VERSION "HNNBNNNYNNNNNNNNNNNNNNNNNNNNNNNNNNNNNNNNNN/4/%%%/4/'%**4NNN///"

NS_ :

BS_:

BU_: ecu_pri3_1 ecu_pri3_2 ecu_sec1_1 ecu_pri1_1 ecu_sec1_2 unused_8 unused_2 ecu_sec3_2 ecu_sec3_1 unused_1 unused_4 unused_9 unused_3 ecu_pri3_3 unused_6 unused_5 unused_7 measure

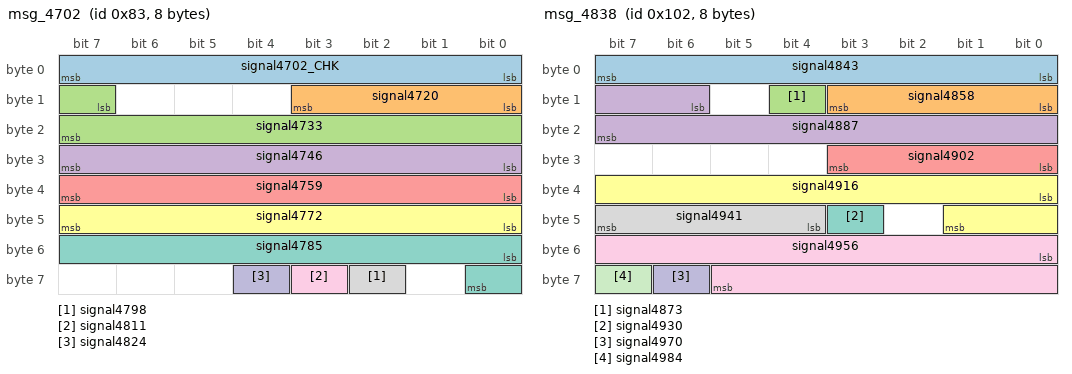
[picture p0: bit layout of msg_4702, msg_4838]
BO_ 131 msg_4702: 8 ecu_sec1_2
 SG_ signal4702_CHK : 0|8@1+ (1,0) [0|255] ""  ecu_sec3_1,unused_1,unused_4,measure
 SG_ signal4720 : 8|4@1+ (1,0) [0|15] ""  ecu_sec3_1,unused_1,unused_4,measure
 SG_ signal4733 : 15|9@1+ (25,0) [0|12750] "1/min"  ecu_sec3_1,unused_1,unused_4,measure
 SG_ signal4746 : 24|8@1+ (20,0) [0|5080] "ms"  ecu_sec3_1,unused_1,unused_4,measure
 SG_ signal4759 : 32|8@1+ (10,0) [0|2540] "Nm/s"  ecu_sec3_1,unused_1,unused_4,measure
 SG_ signal4772 : 40|8@1+ (10,0) [0|2540] "1/min"  ecu_sec3_1,unused_1,unused_4,measure
 SG_ signal4785 : 48|9@1+ (1,0) [0|509] ""  ecu_sec3_1,unused_1,unused_4,measure
 SG_ signal4798 : 58|1@1+ (1,0) [0|1] ""  ecu_sec3_1,unused_1,unused_4,measure
 SG_ signal4811 : 59|1@1+ (1,0) [0|1] ""  ecu_sec3_1,unused_1,unused_4,measure
 SG_ signal4824 : 60|1@1+ (1,0) [0|1] ""  ecu_sec3_1,unused_1,unused_4,measure

BO_ 258 msg_4838: 8 ecu_sec1_2
 SG_ signal4843 : 0|8@1+ (1,0) [0|255] ""  ecu_pri3_2,ecu_pri1_1,ecu_sec3_1,unused_1,unused_4,measure
 SG_ signal4858 : 8|4@1+ (1,0) [0|15] ""  ecu_pri3_2,ecu_pri1_1,ecu_sec3_1,unused_1,unused_4,measure
 SG_ signal4873 : 12|1@1+ (1,0) [0|1] ""  ecu_pri1_1,ecu_sec3_1,unused_1,unused_4,measure
 SG_ signal4887 : 14|10@1+ (0.1,0) [0|102.2] ""  ecu_pri3_2,ecu_pri1_1,ecu_sec3_1,unused_1,unused_4,measure
 SG_ signal4902 : 24|4@1+ (1,0) [0|15] ""  ecu_pri1_1,ecu_sec3_1,unused_1,unused_4,measure
 SG_ signal4916 : 32|10@1+ (1,0) [0|1021] ""  ecu_pri1_1,ecu_sec3_1,unused_1,unused_4,measure
 SG_ signal4930 : 43|1@1+ (1,0) [0|1] ""  ecu_pri1_1,measure
 SG_ signal4941 : 44|4@1+ (1,0) [0|15] ""  ecu_pri3_2,ecu_pri1_1,ecu_sec3_1,unused_1,unused_4,measure
 SG_ signal4956 : 48|14@1+ (1,0) [0|16381] "1/min"  ecu_pri1_1,ecu_sec3_1,unused_1,unused_4,measure
 SG_ signal4970 : 62|1@1+ (1,0) [0|1] ""  ecu_pri1_1,ecu_sec3_1,unused_1,unused_4,measure
 SG_ signal4984 : 63|1@1+ (1,0) [0|1] ""  ecu_pri3_2,ecu_pri1_1,measure

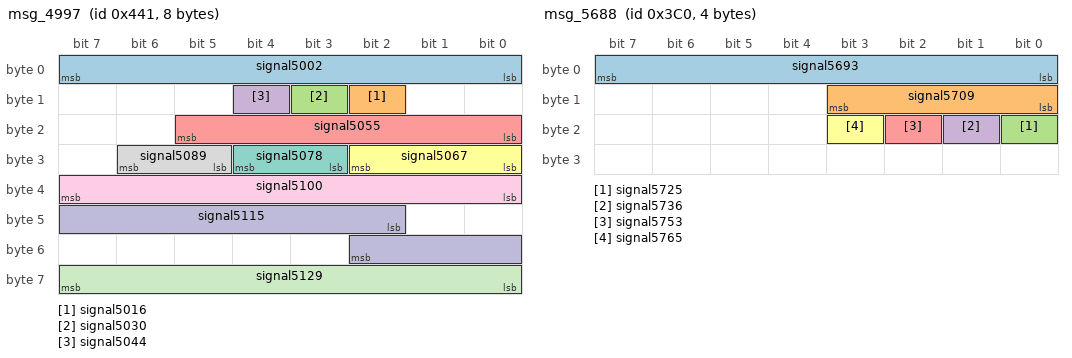
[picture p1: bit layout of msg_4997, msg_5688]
BO_ 1089 msg_4997: 8 ecu_sec1_2
 SG_ signal5002 : 0|8@1+ (0.249,-31.623) [-31.62301|31.62045] ""  ecu_pri1_1,ecu_sec3_1,unused_1,unused_4,measure
 SG_ signal5016 : 10|1@1+ (1,0) [0|1] ""  ecu_pri1_1,ecu_sec3_1,unused_1,unused_4,measure
 SG_ signal5030 : 11|1@1+ (1,0) [0|1] ""  ecu_pri1_1,ecu_sec3_1,unused_1,unused_4,measure
 SG_ signal5044 : 12|1@1+ (1,0) [0|1] ""  ecu_pri1_1,measure
 SG_ signal5055 : 16|6@1+ (2,0) [0|122] ""  ecu_pri3_2,ecu_pri1_1,measure
 SG_ signal5067 : 24|3@1+ (1,0) [0|7] ""  ecu_pri1_1,measure
 SG_ signal5078 : 27|2@1+ (1,0) [0|3] ""  ecu_pri1_1,measure
 SG_ signal5089 : 29|2@1+ (1,0) [0|3] ""  ecu_pri1_1,measure
 SG_ signal5100 : 32|8@1+ (1,0) [0|254] ""  ecu_pri3_2,ecu_pri1_1,ecu_sec3_1,unused_1,unused_4,measure
 SG_ signal5115 : 42|9@1+ (0.024,-2.016) [-2.01601|10.22399] "signal5121"  ecu_pri1_1,ecu_sec3_1,unused_1,unused_4,measure
 SG_ signal5129 : 56|8@1+ (1,-58) [-58|196] "Celsius"  ecu_pri1_1,ecu_sec3_1,unused_1,unused_4,measure

BO_ 1813 msg_5144: 8 ecu_pri1_1
 SG_ signal5144_Data : 0|64@1+ (1,0) [0|1] ""  ecu_pri3_1,measure

BO_ 1792 msg_5178: 8 ecu_pri1_1
 SG_ signal5183 : 0|64@1+ (1,0) [0|1] ""  ecu_pri3_1,ecu_sec1_2,unused_8,unused_2,ecu_sec3_1,unused_1,unused_4,unused_9,unused_5,measure

BO_ 2015 msg_5203: 8 ecu_pri1_1
 SG_ signal5208 : 0|64@1+ (1,0) [0|1] ""  ecu_pri3_1,ecu_sec1_2,unused_8,unused_2,ecu_sec3_1,unused_1,unused_4,unused_9,measure

BO_ 2017 msg_5227: 8 ecu_pri1_1
 SG_ signal5227_Data : 0|64@1+ (1,0) [0|1] ""  ecu_sec1_2,unused_8,unused_2,measure

BO_ 2025 msg_5246: 8 ecu_sec1_2
 SG_ signal5251 : 0|64@1+ (1,0) [0|1] ""  ecu_pri1_1,measure

BO_ 2016 msg_5263: 8 ecu_pri1_1
 SG_ signal5263_Data : 0|64@1+ (1,0) [0|1] ""  ecu_sec3_1,unused_1,unused_4,measure

BO_ 2024 msg_5282: 8 ecu_sec3_1
 SG_ signal5282_Data : 0|64@1+ (1,0) [0|1] ""  ecu_pri1_1,measure

BO_ 2018 msg_5299: 8 ecu_pri1_1
 SG_ signal5304 : 0|64@1+ (1,0) [0|1] ""  unused_9,measure

BO_ 2026 msg_5316: 8 unused_9
 SG_ signal5321 : 0|64@1+ (1,0) [0|1] ""  ecu_pri1_1,measure

BO_ 2019 msg_5333: 8 ecu_pri1_1
 SG_ signal5333_Data : 0|64@1+ (1,0) [0|1] ""  unused_7,measure

BO_ 2027 msg_5349: 8 unused_7
 SG_ signal5349_Data : 0|64@1+ (1,0) [0|1] ""  ecu_pri1_1,measure

BO_ 1875 msg_5366: 8 ecu_pri1_1
 SG_ signal5371 : 0|64@1+ (1,0) [0|1] ""  unused_5,measure

BO_ 1981 msg_5383: 8 unused_5
 SG_ signal5388 : 0|64@1+ (1,0) [0|1] ""  ecu_pri1_1,measure

BO_ 1424 msg_5400: 8 ecu_pri1_1
 SG_ signal5405 : 0|4@1+ (1,0) [0|15] ""  unused_7,measure
 SG_ signal5415 : 4|1@1+ (1,0) [0|1] ""  unused_7,measure
 SG_ signal5425 : 5|1@1+ (1,0) [0|1] ""  unused_7,measure
 SG_ signal5435 : 6|2@1+ (1,0) [0|3] ""  unused_7,measure
 SG_ signal5445 : 8|1@1+ (1,0) [0|1] ""  unused_7,measure
 SG_ signal5455 : 9|1@1+ (1,0) [0|1] ""  unused_7,measure
 SG_ signal5465 : 10|1@1+ (1,0) [0|1] ""  ecu_pri3_2,measure
 SG_ signal5476 : 11|1@1+ (1,0) [0|1] ""  ecu_pri3_2,measure
 SG_ signal5487 : 12|1@1+ (1,0) [0|1] ""  unused_7,measure
 SG_ signal5497 : 14|1@1+ (1,0) [0|1] ""  unused_7,measure
 SG_ signal5507 : 15|1@1+ (1,0) [0|1] ""  unused_7,measure
 SG_ signal5517 : 16|3@1+ (1,0) [0|7] ""  unused_7,measure
 SG_ signal5527 : 19|1@1+ (1,0) [0|1] ""  unused_7,measure
 SG_ signal5537 : 20|1@1+ (1,0) [0|1] ""  unused_7,measure
 SG_ signal5547 : 21|1@1+ (1,0) [0|1] ""  unused_7,measure
 SG_ signal5557 : 22|1@1+ (1,0) [0|1] ""  unused_7,measure
 SG_ signal5567 : 23|1@1+ (1,0) [0|1] ""  unused_7,measure
 SG_ signal5577 : 24|3@1+ (1,0) [0|7] ""  unused_7,measure
 SG_ signal5587 : 27|1@1+ (1,0) [0|1] ""  unused_7,measure
 SG_ signal5597 : 28|1@1+ (1,0) [0|1] ""  unused_7,measure
 SG_ signal5607 : 29|1@1+ (1,0) [0|1] ""  unused_7,measure
 SG_ signal5617 : 30|1@1+ (1,0) [0|1] ""  unused_7,measure
 SG_ signal5627 : 31|1@1+ (1,0) [0|1] ""  unused_7,measure
 SG_ signal5637 : 32|4@1+ (1,0) [0|15] ""  unused_7,measure
 SG_ signal5647 : 36|4@1+ (1,0) [0|15] ""  unused_7,measure
 SG_ signal5657 : 40|1@1+ (1,0) [0|1] ""  unused_7,measure
 SG_ signal5667 : 41|2@1+ (1,0) [0|3] ""  unused_7,measure
 SG_ signal5677 : 47|1@1+ (1,0) [0|1] ""  unused_7,measure

BO_ 960 msg_5688: 4 ecu_pri1_1
 SG_ signal5693 : 0|8@1+ (1,0) [0|255] ""  ecu_pri3_2,ecu_sec1_2,unused_8,ecu_sec3_1,unused_1,unused_4,measure
 SG_ signal5709 : 8|4@1+ (1,0) [0|15] ""  ecu_pri3_2,ecu_sec1_2,unused_8,ecu_sec3_1,unused_1,unused_4,measure
 SG_ signal5725 : 16|1@1+ (1,0) [0|1] ""  ecu_pri3_2,measure
 SG_ signal5736 : 17|1@1+ (1,0) [0|1] ""  ecu_pri3_2,ecu_sec1_2,unused_8,ecu_sec3_1,unused_1,unused_4,unused_6,measure
 SG_ signal5753 : 18|1@1+ (1,0) [0|1] ""  ecu_pri3_2,unused_6,measure
 SG_ signal5765 : 19|1@1+ (1,0) [0|1] ""  ecu_pri3_2,ecu_sec3_1,unused_1,unused_4,measure

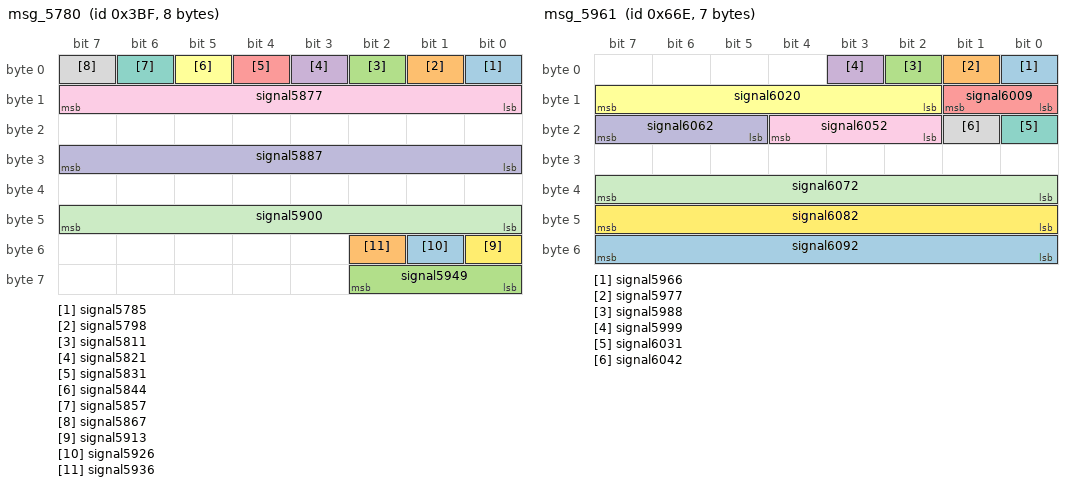
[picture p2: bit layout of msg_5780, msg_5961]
BO_ 959 msg_5780: 8 ecu_pri1_1
 SG_ signal5785 : 0|1@1+ (1,0) [0|1] ""  ecu_sec3_1,unused_1,unused_4,measure
 SG_ signal5798 : 1|1@1+ (1,0) [0|1] ""  ecu_sec3_1,unused_1,unused_4,measure
 SG_ signal5811 : 2|1@1+ (1,0) [0|1] ""  unused_7,measure
 SG_ signal5821 : 3|1@1+ (1,0) [0|1] ""  unused_7,measure
 SG_ signal5831 : 4|1@1+ (1,0) [0|1] ""  ecu_sec3_1,unused_1,unused_4,measure
 SG_ signal5844 : 5|1@1+ (1,0) [0|1] ""  ecu_sec3_1,unused_1,unused_4,measure
 SG_ signal5857 : 6|1@1+ (1,0) [0|1] ""  unused_7,measure
 SG_ signal5867 : 7|1@1+ (1,0) [0|1] ""  unused_7,measure
 SG_ signal5877 : 8|8@1+ (11,0) [0|2805] "W"  unused_7,measure
 SG_ signal5887 : 24|8@1+ (0.25,0) [0|63.5] "Nm"  ecu_sec3_1,unused_1,unused_4,measure
 SG_ signal5900 : 40|8@1+ (0.4,0) [0|101.6] "%"  ecu_sec3_1,unused_1,unused_4,measure
 SG_ signal5913 : 48|1@1+ (1,0) [0|1] ""  ecu_sec3_1,unused_1,unused_4,measure
 SG_ signal5926 : 49|1@1+ (1,0) [0|1] ""  unused_7,measure
 SG_ signal5936 : 50|1@1+ (1,0) [0|1] ""  ecu_sec3_1,unused_1,unused_4,measure
 SG_ signal5949 : 56|3@1+ (1,0) [0|7] ""  ecu_sec3_1,measure

BO_ 1646 msg_5961: 7 ecu_pri1_1
 SG_ signal5966 : 0|1@1+ (1,0) [0|1] ""  unused_6,measure
 SG_ signal5977 : 1|1@1+ (1,0) [0|1] ""  unused_6,measure
 SG_ signal5988 : 2|1@1+ (1,0) [0|1] ""  unused_6,measure
 SG_ signal5999 : 3|1@1+ (1,0) [0|1] ""  unused_7,measure
 SG_ signal6009 : 8|2@1+ (1,0) [0|3] ""  unused_6,measure
 SG_ signal6020 : 10|6@1+ (1,0) [0|60] "min"  unused_6,measure
 SG_ signal6031 : 16|1@1+ (1,0) [0|1] ""  unused_6,measure
 SG_ signal6042 : 17|1@1+ (1,0) [0|1] ""  unused_7,measure
 SG_ signal6052 : 18|3@1+ (1,0) [0|7] ""  unused_7,measure
 SG_ signal6062 : 21|3@1+ (1,0) [0|7] ""  unused_7,measure
 SG_ signal6072 : 32|8@1+ (0.5,-50) [-50|76] "Celsius"  unused_7,measure
 SG_ signal6082 : 40|8@1+ (10,0) [0|1000] "W/m2"  unused_7,measure
 SG_ signal6092 : 48|8@1+ (0.5,-50) [-50|76] "Celsius"  unused_7,measure

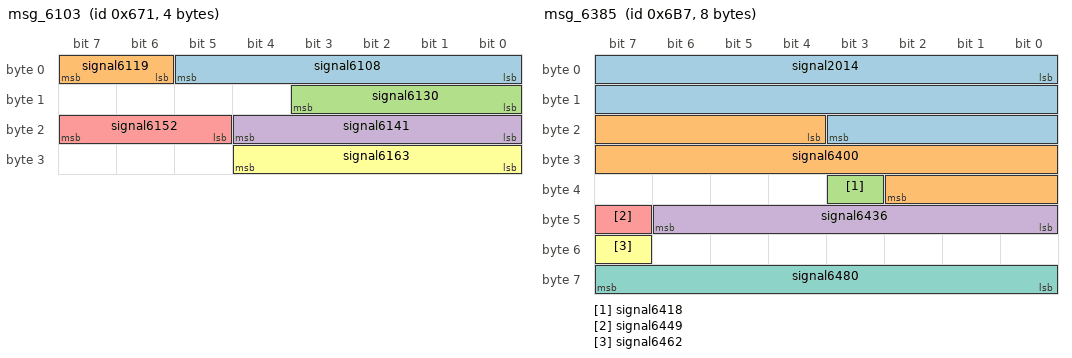
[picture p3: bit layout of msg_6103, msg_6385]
BO_ 1649 msg_6103: 4 ecu_pri1_1
 SG_ signal6108 : 0|6@1+ (1,0) [0|63] ""  unused_6,measure
 SG_ signal6119 : 6|2@1+ (1,0) [0|3] ""  unused_6,measure
 SG_ signal6130 : 8|4@1+ (1,0) [0|15] ""  unused_6,measure
 SG_ signal6141 : 16|5@1+ (1,0) [0|31] ""  unused_6,measure
 SG_ signal6152 : 21|3@1+ (1,0) [0|7] ""  unused_6,measure
 SG_ signal6163 : 24|5@1+ (1,0) [0|31] "Tag"  unused_6,measure

BO_ 779 msg_6175: 8 ecu_pri1_1
 SG_ signal6180 : 0|1@1+ (1,0) [0|1] ""  unused_7,measure
 SG_ signal6190 : 1|1@1+ (1,0) [0|1] ""  unused_7,measure
 SG_ signal6200 : 2|1@1+ (1,0) [0|1] ""  unused_7,measure
 SG_ signal6210 : 3|1@1+ (1,0) [0|1] ""  unused_7,measure
 SG_ signal6220 : 4|1@1+ (1,0) [0|1] ""  unused_7,measure
 SG_ signal6230 : 5|1@1+ (1,0) [0|1] ""  unused_7,measure
 SG_ signal6240 : 6|1@1+ (1,0) [0|1] ""  unused_7,measure
 SG_ signal6250 : 16|1@1+ (1,0) [0|1] ""  ecu_sec3_1,unused_4,unused_6,measure
 SG_ signal6263 : 17|1@1+ (1,0) [0|1] ""  ecu_sec3_1,unused_4,measure
 SG_ signal6275 : 18|1@1+ (1,0) [0|1] ""  unused_7,measure
 SG_ signal6285 : 19|2@1+ (1,0) [0|3] ""  unused_7,measure
 SG_ signal6295 : 21|1@1+ (1,0) [0|1] ""  unused_7,measure
 SG_ signal6305 : 22|1@1+ (1,0) [0|1] ""  unused_7,measure
 SG_ signal6315 : 48|10@1+ (0.32,0) [0|325.12] "km/h"  ecu_sec1_2,unused_8,unused_2,ecu_sec3_1,unused_4,measure
 SG_ signal6330 : 58|1@1+ (1,0) [0|1] ""  ecu_sec1_2,unused_8,ecu_sec3_1,unused_4,measure
 SG_ signal6344 : 59|1@1+ (1,0) [0|1] ""  unused_7,measure
 SG_ signal6354 : 60|1@1+ (1,0) [0|1] ""  unused_7,measure
 SG_ signal6364 : 61|2@1+ (1,0) [0|3] ""  unused_7,measure
 SG_ signal6374 : 63|1@1+ (1,0) [0|1] ""  unused_7,measure

BO_ 1719 msg_6385: 8 ecu_pri1_1
 SG_ signal2014 : 0|20@1+ (1,0) [0|1048573] "km"  unused_7,measure
 SG_ signal6400 : 20|15@1+ (4,0) [0|131068] "s"  ecu_pri3_2,ecu_sec1_2,unused_8,unused_2,ecu_sec3_1,unused_1,unused_4,unused_6,measure
 SG_ signal6418 : 35|1@1+ (1,0) [0|1] ""  ecu_pri3_2,ecu_sec1_2,unused_8,unused_2,ecu_sec3_1,unused_1,unused_4,unused_6,measure
 SG_ signal6436 : 40|7@1+ (1,0) [0|126] "l"  ecu_sec3_1,unused_1,unused_4,measure
 SG_ signal6449 : 47|1@1+ (1,0) [0|1] ""  ecu_sec3_1,unused_1,unused_4,measure
 SG_ signal6462 : 55|1@1+ (1,0) [0|1] ""  ecu_pri3_2,ecu_sec1_2,unused_8,unused_2,ecu_sec3_1,unused_1,unused_4,unused_6,measure
 SG_ signal6480 : 56|8@1+ (0.5,-50) [-50|75] "Celsius"  ecu_pri3_2,ecu_sec1_2,unused_8,unused_2,ecu_sec3_1,unused_1,unused_4,unused_6,measure

BO_ 1720 msg_6499: 8 ecu_pri1_1
 SG_ signal6504 : 0|12@1+ (1,0) [0|4095] "mm"  ecu_sec1_2,unused_8,unused_2,measure

BO_ 517 msg_6518: 8 ecu_pri3_1
 SG_ signal6518_Data : 0|64@1+ (1,0) [0|1] ""  ecu_pri1_1,measure

BO_ 640 msg_6535: 8 ecu_pri1_1
 SG_ signal6535_Data : 0|64@1+ (1,0) [0|1] ""  ecu_pri3_1,measure

BO_ 1137 msg_6552: 8 ecu_pri1_1
 SG_ signal6552_BZ : 0|4@1+ (1,0) [0|15] ""  ecu_sec3_1,unused_4,measure
 SG_ signal6569 : 5|1@1+ (1,0) [0|1] ""  ecu_sec3_1,unused_4,measure
 SG_ signal6581 : 7|1@1+ (1,0) [0|1] ""  unused_7,measure
 SG_ signal6591 : 8|1@1+ (1,0) [0|1] ""  unused_7,measure
 SG_ signal6601 : 9|1@1+ (1,0) [0|1] ""  unused_7,measure
 SG_ signal6611 : 10|1@1+ (1,0) [0|1] ""  unused_7,measure
 SG_ signal6621 : 11|1@1+ (1,0) [0|1] ""  unused_7,measure
 SG_ signal6631 : 12|1@1+ (1,0) [0|1] ""  unused_7,measure
 SG_ signal6641 : 13|1@1+ (1,0) [0|1] ""  unused_7,measure
 SG_ signal6651 : 14|1@1+ (1,0) [0|1] ""  unused_7,measure
 SG_ signal6661 : 15|1@1+ (1,0) [0|1] ""  unused_7,measure
 SG_ signal6671 : 16|1@1+ (1,0) [0|1] ""  unused_7,measure
 SG_ signal6681 : 17|1@1+ (1,0) [0|1] ""  unused_7,measure
 SG_ signal6691 : 18|1@1+ (1,0) [0|1] ""  unused_7,measure
 SG_ signal6701 : 19|1@1+ (1,0) [0|1] ""  unused_7,measure
 SG_ signal6711 : 20|1@1+ (1,0) [0|1] ""  unused_7,measure
 SG_ signal6721 : 24|1@1+ (1,0) [0|1] ""  unused_7,measure
 SG_ signal6731 : 25|1@1+ (1,0) [0|1] ""  unused_7,measure
 SG_ signal6741 : 26|1@1+ (1,0) [0|1] ""  unused_7,measure
 SG_ signal6751 : 27|1@1+ (1,0) [0|1] ""  unused_7,measure
 SG_ signal6761 : 32|1@1+ (1,0) [0|1] ""  unused_7,measure
 SG_ signal6771 : 33|1@1+ (1,0) [0|1] ""  unused_7,measure
 SG_ signal6781 : 34|1@1+ (1,0) [0|1] ""  unused_7,measure
 SG_ signal6791 : 35|1@1+ (1,0) [0|1] ""  unused_7,measure
 SG_ signal6801 : 36|1@1+ (1,0) [0|1] ""  unused_7,measure
 SG_ signal6811 : 40|1@1+ (1,0) [0|1] ""  unused_7,measure
 SG_ signal6821 : 41|1@1+ (1,0) [0|1] ""  unused_7,measure
 SG_ signal6831 : 42|1@1+ (1,0) [0|1] ""  unused_7,measure
 SG_ signal6841 : 43|1@1+ (1,0) [0|1] ""  unused_7,measure
 SG_ signal6851 : 48|1@1+ (1,0) [0|1] ""  unused_7,measure
 SG_ signal6861 : 49|1@1+ (1,0) [0|1] ""  ecu_sec3_1,unused_4,measure
 SG_ signal6873 : 50|1@1+ (1,0) [0|1] ""  unused_7,measure
 SG_ signal6883 : 51|1@1+ (1,0) [0|1] ""  unused_7,measure
 SG_ signal6893 : 54|1@1+ (1,0) [0|1] ""  ecu_sec3_1,unused_4,measure
 SG_ signal6905 : 55|1@1+ (1,0) [0|1] ""  ecu_sec3_1,unused_4,measure

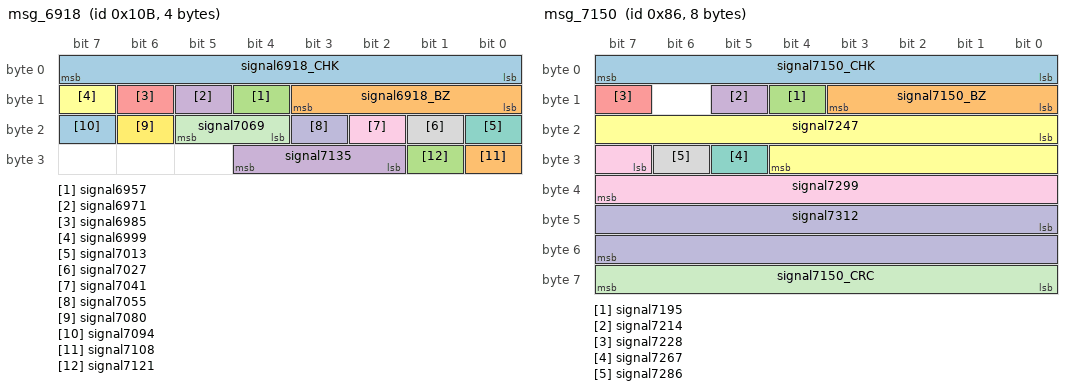
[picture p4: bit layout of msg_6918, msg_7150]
BO_ 267 msg_6918: 4 ecu_sec3_2
 SG_ signal6918_CHK : 0|8@1+ (1,0) [0|255] ""  ecu_pri1_1,ecu_sec1_2,unused_8,unused_2,ecu_sec3_1,unused_1,unused_4,measure
 SG_ signal6918_BZ : 8|4@1+ (1,0) [0|15] ""  ecu_pri1_1,ecu_sec1_2,unused_8,unused_2,ecu_sec3_1,unused_1,unused_4,measure
 SG_ signal6957 : 12|1@1+ (1,0) [0|1] ""  ecu_pri1_1,ecu_sec3_1,unused_1,unused_4,measure
 SG_ signal6971 : 13|1@1+ (1,0) [0|1] ""  ecu_pri1_1,ecu_sec3_1,unused_1,unused_4,measure
 SG_ signal6985 : 14|1@1+ (1,0) [0|1] ""  ecu_pri1_1,ecu_sec3_1,unused_1,unused_4,measure
 SG_ signal6999 : 15|1@1+ (1,0) [0|1] ""  ecu_pri1_1,ecu_sec3_1,unused_1,unused_4,measure
 SG_ signal7013 : 16|1@1+ (1,0) [0|1] ""  ecu_pri1_1,ecu_sec3_1,unused_1,unused_4,measure
 SG_ signal7027 : 17|1@1+ (1,0) [0|1] ""  ecu_pri1_1,ecu_sec3_1,unused_1,unused_4,measure
 SG_ signal7041 : 18|1@1+ (1,0) [0|1] ""  ecu_pri1_1,ecu_sec3_1,unused_1,unused_4,measure
 SG_ signal7055 : 19|1@1+ (1,0) [0|1] ""  ecu_pri1_1,ecu_sec3_1,unused_1,unused_4,measure
 SG_ signal7069 : 20|2@1+ (1,0) [0|3] ""  ecu_pri1_1,measure
 SG_ signal7080 : 22|1@1+ (1,0) [0|1] ""  ecu_pri1_1,ecu_sec1_2,unused_8,unused_2,measure
 SG_ signal7094 : 23|1@1+ (1,0) [0|1] ""  ecu_pri1_1,ecu_sec1_2,unused_8,unused_2,measure
 SG_ signal7108 : 24|1@1+ (1,0) [0|1] ""  ecu_pri1_1,ecu_sec1_2,unused_8,measure
 SG_ signal7121 : 25|1@1+ (1,0) [0|1] ""  ecu_pri1_1,ecu_sec3_1,unused_1,unused_4,measure
 SG_ signal7135 : 26|3@1+ (1,0) [0|7] ""  ecu_pri1_1,ecu_sec3_1,unused_1,unused_4,measure

BO_ 134 msg_7150: 8 ecu_sec3_2
 SG_ signal7150_CHK : 0|8@1+ (1,0) [0|255] ""  ecu_sec1_1,ecu_pri1_1,ecu_sec1_2,unused_8,unused_2,ecu_sec3_1,unused_1,unused_4,unused_3,ecu_pri3_3,measure
 SG_ signal7150_BZ : 8|4@1+ (1,0) [0|15] ""  ecu_sec1_1,ecu_pri1_1,ecu_sec1_2,unused_8,unused_2,ecu_sec3_1,unused_1,unused_4,unused_3,ecu_pri3_3,measure
 SG_ signal7195 : 12|1@1+ (1,0) [0|1] ""  ecu_sec1_1,ecu_pri1_1,ecu_sec1_2,unused_8,ecu_sec3_1,unused_1,unused_4,unused_3,ecu_pri3_3,measure
 SG_ signal7214 : 13|1@1+ (1,0) [0|1] ""  ecu_sec1_1,ecu_pri1_1,unused_3,ecu_pri3_3,measure
 SG_ signal7228 : 15|1@1+ (1,0) [0|1] ""  ecu_sec1_1,ecu_pri1_1,ecu_sec1_2,unused_8,ecu_sec3_1,unused_1,unused_4,unused_3,ecu_pri3_3,measure
 SG_ signal7247 : 16|13@1+ (0.1,0) [0|800] "Degr"  ecu_sec1_1,ecu_pri1_1,ecu_sec1_2,unused_8,unused_2,ecu_sec3_1,unused_1,unused_4,unused_3,ecu_pri3_3,measure
 SG_ signal7267 : 29|1@1+ (1,0) [0|1] ""  ecu_sec1_1,ecu_pri1_1,ecu_sec1_2,unused_8,ecu_sec3_1,unused_1,unused_4,unused_3,ecu_pri3_3,measure
 SG_ signal7286 : 30|1@1+ (1,0) [0|1] ""  ecu_sec1_1,ecu_pri1_1,unused_3,measure
 SG_ signal7299 : 31|9@1+ (5,0) [0|2500] "Deg/s"  ecu_sec1_1,ecu_pri1_1,unused_3,measure
 SG_ signal7312 : 40|16@1+ (1,0) [0|65535] ""  ecu_sec1_1,ecu_pri1_1,unused_3,ecu_pri3_3,measure
 SG_ signal7150_CRC : 56|8@1+ (1,0) [0|255] ""  ecu_sec1_1,ecu_pri1_1,unused_3,ecu_pri3_3,measure

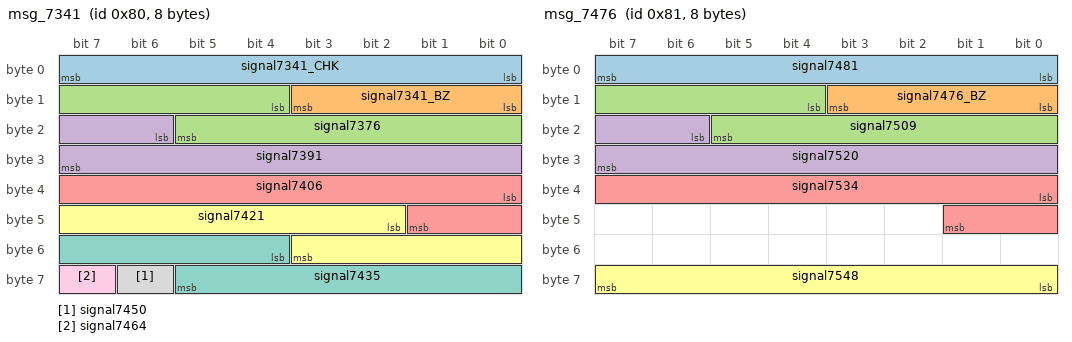
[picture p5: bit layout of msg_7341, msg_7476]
BO_ 128 msg_7341: 8 ecu_sec3_1
 SG_ signal7341_CHK : 0|8@1+ (1,0) [0|255] ""  ecu_pri3_2,ecu_pri1_1,ecu_sec1_2,unused_8,unused_2,measure
 SG_ signal7341_BZ : 8|4@1+ (1,0) [0|15] ""  ecu_pri3_2,ecu_pri1_1,ecu_sec1_2,unused_8,unused_2,measure
 SG_ signal7376 : 12|10@1+ (1,0) [0|1021] ""  ecu_pri3_2,ecu_pri1_1,ecu_sec1_2,unused_8,unused_2,measure
 SG_ signal7391 : 22|10@1+ (1,0) [0|1021] ""  ecu_pri3_2,ecu_pri1_1,ecu_sec1_2,unused_8,unused_2,measure
 SG_ signal7406 : 32|10@1+ (1,0) [0|1021] ""  ecu_pri3_2,ecu_pri1_1,ecu_sec1_2,unused_8,unused_2,measure
 SG_ signal7421 : 42|10@1+ (1,0) [0|1021] ""  ecu_pri1_1,ecu_sec1_2,unused_8,unused_2,measure
 SG_ signal7435 : 52|10@1+ (1,0) [0|1021] ""  ecu_pri3_2,ecu_pri1_1,ecu_sec1_2,unused_8,unused_2,measure
 SG_ signal7450 : 62|1@1+ (1,0) [0|1] ""  ecu_pri1_1,ecu_sec1_2,unused_8,unused_2,measure
 SG_ signal7464 : 63|1@1+ (1,0) [0|1] ""  ecu_pri1_1,measure

BO_ 129 msg_7476: 8 ecu_sec3_1
 SG_ signal7481 : 0|8@1+ (1,0) [0|255] ""  ecu_pri1_1,ecu_sec1_2,unused_8,unused_2,measure
 SG_ signal7476_BZ : 8|4@1+ (1,0) [0|15] ""  ecu_pri1_1,ecu_sec1_2,unused_8,unused_2,measure
 SG_ signal7509 : 12|10@1+ (1,0) [0|1021] ""  ecu_pri1_1,measure
 SG_ signal7520 : 22|10@1+ (1,0) [0|1021] ""  ecu_pri1_1,ecu_sec1_2,unused_8,unused_2,measure
 SG_ signal7534 : 32|10@1+ (1,0) [0|1021] ""  ecu_pri1_1,ecu_sec1_2,unused_8,unused_2,measure
 SG_ signal7548 : 56|8@1+ (0.3921,0) [0|99.9855] ""  ecu_pri1_1,ecu_sec1_2,unused_8,unused_2,measure

BO_ 261 msg_7563: 8 ecu_sec3_1
 SG_ signal7563_CHK : 0|8@1+ (1,0) [0|255] ""  ecu_pri3_2,ecu_pri1_1,ecu_sec1_2,unused_8,unused_2,ecu_pri3_3,measure
 SG_ signal7563_BZ : 8|4@1+ (1,0) [0|15] ""  ecu_pri3_2,ecu_pri1_1,ecu_sec1_2,unused_8,unused_2,ecu_pri3_3,measure
 SG_ signal7600 : 12|1@1+ (1,0) [0|1] ""  ecu_pri3_2,ecu_pri1_1,measure
 SG_ signal7612 : 13|1@1+ (1,0) [0|1] ""  ecu_pri3_2,ecu_pri1_1,ecu_sec1_2,unused_8,unused_2,measure
 SG_ signal7627 : 14|1@1+ (1,0) [0|1] ""  ecu_pri1_1,ecu_sec1_2,unused_8,unused_2,measure
 SG_ signal7641 : 15|1@1+ (1,0) [0|1] ""  ecu_pri1_1,unused_6,measure
 SG_ signal7653 : 16|16@1+ (0.25,0) [0|16383] "1/min"  ecu_pri3_2,ecu_pri1_1,ecu_pri3_3,unused_6,measure
 SG_ signal7667 : 32|1@1+ (1,0) [0|1] ""  ecu_pri1_1,measure
 SG_ signal7678 : 33|1@1+ (1,0) [0|1] ""  ecu_pri3_2,ecu_pri1_1,measure
 SG_ signal7690 : 34|1@1+ (1,0) [0|1] ""  ecu_pri3_2,ecu_pri1_1,ecu_sec1_2,unused_8,unused_2,measure
 SG_ signal7705 : 35|1@1+ (1,0) [0|1] ""  ecu_pri1_1,ecu_sec1_2,unused_8,unused_2,measure
 SG_ signal7719 : 36|1@1+ (1,0) [0|1] ""  ecu_pri1_1,ecu_sec1_2,unused_8,unused_2,measure
 SG_ signal7733 : 37|1@1+ (1,0) [0|1] ""  ecu_pri3_2,ecu_pri1_1,measure
 SG_ signal7745 : 38|1@1+ (1,0) [0|1] ""  ecu_pri1_1,measure
 SG_ signal7756 : 39|1@1+ (1,0) [0|1] ""  ecu_pri3_2,ecu_pri1_1,ecu_pri3_3,measure
 SG_ signal7769 : 40|8@1+ (10,0) [0|2540] "1/min"  ecu_pri1_1,ecu_sec1_2,unused_8,unused_2,measure
 SG_ signal7783 : 48|8@1+ (0.4,0) [0|101.6] "%"  ecu_pri3_2,ecu_pri1_1,measure
 SG_ signal7795 : 56|1@1+ (1,0) [0|1] ""  ecu_pri1_1,ecu_sec1_2,unused_8,unused_2,measure
 SG_ signal7809 : 57|1@1+ (1,0) [0|1] ""  ecu_pri1_1,ecu_sec1_2,unused_8,unused_2,measure
 SG_ signal7823 : 58|6@1+ (1.6,0) [0|100.8] "%"  ecu_pri1_1,ecu_sec1_2,unused_8,unused_2,measure

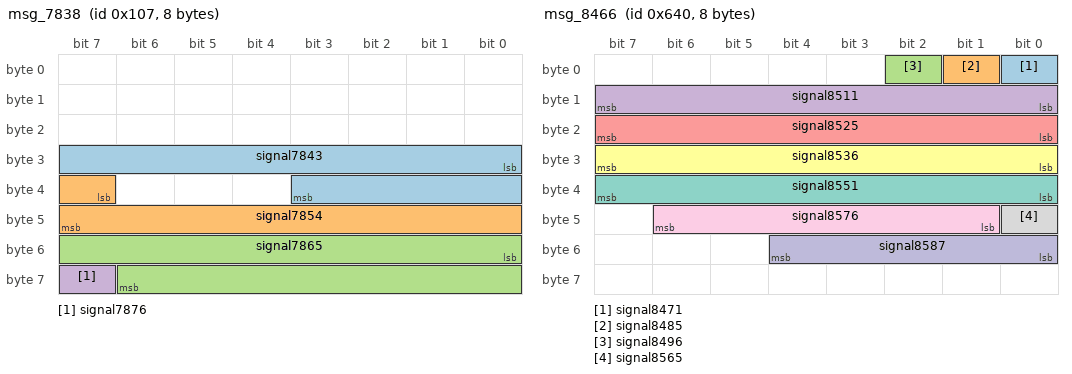
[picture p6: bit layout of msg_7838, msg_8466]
BO_ 263 msg_7838: 8 ecu_sec3_1
 SG_ signal7843 : 24|12@1+ (3,0) [0|12282] "1/min"  ecu_pri1_1,measure
 SG_ signal7854 : 39|9@1+ (0.01,0) [0|5.1] "bar"  ecu_pri1_1,measure
 SG_ signal7865 : 48|15@1+ (1,0) [0|32767] "ul"  ecu_pri1_1,measure
 SG_ signal7876 : 63|1@1+ (1,0) [0|1] ""  ecu_pri1_1,measure

BO_ 782 msg_7888: 8 ecu_sec3_1
 SG_ signal7888_CHK : 0|8@1+ (1,0) [0|255] ""  ecu_sec1_2,unused_8,unused_2,measure
 SG_ signal7888_BZ : 8|4@1+ (1,0) [0|15] ""  ecu_sec1_2,unused_8,unused_2,measure
 SG_ signal7919 : 16|2@1+ (1,0) [0|3] ""  ecu_pri1_1,measure
 SG_ signal7930 : 18|1@1+ (1,0) [0|1] ""  ecu_sec1_2,unused_8,measure
 SG_ signal7942 : 19|1@1+ (1,0) [0|1] ""  ecu_sec1_2,unused_8,measure
 SG_ signal7954 : 20|1@1+ (1,0) [0|1] ""  ecu_sec1_2,unused_8,measure
 SG_ signal7966 : 21|1@1+ (1,0) [0|1] ""  ecu_sec1_2,unused_8,unused_2,measure
 SG_ signal7979 : 22|1@1+ (1,0) [0|1] ""  ecu_pri1_1,measure
 SG_ signal7990 : 23|1@1+ (1,0) [0|1] ""  ecu_pri1_1,measure
 SG_ signal8001 : 24|9@1+ (25,0) [0|12750] "1/min"  ecu_sec1_2,unused_8,unused_2,measure
 SG_ signal8014 : 33|1@1+ (1,0) [0|1] ""  ecu_sec1_2,unused_8,unused_2,measure
 SG_ signal8027 : 34|1@1+ (1,0) [0|1] ""  ecu_sec1_2,unused_8,measure
 SG_ signal8039 : 35|1@1+ (1,0) [0|1] ""  unused_7,measure
 SG_ signal8049 : 36|1@1+ (1,0) [0|1] ""  unused_7,measure
 SG_ signal8059 : 37|1@1+ (1,0) [0|1] ""  ecu_pri1_1,measure
 SG_ signal8070 : 38|1@1+ (1,0) [0|1] ""  ecu_pri1_1,measure
 SG_ signal8081 : 39|1@1+ (1,0) [0|1] ""  ecu_pri1_1,measure
 SG_ signal8092 : 40|3@1+ (1,0) [0|7] ""  ecu_pri1_1,measure
 SG_ signal8103 : 43|2@1+ (1,0) [0|3] ""  ecu_pri1_1,measure
 SG_ signal8114 : 45|2@1+ (1,0) [0|3] ""  ecu_pri1_1,measure
 SG_ signal4168 : 47|1@1+ (1,0) [0|1] ""  ecu_pri1_1,measure
 SG_ signal8136 : 48|8@1+ (25,0) [0|6350] "1/min"  ecu_sec1_2,unused_8,unused_2,measure
 SG_ signal8149 : 56|8@1+ (0.39,0) [0|99.45] "%"  ecu_sec1_2,unused_8,unused_2,measure

BO_ 1088 msg_8163: 8 ecu_sec3_1
 SG_ signal8168 : 12|1@1+ (1,0) [0|1] ""  ecu_pri1_1,measure
 SG_ signal8179 : 13|1@1+ (1,0) [0|1] ""  ecu_pri1_1,measure
 SG_ signal8190 : 14|1@1+ (1,0) [0|1] ""  ecu_pri1_1,measure
 SG_ signal8201 : 15|1@1+ (1,0) [0|1] ""  ecu_pri1_1,measure
 SG_ signal8212 : 16|4@1+ (12.5,0) [0|100] "%"  ecu_pri1_1,measure
 SG_ signal8223 : 24|1@1+ (1,0) [0|1] ""  ecu_pri1_1,measure
 SG_ signal8234 : 25|1@1+ (1,0) [0|1] ""  ecu_pri1_1,measure
 SG_ signal8245 : 26|1@1+ (1,0) [0|1] ""  ecu_pri1_1,measure
 SG_ signal8256 : 27|1@1+ (1,0) [0|1] ""  ecu_pri1_1,measure
 SG_ signal8267 : 40|1@1+ (1,0) [0|1] ""  ecu_pri1_1,measure
 SG_ signal8278 : 41|1@1+ (1,0) [0|1] ""  ecu_pri1_1,measure
 SG_ signal8289 : 42|1@1+ (1,0) [0|1] ""  ecu_pri1_1,measure
 SG_ signal8300 : 43|5@1+ (125,0) [0|3875] "ml"  ecu_pri1_1,measure
 SG_ signal8311 : 48|1@1+ (1,0) [0|1] ""  ecu_pri1_1,measure
 SG_ signal8322 : 49|1@1+ (1,0) [0|1] ""  ecu_pri1_1,measure
 SG_ signal8333 : 50|1@1+ (1,0) [0|1] ""  ecu_pri1_1,measure
 SG_ signal8344 : 51|1@1+ (1,0) [0|1] ""  ecu_pri1_1,measure
 SG_ signal8355 : 52|1@1+ (1,0) [0|1] ""  ecu_pri1_1,measure
 SG_ signal8366 : 53|1@1+ (1,0) [0|1] ""  ecu_pri1_1,measure
 SG_ signal8377 : 54|1@1+ (1,0) [0|1] ""  ecu_pri1_1,measure
 SG_ signal8388 : 55|1@1+ (1,0) [0|1] ""  ecu_pri1_1,measure
 SG_ signal8399 : 56|1@1+ (1,0) [0|1] ""  ecu_pri1_1,measure
 SG_ signal8410 : 57|1@1+ (1,0) [0|1] ""  ecu_pri1_1,measure
 SG_ signal8421 : 58|1@1+ (1,0) [0|1] ""  ecu_pri1_1,measure
 SG_ signal8432 : 59|1@1+ (1,0) [0|1] ""  ecu_pri1_1,measure
 SG_ signal8443 : 60|1@1+ (1,0) [0|1] ""  ecu_pri1_1,measure
 SG_ signal8454 : 61|2@1+ (1,0) [0|3] ""  ecu_pri1_1,measure

BO_ 1600 msg_8466: 8 ecu_sec3_1
 SG_ signal8471 : 0|1@1+ (1,0) [0|1] ""  ecu_pri1_1,ecu_sec1_2,unused_8,unused_2,measure
 SG_ signal8485 : 1|1@1+ (1,0) [0|1] ""  ecu_pri1_1,measure
 SG_ signal8496 : 2|1@1+ (1,0) [0|1] ""  ecu_pri1_1,ecu_sec1_2,unused_8,unused_2,unused_6,measure
 SG_ signal8511 : 8|8@1+ (0.75,-48) [-48|141.75] "Celsius"  ecu_pri1_1,ecu_sec1_2,unused_8,unused_2,measure
 SG_ signal8525 : 16|8@1+ (1,-60) [-60|193] "Celsius"  ecu_pri1_1,measure
 SG_ signal8536 : 24|8@1+ (0.75,-48) [-48|141.75] "Celsius"  ecu_pri1_1,ecu_sec1_2,unused_8,unused_2,unused_6,measure
 SG_ signal8551 : 32|8@1+ (0.00781,0) [0|1.98374] ""  ecu_pri1_1,ecu_sec1_2,unused_8,unused_2,measure
 SG_ signal8565 : 40|1@1+ (1,0) [0|1] ""  ecu_pri1_1,measure
 SG_ signal8576 : 41|6@1+ (1,0) [0|63] ""  ecu_pri1_1,measure
 SG_ signal8587 : 48|5@1+ (0.01,0) [0|0.31] "signal8593"  ecu_pri1_1,ecu_sec1_2,unused_8,unused_2,measure

BO_TX_BU_ 131 : ecu_sec1_2,unused_8,unused_2;
BO_TX_BU_ 258 : ecu_sec1_2,unused_8,unused_2;
BO_TX_BU_ 1089 : ecu_sec1_2,unused_8,unused_2;
BO_TX_BU_ 2025 : ecu_sec1_2,unused_8,unused_2;
BO_TX_BU_ 2024 : ecu_sec3_1,unused_1,unused_4;
BO_TX_BU_ 128 : ecu_sec3_1,unused_1,unused_4;
BO_TX_BU_ 129 : ecu_sec3_1,unused_1,unused_4;
BO_TX_BU_ 261 : ecu_sec3_1,unused_1,unused_4;
BO_TX_BU_ 263 : ecu_sec3_1,unused_1,unused_4;
BO_TX_BU_ 782 : ecu_sec3_1,unused_1,unused_4;
BO_TX_BU_ 1088 : ecu_sec3_1,unused_1,unused_4;
BO_TX_BU_ 1600 : ecu_sec3_1,unused_1,unused_4;
BA_DEF_ BO_  "GenMsgAutoGenDsp" ENUM  "No","Yes";
BA_DEF_ BO_  "GenMsgAutoGenSnd" ENUM  "No","Yes";
BA_DEF_ BO_  "GenMsgCycleTime" INT 0 65535;
BA_DEF_ BO_  "GenMsgCycleTimeFast" INT 0 65535;
BA_DEF_ BO_  "GenMsgDelayTime" INT 0 100000;
BA_DEF_ BO_  "GenMsgILSupport" ENUM  "No","Yes";
BA_DEF_ BO_  "GenMsgNrOfRepetition" INT 0 100;
BA_DEF_ BO_  "GenMsgSendType" ENUM  "cyclicX","spontanX","cyclicIfActiveX","spontanWithDelay","cyclicAndSpontanX","cyclicAndSpontanWithDelay","spontanWithRepetition","cyclicIfActiveAndSpontanWD","cyclicIfActiveFast","cyclicWithRepeatOnDemand";
BA_DEF_ BO_  "GenMsgStartDelayTime" INT 0 100000;
BA_DEF_ BO_  "NmMessage" ENUM  "No","Yes";
BA_DEF_ BO_  "NmhMessage" ENUM  "No","Yes";
BA_DEF_ BO_  "NWM-Botschaft" ENUM  "No","Yes";
BA_DEF_ BO_  "signal24915" HEX 0 255;
BA_DEF_ BO_  "signal24909" ENUM  "No","Yes";
BA_DEF_ BO_  "signal24903" ENUM  "No","Yes";
BA_DEF_ BO_  "signal24897" ENUM  "No","Yes";
BA_DEF_ BO_  "Timeoutzeit" INT 0 1000000;
BA_DEF_ BO_  "signal24891" ENUM  "No","Yes";
BA_DEF_ SG_  "GenSigAltSetting" STRING ;
BA_DEF_ SG_  "GenSigAssignSetting" STRING ;
BA_DEF_ SG_  "GenSigAutoGenDsp" ENUM  "No","Yes";
BA_DEF_ SG_  "GenSigAutoGenSnd" ENUM  "No","Yes";
BA_DEF_ SG_  "GenSigConditionalSend" STRING ;
BA_DEF_ SG_  "GenSigEnvVarType" ENUM  "int","float","undef";
BA_DEF_ SG_  "GenSigEVName" STRING ;
BA_DEF_ SG_  "GenSigInactiveValue" INT -2147483648 2147483647;
BA_DEF_ SG_  "GenSigPostIfSetting" STRING ;
BA_DEF_ SG_  "GenSigPostSetting" STRING ;
BA_DEF_ SG_  "GenSigPreIfSetting" STRING ;
BA_DEF_ SG_  "GenSigPreSetting" STRING ;
BA_DEF_ SG_  "GenSigSendType" ENUM  "Cyclic","OnWrite","OnWriteWithRepetition","OnChange","OnChangeWithRepetition","IfActive","IfActiveWithRepetition","NoSigSendType";
BA_DEF_ SG_  "GenSigStartValue" INT -2147483648 2147483647;
BA_DEF_ SG_  "NWM-WakeupAllowed" ENUM  "No","Yes";
BA_DEF_ SG_  "NMH-WakeupAllowed" ENUM  "No","Yes";
BA_DEF_ SG_  "GenSigTimeoutMsg_ecu12594" HEX 0 2047;
BA_DEF_ SG_  "GenSigTimeoutMsg_ecu13120" HEX 0 2047;
BA_DEF_ SG_  "signal133356" HEX 0 2047;
BA_DEF_ SG_  "signal136198" HEX 0 2047;
BA_DEF_ SG_  "signal131977" HEX 0 2047;
BA_DEF_ SG_  "signal131970" HEX 0 2047;
BA_DEF_ SG_  "GenSigTimeoutMsg_ecu11765" HEX 0 2047;
BA_DEF_ SG_  "GenSigTimeoutMsg_ecu13186" HEX 0 2047;
BA_DEF_ SG_  "GenSigTimeoutMsg_ecu12990" HEX 0 2047;
BA_DEF_ SG_  "GenSigTimeoutMsg_ecu8948" HEX 0 2047;
BA_DEF_ SG_  "signal142820" HEX 0 2047;
BA_DEF_ SG_  "signal142834" HEX 0 2047;
BA_DEF_ SG_  "signal142827" HEX 0 2047;
BA_DEF_ SG_  "GenSigTimeoutMsg_ecu5385" HEX 0 2047;
BA_DEF_ SG_  "GenSigTimeoutMsg_ecu9211" HEX 0 2047;
BA_DEF_ SG_  "GenSigTimeoutMsg_ecu11949" HEX 0 2047;
BA_DEF_DEF_  "GenMsgAutoGenDsp" "Yes";
BA_DEF_DEF_  "GenMsgAutoGenSnd" "Yes";
BA_DEF_DEF_  "GenMsgCycleTime" 0;
BA_DEF_DEF_  "GenMsgCycleTimeFast" 0;
BA_DEF_DEF_  "GenMsgDelayTime" 0;
BA_DEF_DEF_  "GenMsgILSupport" "";
BA_DEF_DEF_  "GenMsgNrOfRepetition" 0;
BA_DEF_DEF_  "GenMsgSendType" "cyclicX";
BA_DEF_DEF_  "GenMsgStartDelayTime" 0;
BA_DEF_DEF_  "NmMessage" "No";
BA_DEF_DEF_  "NmhMessage" "No";
BA_DEF_DEF_  "NWM-Botschaft" "No";
BA_DEF_DEF_  "signal24915" 0;
BA_DEF_DEF_  "signal24909" "No";
BA_DEF_DEF_  "signal24903" "No";
BA_DEF_DEF_  "signal24897" "No";
BA_DEF_DEF_  "Timeoutzeit" 0;
BA_DEF_DEF_  "signal24891" "";
BA_DEF_DEF_  "GenSigAltSetting" "";
BA_DEF_DEF_  "GenSigAssignSetting" "";
BA_DEF_DEF_  "GenSigAutoGenDsp" "";
BA_DEF_DEF_  "GenSigAutoGenSnd" "";
BA_DEF_DEF_  "GenSigConditionalSend" "";
BA_DEF_DEF_  "GenSigEnvVarType" "undef";
BA_DEF_DEF_  "GenSigEVName" "";
BA_DEF_DEF_  "GenSigInactiveValue" 0;
BA_DEF_DEF_  "GenSigPostIfSetting" "";
BA_DEF_DEF_  "GenSigPostSetting" "";
BA_DEF_DEF_  "GenSigPreIfSetting" "";
BA_DEF_DEF_  "GenSigPreSetting" "";
BA_DEF_DEF_  "GenSigSendType" "Cyclic";
BA_DEF_DEF_  "GenSigStartValue" 0;
BA_DEF_DEF_  "NWM-WakeupAllowed" "";
BA_DEF_DEF_  "NMH-WakeupAllowed" "";
BA_DEF_DEF_  "GenSigTimeoutMsg_ecu12594" 0;
BA_DEF_DEF_  "GenSigTimeoutMsg_ecu13120" 0;
BA_DEF_DEF_  "signal133356" 0;
BA_DEF_DEF_  "signal136198" 0;
BA_DEF_DEF_  "signal131977" 0;
BA_DEF_DEF_  "signal131970" 0;
BA_DEF_DEF_  "GenSigTimeoutMsg_ecu11765" 0;
BA_DEF_DEF_  "GenSigTimeoutMsg_ecu13186" 0;
BA_DEF_DEF_  "GenSigTimeoutMsg_ecu12990" 0;
BA_DEF_DEF_  "GenSigTimeoutMsg_ecu8948" 0;
BA_DEF_DEF_  "signal142820" 0;
BA_DEF_DEF_  "signal142834" 0;
BA_DEF_DEF_  "signal142827" 0;
BA_DEF_DEF_  "GenSigTimeoutMsg_ecu5385" 0;
BA_DEF_DEF_  "GenSigTimeoutMsg_ecu9211" 0;
BA_DEF_DEF_  "GenSigTimeoutMsg_ecu11949" 0;
BA_ "signal24891" BO_ 131 1;
BA_ "GenMsgILSupport" BO_ 131 1;
BA_ "GenMsgCycleTime" BO_ 131 10;
BA_ "signal24891" BO_ 258 1;
BA_ "GenMsgILSupport" BO_ 258 1;
BA_ "GenMsgCycleTime" BO_ 258 20;
BA_ "signal24891" BO_ 1089 1;
BA_ "GenMsgILSupport" BO_ 1089 1;
BA_ "GenMsgCycleTime" BO_ 1089 100;
BA_ "signal24891" BO_ 1813 1;
BA_ "GenMsgSendType" BO_ 1813 1;
BA_ "GenMsgILSupport" BO_ 1813 0;
BA_ "GenMsgAutoGenSnd" BO_ 1813 0;
BA_ "GenMsgAutoGenDsp" BO_ 1813 0;
BA_ "signal24891" BO_ 1792 1;
BA_ "GenMsgSendType" BO_ 1792 1;
BA_ "GenMsgILSupport" BO_ 1792 0;
BA_ "GenMsgAutoGenSnd" BO_ 1792 0;
BA_ "GenMsgAutoGenDsp" BO_ 1792 0;
BA_ "signal24891" BO_ 2015 1;
BA_ "GenMsgSendType" BO_ 2015 1;
BA_ "GenMsgILSupport" BO_ 2015 0;
BA_ "GenMsgAutoGenSnd" BO_ 2015 0;
BA_ "GenMsgAutoGenDsp" BO_ 2015 0;
BA_ "signal24891" BO_ 2017 1;
BA_ "GenMsgSendType" BO_ 2017 1;
BA_ "GenMsgILSupport" BO_ 2017 0;
BA_ "GenMsgAutoGenSnd" BO_ 2017 0;
BA_ "GenMsgAutoGenDsp" BO_ 2017 0;
BA_ "signal24891" BO_ 2025 1;
BA_ "GenMsgSendType" BO_ 2025 1;
BA_ "GenMsgILSupport" BO_ 2025 0;
BA_ "GenMsgAutoGenSnd" BO_ 2025 0;
BA_ "GenMsgAutoGenDsp" BO_ 2025 0;
BA_ "signal24891" BO_ 2016 1;
BA_ "GenMsgSendType" BO_ 2016 1;
BA_ "GenMsgILSupport" BO_ 2016 0;
BA_ "GenMsgAutoGenSnd" BO_ 2016 0;
BA_ "GenMsgAutoGenDsp" BO_ 2016 0;
BA_ "signal24891" BO_ 2024 1;
BA_ "GenMsgSendType" BO_ 2024 1;
BA_ "GenMsgILSupport" BO_ 2024 0;
BA_ "GenMsgAutoGenSnd" BO_ 2024 0;
BA_ "GenMsgAutoGenDsp" BO_ 2024 0;
BA_ "signal24891" BO_ 2018 1;
BA_ "GenMsgSendType" BO_ 2018 1;
BA_ "GenMsgILSupport" BO_ 2018 0;
BA_ "GenMsgAutoGenSnd" BO_ 2018 0;
BA_ "GenMsgAutoGenDsp" BO_ 2018 0;
BA_ "signal24891" BO_ 2026 1;
BA_ "GenMsgSendType" BO_ 2026 1;
BA_ "GenMsgILSupport" BO_ 2026 0;
BA_ "GenMsgAutoGenSnd" BO_ 2026 0;
BA_ "GenMsgAutoGenDsp" BO_ 2026 0;
BA_ "signal24891" BO_ 2019 1;
BA_ "GenMsgSendType" BO_ 2019 1;
BA_ "GenMsgILSupport" BO_ 2019 0;
BA_ "GenMsgAutoGenSnd" BO_ 2019 0;
BA_ "GenMsgAutoGenDsp" BO_ 2019 0;
BA_ "signal24891" BO_ 2027 1;
BA_ "GenMsgSendType" BO_ 2027 1;
BA_ "GenMsgILSupport" BO_ 2027 0;
BA_ "GenMsgAutoGenSnd" BO_ 2027 0;
BA_ "GenMsgAutoGenDsp" BO_ 2027 0;
BA_ "signal24891" BO_ 1875 1;
BA_ "GenMsgSendType" BO_ 1875 1;
BA_ "GenMsgILSupport" BO_ 1875 0;
BA_ "GenMsgAutoGenSnd" BO_ 1875 0;
BA_ "GenMsgAutoGenDsp" BO_ 1875 0;
BA_ "signal24891" BO_ 1981 1;
BA_ "GenMsgSendType" BO_ 1981 1;
BA_ "GenMsgILSupport" BO_ 1981 0;
BA_ "GenMsgAutoGenSnd" BO_ 1981 0;
BA_ "GenMsgAutoGenDsp" BO_ 1981 0;
BA_ "signal24891" BO_ 1424 1;
BA_ "GenMsgSendType" BO_ 1424 5;
BA_ "GenMsgILSupport" BO_ 1424 1;
BA_ "GenMsgDelayTime" BO_ 1424 50;
BA_ "GenMsgCycleTime" BO_ 1424 200;
BA_ "signal24891" BO_ 960 1;
BA_ "GenMsgSendType" BO_ 960 5;
BA_ "GenMsgILSupport" BO_ 960 1;
BA_ "GenMsgDelayTime" BO_ 960 10;
BA_ "GenMsgCycleTime" BO_ 960 100;
BA_ "signal24891" BO_ 959 1;
BA_ "GenMsgILSupport" BO_ 959 1;
BA_ "GenMsgCycleTime" BO_ 959 100;
BA_ "signal24891" BO_ 1646 1;
BA_ "GenMsgSendType" BO_ 1646 5;
BA_ "GenMsgILSupport" BO_ 1646 1;
BA_ "GenMsgDelayTime" BO_ 1646 200;
BA_ "GenMsgCycleTime" BO_ 1646 2000;
BA_ "signal24891" BO_ 1649 1;
BA_ "GenMsgILSupport" BO_ 1649 1;
BA_ "GenMsgCycleTime" BO_ 1649 500;
BA_ "signal24891" BO_ 779 1;
BA_ "GenMsgILSupport" BO_ 779 1;
BA_ "GenMsgCycleTime" BO_ 779 50;
BA_ "signal24891" BO_ 1719 1;
BA_ "GenMsgILSupport" BO_ 1719 1;
BA_ "GenMsgCycleTime" BO_ 1719 1000;
BA_ "signal24891" BO_ 1720 1;
BA_ "GenMsgILSupport" BO_ 1720 1;
BA_ "GenMsgCycleTime" BO_ 1720 1000;
BA_ "signal24891" BO_ 517 1;
BA_ "GenMsgSendType" BO_ 517 1;
BA_ "GenMsgILSupport" BO_ 517 0;
BA_ "GenMsgAutoGenSnd" BO_ 517 0;
BA_ "GenMsgAutoGenDsp" BO_ 517 0;
BA_ "signal24891" BO_ 640 1;
BA_ "GenMsgSendType" BO_ 640 1;
BA_ "GenMsgILSupport" BO_ 640 0;
BA_ "GenMsgAutoGenSnd" BO_ 640 0;
BA_ "GenMsgAutoGenDsp" BO_ 640 0;
BA_ "signal24891" BO_ 1137 1;
BA_ "GenMsgILSupport" BO_ 1137 1;
BA_ "GenMsgCycleTime" BO_ 1137 100;
BA_ "signal24891" BO_ 267 0;
BA_ "GenMsgSendType" BO_ 267 5;
BA_ "GenMsgILSupport" BO_ 267 1;
BA_ "GenMsgDelayTime" BO_ 267 20;
BA_ "GenMsgCycleTimeFast" BO_ 267 20;
BA_ "GenMsgCycleTime" BO_ 267 100;
BA_ "signal24891" BO_ 134 0;
BA_ "GenMsgILSupport" BO_ 134 1;
BA_ "GenMsgCycleTime" BO_ 134 10;
BA_ "signal24891" BO_ 128 1;
BA_ "GenMsgILSupport" BO_ 128 1;
BA_ "GenMsgCycleTime" BO_ 128 10;
BA_ "signal24891" BO_ 129 1;
BA_ "GenMsgILSupport" BO_ 129 1;
BA_ "GenMsgCycleTime" BO_ 129 10;
BA_ "signal24891" BO_ 261 1;
BA_ "GenMsgILSupport" BO_ 261 1;
BA_ "GenMsgCycleTime" BO_ 261 20;
BA_ "signal24891" BO_ 263 1;
BA_ "GenMsgILSupport" BO_ 263 1;
BA_ "GenMsgCycleTime" BO_ 263 20;
BA_ "signal24891" BO_ 782 1;
BA_ "GenMsgILSupport" BO_ 782 1;
BA_ "GenMsgCycleTime" BO_ 782 50;
BA_ "signal24891" BO_ 1088 1;
BA_ "GenMsgILSupport" BO_ 1088 1;
BA_ "GenMsgCycleTime" BO_ 1088 100;
BA_ "signal24891" BO_ 1600 1;
BA_ "GenMsgILSupport" BO_ 1600 1;
BA_ "GenMsgCycleTime" BO_ 1600 500;
BA_ "signal136198" SG_ 131 signal4702_CHK 131;
BA_ "signal133356" SG_ 131 signal4702_CHK 131;
BA_ "GenSigTimeoutMsg_ecu13120" SG_ 131 signal4702_CHK 131;
BA_ "NMH-WakeupAllowed" SG_ 131 signal4702_CHK 0;
BA_ "NWM-WakeupAllowed" SG_ 131 signal4702_CHK 0;
BA_ "GenSigSendType" SG_ 131 signal4702_CHK 7;
BA_ "GenSigEnvVarType" SG_ 131 signal4702_CHK 0;
BA_ "GenSigAutoGenSnd" SG_ 131 signal4702_CHK 1;
BA_ "GenSigAutoGenDsp" SG_ 131 signal4702_CHK 1;
BA_ "signal136198" SG_ 131 signal4720 131;
BA_ "signal133356" SG_ 131 signal4720 131;
BA_ "GenSigTimeoutMsg_ecu13120" SG_ 131 signal4720 131;
BA_ "NMH-WakeupAllowed" SG_ 131 signal4720 0;
BA_ "NWM-WakeupAllowed" SG_ 131 signal4720 0;
BA_ "GenSigSendType" SG_ 131 signal4720 7;
BA_ "GenSigEnvVarType" SG_ 131 signal4720 0;
BA_ "GenSigAutoGenSnd" SG_ 131 signal4720 1;
BA_ "GenSigAutoGenDsp" SG_ 131 signal4720 1;
BA_ "signal136198" SG_ 131 signal4733 131;
BA_ "signal133356" SG_ 131 signal4733 131;
BA_ "GenSigTimeoutMsg_ecu13120" SG_ 131 signal4733 131;
BA_ "NMH-WakeupAllowed" SG_ 131 signal4733 0;
BA_ "NWM-WakeupAllowed" SG_ 131 signal4733 0;
BA_ "GenSigSendType" SG_ 131 signal4733 7;
BA_ "GenSigEnvVarType" SG_ 131 signal4733 0;
BA_ "GenSigAutoGenSnd" SG_ 131 signal4733 1;
BA_ "GenSigAutoGenDsp" SG_ 131 signal4733 1;
BA_ "signal136198" SG_ 131 signal4746 131;
BA_ "signal133356" SG_ 131 signal4746 131;
BA_ "GenSigTimeoutMsg_ecu13120" SG_ 131 signal4746 131;
BA_ "NMH-WakeupAllowed" SG_ 131 signal4746 0;
BA_ "NWM-WakeupAllowed" SG_ 131 signal4746 0;
BA_ "GenSigSendType" SG_ 131 signal4746 7;
BA_ "GenSigEnvVarType" SG_ 131 signal4746 0;
BA_ "GenSigAutoGenSnd" SG_ 131 signal4746 1;
BA_ "GenSigAutoGenDsp" SG_ 131 signal4746 1;
BA_ "signal136198" SG_ 131 signal4759 131;
BA_ "signal133356" SG_ 131 signal4759 131;
BA_ "GenSigTimeoutMsg_ecu13120" SG_ 131 signal4759 131;
BA_ "NMH-WakeupAllowed" SG_ 131 signal4759 0;
BA_ "NWM-WakeupAllowed" SG_ 131 signal4759 0;
BA_ "GenSigStartValue" SG_ 131 signal4759 255;
BA_ "GenSigSendType" SG_ 131 signal4759 7;
BA_ "GenSigEnvVarType" SG_ 131 signal4759 0;
BA_ "GenSigAutoGenSnd" SG_ 131 signal4759 1;
BA_ "GenSigAutoGenDsp" SG_ 131 signal4759 1;
BA_ "signal136198" SG_ 131 signal4772 131;
BA_ "signal133356" SG_ 131 signal4772 131;
BA_ "GenSigTimeoutMsg_ecu13120" SG_ 131 signal4772 131;
BA_ "NMH-WakeupAllowed" SG_ 131 signal4772 0;
BA_ "NWM-WakeupAllowed" SG_ 131 signal4772 0;
BA_ "GenSigSendType" SG_ 131 signal4772 7;
BA_ "GenSigEnvVarType" SG_ 131 signal4772 0;
BA_ "GenSigAutoGenSnd" SG_ 131 signal4772 1;
BA_ "GenSigAutoGenDsp" SG_ 131 signal4772 1;
BA_ "signal136198" SG_ 131 signal4785 131;
BA_ "signal133356" SG_ 131 signal4785 131;
BA_ "GenSigTimeoutMsg_ecu13120" SG_ 131 signal4785 131;
BA_ "NMH-WakeupAllowed" SG_ 131 signal4785 0;
BA_ "NWM-WakeupAllowed" SG_ 131 signal4785 0;
BA_ "GenSigStartValue" SG_ 131 signal4785 510;
BA_ "GenSigSendType" SG_ 131 signal4785 7;
BA_ "GenSigEnvVarType" SG_ 131 signal4785 0;
BA_ "GenSigAutoGenSnd" SG_ 131 signal4785 1;
BA_ "GenSigAutoGenDsp" SG_ 131 signal4785 1;
BA_ "signal136198" SG_ 131 signal4798 131;
BA_ "signal133356" SG_ 131 signal4798 131;
BA_ "GenSigTimeoutMsg_ecu13120" SG_ 131 signal4798 131;
BA_ "NMH-WakeupAllowed" SG_ 131 signal4798 0;
BA_ "NWM-WakeupAllowed" SG_ 131 signal4798 0;
BA_ "GenSigSendType" SG_ 131 signal4798 7;
BA_ "GenSigEnvVarType" SG_ 131 signal4798 0;
BA_ "GenSigAutoGenSnd" SG_ 131 signal4798 1;
BA_ "GenSigAutoGenDsp" SG_ 131 signal4798 1;
BA_ "signal136198" SG_ 131 signal4811 131;
BA_ "signal133356" SG_ 131 signal4811 131;
BA_ "GenSigTimeoutMsg_ecu13120" SG_ 131 signal4811 131;
BA_ "NMH-WakeupAllowed" SG_ 131 signal4811 0;
BA_ "NWM-WakeupAllowed" SG_ 131 signal4811 0;
BA_ "GenSigSendType" SG_ 131 signal4811 7;
BA_ "GenSigEnvVarType" SG_ 131 signal4811 0;
BA_ "GenSigAutoGenSnd" SG_ 131 signal4811 1;
BA_ "GenSigAutoGenDsp" SG_ 131 signal4811 1;
BA_ "signal136198" SG_ 131 signal4824 131;
BA_ "signal133356" SG_ 131 signal4824 131;
BA_ "GenSigTimeoutMsg_ecu13120" SG_ 131 signal4824 131;
BA_ "NMH-WakeupAllowed" SG_ 131 signal4824 0;
BA_ "NWM-WakeupAllowed" SG_ 131 signal4824 0;
BA_ "GenSigSendType" SG_ 131 signal4824 7;
BA_ "GenSigEnvVarType" SG_ 131 signal4824 0;
BA_ "GenSigAutoGenSnd" SG_ 131 signal4824 1;
BA_ "GenSigAutoGenDsp" SG_ 131 signal4824 1;
BA_ "signal136198" SG_ 258 signal4843 258;
BA_ "signal133356" SG_ 258 signal4843 258;
BA_ "GenSigTimeoutMsg_ecu13120" SG_ 258 signal4843 258;
BA_ "GenSigTimeoutMsg_ecu13186" SG_ 258 signal4843 258;
BA_ "GenSigTimeoutMsg_ecu12594" SG_ 258 signal4843 258;
BA_ "NMH-WakeupAllowed" SG_ 258 signal4843 0;
BA_ "NWM-WakeupAllowed" SG_ 258 signal4843 0;
BA_ "GenSigSendType" SG_ 258 signal4843 7;
BA_ "GenSigEnvVarType" SG_ 258 signal4843 0;
BA_ "GenSigAutoGenSnd" SG_ 258 signal4843 1;
BA_ "GenSigAutoGenDsp" SG_ 258 signal4843 1;
BA_ "signal136198" SG_ 258 signal4858 258;
BA_ "signal133356" SG_ 258 signal4858 258;
BA_ "GenSigTimeoutMsg_ecu13120" SG_ 258 signal4858 258;
BA_ "GenSigTimeoutMsg_ecu13186" SG_ 258 signal4858 258;
BA_ "GenSigTimeoutMsg_ecu12594" SG_ 258 signal4858 258;
BA_ "NMH-WakeupAllowed" SG_ 258 signal4858 0;
BA_ "NWM-WakeupAllowed" SG_ 258 signal4858 0;
BA_ "GenSigSendType" SG_ 258 signal4858 7;
BA_ "GenSigEnvVarType" SG_ 258 signal4858 0;
BA_ "GenSigAutoGenSnd" SG_ 258 signal4858 1;
BA_ "GenSigAutoGenDsp" SG_ 258 signal4858 1;
BA_ "signal136198" SG_ 258 signal4873 258;
BA_ "signal133356" SG_ 258 signal4873 258;
BA_ "GenSigTimeoutMsg_ecu13120" SG_ 258 signal4873 258;
BA_ "GenSigTimeoutMsg_ecu13186" SG_ 258 signal4873 258;
BA_ "NMH-WakeupAllowed" SG_ 258 signal4873 0;
BA_ "NWM-WakeupAllowed" SG_ 258 signal4873 0;
BA_ "GenSigSendType" SG_ 258 signal4873 7;
BA_ "GenSigEnvVarType" SG_ 258 signal4873 0;
BA_ "GenSigAutoGenSnd" SG_ 258 signal4873 1;
BA_ "GenSigAutoGenDsp" SG_ 258 signal4873 1;
BA_ "signal136198" SG_ 258 signal4887 258;
BA_ "signal133356" SG_ 258 signal4887 258;
BA_ "GenSigTimeoutMsg_ecu13120" SG_ 258 signal4887 258;
BA_ "GenSigTimeoutMsg_ecu13186" SG_ 258 signal4887 258;
BA_ "GenSigTimeoutMsg_ecu12594" SG_ 258 signal4887 258;
BA_ "NMH-WakeupAllowed" SG_ 258 signal4887 0;
BA_ "NWM-WakeupAllowed" SG_ 258 signal4887 0;
BA_ "GenSigSendType" SG_ 258 signal4887 7;
BA_ "GenSigEnvVarType" SG_ 258 signal4887 1;
BA_ "GenSigAutoGenSnd" SG_ 258 signal4887 1;
BA_ "GenSigAutoGenDsp" SG_ 258 signal4887 1;
BA_ "signal136198" SG_ 258 signal4902 258;
BA_ "signal133356" SG_ 258 signal4902 258;
BA_ "GenSigTimeoutMsg_ecu13120" SG_ 258 signal4902 258;
BA_ "GenSigTimeoutMsg_ecu13186" SG_ 258 signal4902 258;
BA_ "NMH-WakeupAllowed" SG_ 258 signal4902 0;
BA_ "NWM-WakeupAllowed" SG_ 258 signal4902 0;
BA_ "GenSigSendType" SG_ 258 signal4902 7;
BA_ "GenSigEnvVarType" SG_ 258 signal4902 0;
BA_ "GenSigAutoGenSnd" SG_ 258 signal4902 1;
BA_ "GenSigAutoGenDsp" SG_ 258 signal4902 1;
BA_ "signal136198" SG_ 258 signal4916 258;
BA_ "signal133356" SG_ 258 signal4916 258;
BA_ "GenSigTimeoutMsg_ecu13120" SG_ 258 signal4916 258;
BA_ "GenSigTimeoutMsg_ecu13186" SG_ 258 signal4916 258;
BA_ "NMH-WakeupAllowed" SG_ 258 signal4916 0;
BA_ "NWM-WakeupAllowed" SG_ 258 signal4916 0;
BA_ "GenSigStartValue" SG_ 258 signal4916 1022;
BA_ "GenSigSendType" SG_ 258 signal4916 7;
BA_ "GenSigEnvVarType" SG_ 258 signal4916 0;
BA_ "GenSigAutoGenSnd" SG_ 258 signal4916 1;
BA_ "GenSigAutoGenDsp" SG_ 258 signal4916 1;
BA_ "GenSigTimeoutMsg_ecu13186" SG_ 258 signal4930 258;
BA_ "NMH-WakeupAllowed" SG_ 258 signal4930 0;
BA_ "NWM-WakeupAllowed" SG_ 258 signal4930 0;
BA_ "GenSigSendType" SG_ 258 signal4930 7;
BA_ "GenSigEnvVarType" SG_ 258 signal4930 0;
BA_ "GenSigAutoGenSnd" SG_ 258 signal4930 1;
BA_ "GenSigAutoGenDsp" SG_ 258 signal4930 1;
BA_ "signal136198" SG_ 258 signal4941 258;
BA_ "signal133356" SG_ 258 signal4941 258;
BA_ "GenSigTimeoutMsg_ecu13120" SG_ 258 signal4941 258;
BA_ "GenSigTimeoutMsg_ecu13186" SG_ 258 signal4941 258;
BA_ "GenSigTimeoutMsg_ecu12594" SG_ 258 signal4941 258;
BA_ "NMH-WakeupAllowed" SG_ 258 signal4941 0;
BA_ "NWM-WakeupAllowed" SG_ 258 signal4941 0;
BA_ "GenSigStartValue" SG_ 258 signal4941 1;
BA_ "GenSigSendType" SG_ 258 signal4941 7;
BA_ "GenSigEnvVarType" SG_ 258 signal4941 0;
BA_ "GenSigAutoGenSnd" SG_ 258 signal4941 1;
BA_ "GenSigAutoGenDsp" SG_ 258 signal4941 1;
BA_ "signal136198" SG_ 258 signal4956 258;
BA_ "signal133356" SG_ 258 signal4956 258;
BA_ "GenSigTimeoutMsg_ecu13120" SG_ 258 signal4956 258;
BA_ "GenSigTimeoutMsg_ecu13186" SG_ 258 signal4956 258;
BA_ "NMH-WakeupAllowed" SG_ 258 signal4956 0;
BA_ "NWM-WakeupAllowed" SG_ 258 signal4956 0;
BA_ "GenSigStartValue" SG_ 258 signal4956 16382;
BA_ "GenSigSendType" SG_ 258 signal4956 7;
BA_ "GenSigEnvVarType" SG_ 258 signal4956 1;
BA_ "GenSigAutoGenSnd" SG_ 258 signal4956 1;
BA_ "GenSigAutoGenDsp" SG_ 258 signal4956 1;
BA_ "signal136198" SG_ 258 signal4970 258;
BA_ "signal133356" SG_ 258 signal4970 258;
BA_ "GenSigTimeoutMsg_ecu13120" SG_ 258 signal4970 258;
BA_ "GenSigTimeoutMsg_ecu13186" SG_ 258 signal4970 258;
BA_ "NMH-WakeupAllowed" SG_ 258 signal4970 0;
BA_ "NWM-WakeupAllowed" SG_ 258 signal4970 0;
BA_ "GenSigSendType" SG_ 258 signal4970 7;
BA_ "GenSigEnvVarType" SG_ 258 signal4970 0;
BA_ "GenSigAutoGenSnd" SG_ 258 signal4970 1;
BA_ "GenSigAutoGenDsp" SG_ 258 signal4970 1;
BA_ "GenSigTimeoutMsg_ecu13186" SG_ 258 signal4984 258;
BA_ "GenSigTimeoutMsg_ecu12594" SG_ 258 signal4984 258;
BA_ "NMH-WakeupAllowed" SG_ 258 signal4984 0;
BA_ "NWM-WakeupAllowed" SG_ 258 signal4984 0;
BA_ "GenSigSendType" SG_ 258 signal4984 7;
BA_ "GenSigEnvVarType" SG_ 258 signal4984 0;
BA_ "GenSigAutoGenSnd" SG_ 258 signal4984 1;
BA_ "GenSigAutoGenDsp" SG_ 258 signal4984 1;
BA_ "signal136198" SG_ 1089 signal5002 1089;
BA_ "signal133356" SG_ 1089 signal5002 1089;
BA_ "GenSigTimeoutMsg_ecu13120" SG_ 1089 signal5002 1089;
BA_ "GenSigTimeoutMsg_ecu13186" SG_ 1089 signal5002 1089;
BA_ "NMH-WakeupAllowed" SG_ 1089 signal5002 0;
BA_ "NWM-WakeupAllowed" SG_ 1089 signal5002 0;
BA_ "GenSigStartValue" SG_ 1089 signal5002 127;
BA_ "GenSigSendType" SG_ 1089 signal5002 7;
BA_ "GenSigEnvVarType" SG_ 1089 signal5002 1;
BA_ "GenSigAutoGenSnd" SG_ 1089 signal5002 1;
BA_ "GenSigAutoGenDsp" SG_ 1089 signal5002 1;
BA_ "signal136198" SG_ 1089 signal5016 1089;
BA_ "signal133356" SG_ 1089 signal5016 1089;
BA_ "GenSigTimeoutMsg_ecu13120" SG_ 1089 signal5016 1089;
BA_ "GenSigTimeoutMsg_ecu13186" SG_ 1089 signal5016 1089;
BA_ "NMH-WakeupAllowed" SG_ 1089 signal5016 0;
BA_ "NWM-WakeupAllowed" SG_ 1089 signal5016 0;
BA_ "GenSigSendType" SG_ 1089 signal5016 7;
BA_ "GenSigEnvVarType" SG_ 1089 signal5016 0;
BA_ "GenSigAutoGenSnd" SG_ 1089 signal5016 1;
BA_ "GenSigAutoGenDsp" SG_ 1089 signal5016 1;
BA_ "signal136198" SG_ 1089 signal5030 1089;
BA_ "signal133356" SG_ 1089 signal5030 1089;
BA_ "GenSigTimeoutMsg_ecu13120" SG_ 1089 signal5030 1089;
BA_ "GenSigTimeoutMsg_ecu13186" SG_ 1089 signal5030 1089;
BA_ "NMH-WakeupAllowed" SG_ 1089 signal5030 0;
BA_ "NWM-WakeupAllowed" SG_ 1089 signal5030 0;
BA_ "GenSigSendType" SG_ 1089 signal5030 7;
BA_ "GenSigEnvVarType" SG_ 1089 signal5030 0;
BA_ "GenSigAutoGenSnd" SG_ 1089 signal5030 1;
BA_ "GenSigAutoGenDsp" SG_ 1089 signal5030 1;
BA_ "GenSigTimeoutMsg_ecu13186" SG_ 1089 signal5044 1089;
BA_ "NMH-WakeupAllowed" SG_ 1089 signal5044 0;
BA_ "NWM-WakeupAllowed" SG_ 1089 signal5044 0;
BA_ "GenSigSendType" SG_ 1089 signal5044 7;
BA_ "GenSigEnvVarType" SG_ 1089 signal5044 0;
BA_ "GenSigAutoGenSnd" SG_ 1089 signal5044 1;
BA_ "GenSigAutoGenDsp" SG_ 1089 signal5044 1;
BA_ "GenSigTimeoutMsg_ecu13186" SG_ 1089 signal5055 1089;
BA_ "GenSigTimeoutMsg_ecu12594" SG_ 1089 signal5055 1089;
BA_ "NMH-WakeupAllowed" SG_ 1089 signal5055 0;
BA_ "NWM-WakeupAllowed" SG_ 1089 signal5055 0;
BA_ "GenSigStartValue" SG_ 1089 signal5055 62;
BA_ "GenSigSendType" SG_ 1089 signal5055 7;
BA_ "GenSigEnvVarType" SG_ 1089 signal5055 0;
BA_ "GenSigAutoGenSnd" SG_ 1089 signal5055 1;
BA_ "GenSigAutoGenDsp" SG_ 1089 signal5055 1;
BA_ "GenSigTimeoutMsg_ecu13186" SG_ 1089 signal5067 1089;
BA_ "NMH-WakeupAllowed" SG_ 1089 signal5067 0;
BA_ "NWM-WakeupAllowed" SG_ 1089 signal5067 0;
BA_ "GenSigSendType" SG_ 1089 signal5067 7;
BA_ "GenSigEnvVarType" SG_ 1089 signal5067 0;
BA_ "GenSigAutoGenSnd" SG_ 1089 signal5067 1;
BA_ "GenSigAutoGenDsp" SG_ 1089 signal5067 1;
BA_ "GenSigTimeoutMsg_ecu13186" SG_ 1089 signal5078 1089;
BA_ "NMH-WakeupAllowed" SG_ 1089 signal5078 0;
BA_ "NWM-WakeupAllowed" SG_ 1089 signal5078 0;
BA_ "GenSigSendType" SG_ 1089 signal5078 7;
BA_ "GenSigEnvVarType" SG_ 1089 signal5078 0;
BA_ "GenSigAutoGenSnd" SG_ 1089 signal5078 1;
BA_ "GenSigAutoGenDsp" SG_ 1089 signal5078 1;
BA_ "GenSigTimeoutMsg_ecu13186" SG_ 1089 signal5089 1089;
BA_ "NMH-WakeupAllowed" SG_ 1089 signal5089 0;
BA_ "NWM-WakeupAllowed" SG_ 1089 signal5089 0;
BA_ "GenSigSendType" SG_ 1089 signal5089 7;
BA_ "GenSigEnvVarType" SG_ 1089 signal5089 0;
BA_ "GenSigAutoGenSnd" SG_ 1089 signal5089 1;
BA_ "GenSigAutoGenDsp" SG_ 1089 signal5089 1;
BA_ "signal136198" SG_ 1089 signal5100 1089;
BA_ "signal133356" SG_ 1089 signal5100 1089;
BA_ "GenSigTimeoutMsg_ecu13120" SG_ 1089 signal5100 1089;
BA_ "GenSigTimeoutMsg_ecu13186" SG_ 1089 signal5100 1089;
BA_ "GenSigTimeoutMsg_ecu12594" SG_ 1089 signal5100 1089;
BA_ "NMH-WakeupAllowed" SG_ 1089 signal5100 0;
BA_ "NWM-WakeupAllowed" SG_ 1089 signal5100 0;
BA_ "GenSigSendType" SG_ 1089 signal5100 7;
BA_ "GenSigEnvVarType" SG_ 1089 signal5100 0;
BA_ "GenSigAutoGenSnd" SG_ 1089 signal5100 1;
BA_ "GenSigAutoGenDsp" SG_ 1089 signal5100 1;
BA_ "signal136198" SG_ 1089 signal5115 1089;
BA_ "signal133356" SG_ 1089 signal5115 1089;
BA_ "GenSigTimeoutMsg_ecu13120" SG_ 1089 signal5115 1089;
BA_ "GenSigTimeoutMsg_ecu13186" SG_ 1089 signal5115 1089;
BA_ "NMH-WakeupAllowed" SG_ 1089 signal5115 0;
BA_ "NWM-WakeupAllowed" SG_ 1089 signal5115 0;
BA_ "GenSigStartValue" SG_ 1089 signal5115 84;
BA_ "GenSigSendType" SG_ 1089 signal5115 7;
BA_ "GenSigEnvVarType" SG_ 1089 signal5115 1;
BA_ "GenSigAutoGenSnd" SG_ 1089 signal5115 1;
BA_ "GenSigAutoGenDsp" SG_ 1089 signal5115 1;
BA_ "signal136198" SG_ 1089 signal5129 1089;
BA_ "signal133356" SG_ 1089 signal5129 1089;
BA_ "GenSigTimeoutMsg_ecu13120" SG_ 1089 signal5129 1089;
BA_ "GenSigTimeoutMsg_ecu13186" SG_ 1089 signal5129 1089;
BA_ "NMH-WakeupAllowed" SG_ 1089 signal5129 0;
BA_ "NWM-WakeupAllowed" SG_ 1089 signal5129 0;
BA_ "GenSigSendType" SG_ 1089 signal5129 7;
BA_ "GenSigEnvVarType" SG_ 1089 signal5129 0;
BA_ "GenSigAutoGenSnd" SG_ 1089 signal5129 1;
BA_ "GenSigAutoGenDsp" SG_ 1089 signal5129 1;
BA_ "signal142834" SG_ 1813 signal5144_Data 1813;
BA_ "NMH-WakeupAllowed" SG_ 1813 signal5144_Data 0;
BA_ "NWM-WakeupAllowed" SG_ 1813 signal5144_Data 0;
BA_ "GenSigSendType" SG_ 1813 signal5144_Data 7;
BA_ "GenSigEnvVarType" SG_ 1813 signal5144_Data 0;
BA_ "GenSigAutoGenSnd" SG_ 1813 signal5144_Data 0;
BA_ "GenSigAutoGenDsp" SG_ 1813 signal5144_Data 0;
BA_ "GenSigTimeoutMsg_ecu5385" SG_ 1792 signal5183 1792;
BA_ "GenSigTimeoutMsg_ecu8948" SG_ 1792 signal5183 1792;
BA_ "signal136198" SG_ 1792 signal5183 1792;
BA_ "signal133356" SG_ 1792 signal5183 1792;
BA_ "GenSigTimeoutMsg_ecu13120" SG_ 1792 signal5183 1792;
BA_ "GenSigTimeoutMsg_ecu11765" SG_ 1792 signal5183 1792;
BA_ "signal131970" SG_ 1792 signal5183 1792;
BA_ "signal131977" SG_ 1792 signal5183 1792;
BA_ "signal142834" SG_ 1792 signal5183 1792;
BA_ "NMH-WakeupAllowed" SG_ 1792 signal5183 0;
BA_ "NWM-WakeupAllowed" SG_ 1792 signal5183 0;
BA_ "GenSigSendType" SG_ 1792 signal5183 7;
BA_ "GenSigEnvVarType" SG_ 1792 signal5183 0;
BA_ "GenSigAutoGenSnd" SG_ 1792 signal5183 0;
BA_ "GenSigAutoGenDsp" SG_ 1792 signal5183 0;
BA_ "GenSigTimeoutMsg_ecu8948" SG_ 2015 signal5208 2015;
BA_ "signal136198" SG_ 2015 signal5208 2015;
BA_ "signal133356" SG_ 2015 signal5208 2015;
BA_ "GenSigTimeoutMsg_ecu13120" SG_ 2015 signal5208 2015;
BA_ "GenSigTimeoutMsg_ecu11765" SG_ 2015 signal5208 2015;
BA_ "signal131970" SG_ 2015 signal5208 2015;
BA_ "signal131977" SG_ 2015 signal5208 2015;
BA_ "signal142834" SG_ 2015 signal5208 2015;
BA_ "NMH-WakeupAllowed" SG_ 2015 signal5208 0;
BA_ "NWM-WakeupAllowed" SG_ 2015 signal5208 0;
BA_ "GenSigSendType" SG_ 2015 signal5208 7;
BA_ "GenSigEnvVarType" SG_ 2015 signal5208 0;
BA_ "GenSigAutoGenSnd" SG_ 2015 signal5208 0;
BA_ "GenSigAutoGenDsp" SG_ 2015 signal5208 0;
BA_ "GenSigTimeoutMsg_ecu11765" SG_ 2017 signal5227_Data 2017;
BA_ "signal131970" SG_ 2017 signal5227_Data 2017;
BA_ "signal131977" SG_ 2017 signal5227_Data 2017;
BA_ "NMH-WakeupAllowed" SG_ 2017 signal5227_Data 0;
BA_ "NWM-WakeupAllowed" SG_ 2017 signal5227_Data 0;
BA_ "GenSigSendType" SG_ 2017 signal5227_Data 7;
BA_ "GenSigEnvVarType" SG_ 2017 signal5227_Data 0;
BA_ "GenSigAutoGenSnd" SG_ 2017 signal5227_Data 0;
BA_ "GenSigAutoGenDsp" SG_ 2017 signal5227_Data 0;
BA_ "GenSigTimeoutMsg_ecu13186" SG_ 2025 signal5251 2025;
BA_ "NMH-WakeupAllowed" SG_ 2025 signal5251 0;
BA_ "NWM-WakeupAllowed" SG_ 2025 signal5251 0;
BA_ "GenSigSendType" SG_ 2025 signal5251 7;
BA_ "GenSigEnvVarType" SG_ 2025 signal5251 0;
BA_ "GenSigAutoGenSnd" SG_ 2025 signal5251 0;
BA_ "GenSigAutoGenDsp" SG_ 2025 signal5251 0;
BA_ "signal136198" SG_ 2016 signal5263_Data 2016;
BA_ "signal133356" SG_ 2016 signal5263_Data 2016;
BA_ "GenSigTimeoutMsg_ecu13120" SG_ 2016 signal5263_Data 2016;
BA_ "NMH-WakeupAllowed" SG_ 2016 signal5263_Data 0;
BA_ "NWM-WakeupAllowed" SG_ 2016 signal5263_Data 0;
BA_ "GenSigSendType" SG_ 2016 signal5263_Data 7;
BA_ "GenSigEnvVarType" SG_ 2016 signal5263_Data 0;
BA_ "GenSigAutoGenSnd" SG_ 2016 signal5263_Data 0;
BA_ "GenSigAutoGenDsp" SG_ 2016 signal5263_Data 0;
BA_ "GenSigTimeoutMsg_ecu13186" SG_ 2024 signal5282_Data 2024;
BA_ "NMH-WakeupAllowed" SG_ 2024 signal5282_Data 0;
BA_ "NWM-WakeupAllowed" SG_ 2024 signal5282_Data 0;
BA_ "GenSigSendType" SG_ 2024 signal5282_Data 7;
BA_ "GenSigEnvVarType" SG_ 2024 signal5282_Data 0;
BA_ "GenSigAutoGenSnd" SG_ 2024 signal5282_Data 0;
BA_ "GenSigAutoGenDsp" SG_ 2024 signal5282_Data 0;
BA_ "GenSigTimeoutMsg_ecu8948" SG_ 2018 signal5304 2018;
BA_ "NMH-WakeupAllowed" SG_ 2018 signal5304 0;
BA_ "NWM-WakeupAllowed" SG_ 2018 signal5304 0;
BA_ "GenSigSendType" SG_ 2018 signal5304 7;
BA_ "GenSigEnvVarType" SG_ 2018 signal5304 0;
BA_ "GenSigAutoGenSnd" SG_ 2018 signal5304 0;
BA_ "GenSigAutoGenDsp" SG_ 2018 signal5304 0;
BA_ "GenSigTimeoutMsg_ecu13186" SG_ 2026 signal5321 2026;
BA_ "NMH-WakeupAllowed" SG_ 2026 signal5321 0;
BA_ "NWM-WakeupAllowed" SG_ 2026 signal5321 0;
BA_ "GenSigSendType" SG_ 2026 signal5321 7;
BA_ "GenSigEnvVarType" SG_ 2026 signal5321 0;
BA_ "GenSigAutoGenSnd" SG_ 2026 signal5321 0;
BA_ "GenSigAutoGenDsp" SG_ 2026 signal5321 0;
BA_ "NMH-WakeupAllowed" SG_ 2019 signal5333_Data 0;
BA_ "NWM-WakeupAllowed" SG_ 2019 signal5333_Data 0;
BA_ "GenSigSendType" SG_ 2019 signal5333_Data 7;
BA_ "GenSigEnvVarType" SG_ 2019 signal5333_Data 0;
BA_ "GenSigAutoGenSnd" SG_ 2019 signal5333_Data 0;
BA_ "GenSigAutoGenDsp" SG_ 2019 signal5333_Data 0;
BA_ "GenSigTimeoutMsg_ecu13186" SG_ 2027 signal5349_Data 2027;
BA_ "NMH-WakeupAllowed" SG_ 2027 signal5349_Data 0;
BA_ "NWM-WakeupAllowed" SG_ 2027 signal5349_Data 0;
BA_ "GenSigSendType" SG_ 2027 signal5349_Data 7;
BA_ "GenSigEnvVarType" SG_ 2027 signal5349_Data 0;
BA_ "GenSigAutoGenSnd" SG_ 2027 signal5349_Data 0;
BA_ "GenSigAutoGenDsp" SG_ 2027 signal5349_Data 0;
BA_ "GenSigTimeoutMsg_ecu5385" SG_ 1875 signal5371 1875;
BA_ "NMH-WakeupAllowed" SG_ 1875 signal5371 0;
BA_ "NWM-WakeupAllowed" SG_ 1875 signal5371 0;
BA_ "GenSigSendType" SG_ 1875 signal5371 7;
BA_ "GenSigEVName" SG_ 1875 signal5371 "@signame";
BA_ "GenSigAutoGenSnd" SG_ 1875 signal5371 1;
BA_ "GenSigAutoGenDsp" SG_ 1875 signal5371 1;
BA_ "GenSigTimeoutMsg_ecu13186" SG_ 1981 signal5388 1981;
BA_ "NMH-WakeupAllowed" SG_ 1981 signal5388 0;
BA_ "NWM-WakeupAllowed" SG_ 1981 signal5388 0;
BA_ "GenSigSendType" SG_ 1981 signal5388 7;
BA_ "GenSigEVName" SG_ 1981 signal5388 "@signame";
BA_ "GenSigAutoGenSnd" SG_ 1981 signal5388 1;
BA_ "GenSigAutoGenDsp" SG_ 1981 signal5388 1;
BA_ "NMH-WakeupAllowed" SG_ 1424 signal5405 0;
BA_ "NWM-WakeupAllowed" SG_ 1424 signal5405 0;
BA_ "GenSigSendType" SG_ 1424 signal5405 7;
BA_ "GenSigEnvVarType" SG_ 1424 signal5405 0;
BA_ "GenSigAutoGenSnd" SG_ 1424 signal5405 1;
BA_ "GenSigAutoGenDsp" SG_ 1424 signal5405 1;
BA_ "NMH-WakeupAllowed" SG_ 1424 signal5415 0;
BA_ "NWM-WakeupAllowed" SG_ 1424 signal5415 0;
BA_ "GenSigSendType" SG_ 1424 signal5415 7;
BA_ "GenSigEnvVarType" SG_ 1424 signal5415 0;
BA_ "GenSigAutoGenSnd" SG_ 1424 signal5415 1;
BA_ "GenSigAutoGenDsp" SG_ 1424 signal5415 1;
BA_ "NMH-WakeupAllowed" SG_ 1424 signal5425 0;
BA_ "NWM-WakeupAllowed" SG_ 1424 signal5425 0;
BA_ "GenSigSendType" SG_ 1424 signal5425 7;
BA_ "GenSigEnvVarType" SG_ 1424 signal5425 0;
BA_ "GenSigAutoGenSnd" SG_ 1424 signal5425 1;
BA_ "GenSigAutoGenDsp" SG_ 1424 signal5425 1;
BA_ "NMH-WakeupAllowed" SG_ 1424 signal5435 0;
BA_ "NWM-WakeupAllowed" SG_ 1424 signal5435 0;
BA_ "GenSigSendType" SG_ 1424 signal5435 7;
BA_ "GenSigEnvVarType" SG_ 1424 signal5435 0;
BA_ "GenSigAutoGenSnd" SG_ 1424 signal5435 1;
BA_ "GenSigAutoGenDsp" SG_ 1424 signal5435 1;
BA_ "NMH-WakeupAllowed" SG_ 1424 signal5445 0;
BA_ "NWM-WakeupAllowed" SG_ 1424 signal5445 0;
BA_ "GenSigSendType" SG_ 1424 signal5445 7;
BA_ "GenSigEnvVarType" SG_ 1424 signal5445 0;
BA_ "GenSigAutoGenSnd" SG_ 1424 signal5445 1;
BA_ "GenSigAutoGenDsp" SG_ 1424 signal5445 1;
BA_ "NMH-WakeupAllowed" SG_ 1424 signal5455 0;
BA_ "NWM-WakeupAllowed" SG_ 1424 signal5455 0;
BA_ "GenSigSendType" SG_ 1424 signal5455 7;
BA_ "GenSigEnvVarType" SG_ 1424 signal5455 0;
BA_ "GenSigAutoGenSnd" SG_ 1424 signal5455 1;
BA_ "GenSigAutoGenDsp" SG_ 1424 signal5455 1;
BA_ "GenSigTimeoutMsg_ecu12594" SG_ 1424 signal5465 1424;
BA_ "NMH-WakeupAllowed" SG_ 1424 signal5465 0;
BA_ "NWM-WakeupAllowed" SG_ 1424 signal5465 0;
BA_ "GenSigSendType" SG_ 1424 signal5465 7;
BA_ "GenSigEnvVarType" SG_ 1424 signal5465 0;
BA_ "GenSigAutoGenSnd" SG_ 1424 signal5465 1;
BA_ "GenSigAutoGenDsp" SG_ 1424 signal5465 1;
BA_ "GenSigTimeoutMsg_ecu12594" SG_ 1424 signal5476 1424;
BA_ "NMH-WakeupAllowed" SG_ 1424 signal5476 0;
BA_ "NWM-WakeupAllowed" SG_ 1424 signal5476 0;
BA_ "GenSigSendType" SG_ 1424 signal5476 7;
BA_ "GenSigEnvVarType" SG_ 1424 signal5476 0;
BA_ "GenSigAutoGenSnd" SG_ 1424 signal5476 1;
BA_ "GenSigAutoGenDsp" SG_ 1424 signal5476 1;
BA_ "NMH-WakeupAllowed" SG_ 1424 signal5487 0;
BA_ "NWM-WakeupAllowed" SG_ 1424 signal5487 0;
BA_ "GenSigSendType" SG_ 1424 signal5487 7;
BA_ "GenSigEnvVarType" SG_ 1424 signal5487 0;
BA_ "GenSigAutoGenSnd" SG_ 1424 signal5487 1;
BA_ "GenSigAutoGenDsp" SG_ 1424 signal5487 1;
BA_ "NMH-WakeupAllowed" SG_ 1424 signal5497 0;
BA_ "NWM-WakeupAllowed" SG_ 1424 signal5497 0;
BA_ "GenSigSendType" SG_ 1424 signal5497 7;
BA_ "GenSigEnvVarType" SG_ 1424 signal5497 0;
BA_ "GenSigAutoGenSnd" SG_ 1424 signal5497 1;
BA_ "GenSigAutoGenDsp" SG_ 1424 signal5497 1;
BA_ "NMH-WakeupAllowed" SG_ 1424 signal5507 0;
BA_ "NWM-WakeupAllowed" SG_ 1424 signal5507 0;
BA_ "GenSigSendType" SG_ 1424 signal5507 7;
BA_ "GenSigEnvVarType" SG_ 1424 signal5507 0;
BA_ "GenSigAutoGenSnd" SG_ 1424 signal5507 1;
BA_ "GenSigAutoGenDsp" SG_ 1424 signal5507 1;
BA_ "NMH-WakeupAllowed" SG_ 1424 signal5517 0;
BA_ "NWM-WakeupAllowed" SG_ 1424 signal5517 0;
BA_ "GenSigSendType" SG_ 1424 signal5517 7;
BA_ "GenSigEnvVarType" SG_ 1424 signal5517 0;
BA_ "GenSigAutoGenSnd" SG_ 1424 signal5517 1;
BA_ "GenSigAutoGenDsp" SG_ 1424 signal5517 1;
BA_ "NMH-WakeupAllowed" SG_ 1424 signal5527 0;
BA_ "NWM-WakeupAllowed" SG_ 1424 signal5527 0;
BA_ "GenSigSendType" SG_ 1424 signal5527 7;
BA_ "GenSigEnvVarType" SG_ 1424 signal5527 0;
BA_ "GenSigAutoGenSnd" SG_ 1424 signal5527 1;
BA_ "GenSigAutoGenDsp" SG_ 1424 signal5527 1;
BA_ "NMH-WakeupAllowed" SG_ 1424 signal5537 0;
BA_ "NWM-WakeupAllowed" SG_ 1424 signal5537 0;
BA_ "GenSigSendType" SG_ 1424 signal5537 7;
BA_ "GenSigEnvVarType" SG_ 1424 signal5537 0;
BA_ "GenSigAutoGenSnd" SG_ 1424 signal5537 1;
BA_ "GenSigAutoGenDsp" SG_ 1424 signal5537 1;
BA_ "NMH-WakeupAllowed" SG_ 1424 signal5547 0;
BA_ "NWM-WakeupAllowed" SG_ 1424 signal5547 0;
BA_ "GenSigSendType" SG_ 1424 signal5547 7;
BA_ "GenSigEnvVarType" SG_ 1424 signal5547 0;
BA_ "GenSigAutoGenSnd" SG_ 1424 signal5547 1;
BA_ "GenSigAutoGenDsp" SG_ 1424 signal5547 1;
BA_ "NMH-WakeupAllowed" SG_ 1424 signal5557 0;
BA_ "NWM-WakeupAllowed" SG_ 1424 signal5557 0;
BA_ "GenSigSendType" SG_ 1424 signal5557 7;
BA_ "GenSigEnvVarType" SG_ 1424 signal5557 0;
BA_ "GenSigAutoGenSnd" SG_ 1424 signal5557 1;
BA_ "GenSigAutoGenDsp" SG_ 1424 signal5557 1;
BA_ "NMH-WakeupAllowed" SG_ 1424 signal5567 0;
BA_ "NWM-WakeupAllowed" SG_ 1424 signal5567 0;
BA_ "GenSigSendType" SG_ 1424 signal5567 7;
BA_ "GenSigEnvVarType" SG_ 1424 signal5567 0;
BA_ "GenSigAutoGenSnd" SG_ 1424 signal5567 1;
BA_ "GenSigAutoGenDsp" SG_ 1424 signal5567 1;
BA_ "NMH-WakeupAllowed" SG_ 1424 signal5577 0;
BA_ "NWM-WakeupAllowed" SG_ 1424 signal5577 0;
BA_ "GenSigSendType" SG_ 1424 signal5577 7;
BA_ "GenSigEnvVarType" SG_ 1424 signal5577 0;
BA_ "GenSigAutoGenSnd" SG_ 1424 signal5577 1;
BA_ "GenSigAutoGenDsp" SG_ 1424 signal5577 1;
BA_ "NMH-WakeupAllowed" SG_ 1424 signal5587 0;
BA_ "NWM-WakeupAllowed" SG_ 1424 signal5587 0;
BA_ "GenSigSendType" SG_ 1424 signal5587 7;
BA_ "GenSigEnvVarType" SG_ 1424 signal5587 0;
BA_ "GenSigAutoGenSnd" SG_ 1424 signal5587 1;
BA_ "GenSigAutoGenDsp" SG_ 1424 signal5587 1;
BA_ "NMH-WakeupAllowed" SG_ 1424 signal5597 0;
BA_ "NWM-WakeupAllowed" SG_ 1424 signal5597 0;
BA_ "GenSigSendType" SG_ 1424 signal5597 7;
BA_ "GenSigEnvVarType" SG_ 1424 signal5597 0;
BA_ "GenSigAutoGenSnd" SG_ 1424 signal5597 1;
BA_ "GenSigAutoGenDsp" SG_ 1424 signal5597 1;
BA_ "NMH-WakeupAllowed" SG_ 1424 signal5607 0;
BA_ "NWM-WakeupAllowed" SG_ 1424 signal5607 0;
BA_ "GenSigSendType" SG_ 1424 signal5607 7;
BA_ "GenSigEnvVarType" SG_ 1424 signal5607 0;
BA_ "GenSigAutoGenSnd" SG_ 1424 signal5607 1;
BA_ "GenSigAutoGenDsp" SG_ 1424 signal5607 1;
BA_ "NMH-WakeupAllowed" SG_ 1424 signal5617 0;
BA_ "NWM-WakeupAllowed" SG_ 1424 signal5617 0;
BA_ "GenSigSendType" SG_ 1424 signal5617 7;
BA_ "GenSigEnvVarType" SG_ 1424 signal5617 0;
BA_ "GenSigAutoGenSnd" SG_ 1424 signal5617 1;
BA_ "GenSigAutoGenDsp" SG_ 1424 signal5617 1;
BA_ "NMH-WakeupAllowed" SG_ 1424 signal5627 0;
BA_ "NWM-WakeupAllowed" SG_ 1424 signal5627 0;
BA_ "GenSigSendType" SG_ 1424 signal5627 7;
BA_ "GenSigEnvVarType" SG_ 1424 signal5627 0;
BA_ "GenSigAutoGenSnd" SG_ 1424 signal5627 1;
BA_ "GenSigAutoGenDsp" SG_ 1424 signal5627 1;
BA_ "NMH-WakeupAllowed" SG_ 1424 signal5637 0;
BA_ "NWM-WakeupAllowed" SG_ 1424 signal5637 0;
BA_ "GenSigSendType" SG_ 1424 signal5637 7;
BA_ "GenSigEnvVarType" SG_ 1424 signal5637 0;
BA_ "GenSigAutoGenSnd" SG_ 1424 signal5637 1;
BA_ "GenSigAutoGenDsp" SG_ 1424 signal5637 1;
BA_ "NMH-WakeupAllowed" SG_ 1424 signal5647 0;
BA_ "NWM-WakeupAllowed" SG_ 1424 signal5647 0;
BA_ "GenSigSendType" SG_ 1424 signal5647 7;
BA_ "GenSigEnvVarType" SG_ 1424 signal5647 0;
BA_ "GenSigAutoGenSnd" SG_ 1424 signal5647 1;
BA_ "GenSigAutoGenDsp" SG_ 1424 signal5647 1;
BA_ "NMH-WakeupAllowed" SG_ 1424 signal5657 0;
BA_ "NWM-WakeupAllowed" SG_ 1424 signal5657 0;
BA_ "GenSigSendType" SG_ 1424 signal5657 7;
BA_ "GenSigEnvVarType" SG_ 1424 signal5657 0;
BA_ "GenSigAutoGenSnd" SG_ 1424 signal5657 1;
BA_ "GenSigAutoGenDsp" SG_ 1424 signal5657 1;
BA_ "NMH-WakeupAllowed" SG_ 1424 signal5667 0;
BA_ "NWM-WakeupAllowed" SG_ 1424 signal5667 0;
BA_ "GenSigSendType" SG_ 1424 signal5667 7;
BA_ "GenSigEnvVarType" SG_ 1424 signal5667 0;
BA_ "GenSigAutoGenSnd" SG_ 1424 signal5667 1;
BA_ "GenSigAutoGenDsp" SG_ 1424 signal5667 1;
BA_ "NMH-WakeupAllowed" SG_ 1424 signal5677 0;
BA_ "NWM-WakeupAllowed" SG_ 1424 signal5677 0;
BA_ "GenSigSendType" SG_ 1424 signal5677 7;
BA_ "GenSigEnvVarType" SG_ 1424 signal5677 0;
BA_ "GenSigAutoGenSnd" SG_ 1424 signal5677 1;
BA_ "GenSigAutoGenDsp" SG_ 1424 signal5677 1;
BA_ "signal136198" SG_ 960 signal5693 960;
BA_ "signal133356" SG_ 960 signal5693 960;
BA_ "GenSigTimeoutMsg_ecu13120" SG_ 960 signal5693 960;
BA_ "signal131970" SG_ 960 signal5693 960;
BA_ "signal131977" SG_ 960 signal5693 960;
BA_ "GenSigTimeoutMsg_ecu12594" SG_ 960 signal5693 960;
BA_ "NMH-WakeupAllowed" SG_ 960 signal5693 0;
BA_ "NWM-WakeupAllowed" SG_ 960 signal5693 0;
BA_ "GenSigSendType" SG_ 960 signal5693 7;
BA_ "GenSigEnvVarType" SG_ 960 signal5693 0;
BA_ "GenSigAutoGenSnd" SG_ 960 signal5693 1;
BA_ "GenSigAutoGenDsp" SG_ 960 signal5693 1;
BA_ "signal136198" SG_ 960 signal5709 960;
BA_ "signal133356" SG_ 960 signal5709 960;
BA_ "GenSigTimeoutMsg_ecu13120" SG_ 960 signal5709 960;
BA_ "signal131970" SG_ 960 signal5709 960;
BA_ "signal131977" SG_ 960 signal5709 960;
BA_ "GenSigTimeoutMsg_ecu12594" SG_ 960 signal5709 960;
BA_ "NMH-WakeupAllowed" SG_ 960 signal5709 0;
BA_ "NWM-WakeupAllowed" SG_ 960 signal5709 0;
BA_ "GenSigSendType" SG_ 960 signal5709 7;
BA_ "GenSigEnvVarType" SG_ 960 signal5709 0;
BA_ "GenSigAutoGenSnd" SG_ 960 signal5709 1;
BA_ "GenSigAutoGenDsp" SG_ 960 signal5709 1;
BA_ "GenSigTimeoutMsg_ecu12594" SG_ 960 signal5725 960;
BA_ "NMH-WakeupAllowed" SG_ 960 signal5725 0;
BA_ "NWM-WakeupAllowed" SG_ 960 signal5725 0;
BA_ "GenSigSendType" SG_ 960 signal5725 7;
BA_ "GenSigEnvVarType" SG_ 960 signal5725 0;
BA_ "GenSigAutoGenSnd" SG_ 960 signal5725 1;
BA_ "GenSigAutoGenDsp" SG_ 960 signal5725 1;
BA_ "GenSigTimeoutMsg_ecu12990" SG_ 960 signal5736 960;
BA_ "signal136198" SG_ 960 signal5736 960;
BA_ "signal133356" SG_ 960 signal5736 960;
BA_ "GenSigTimeoutMsg_ecu13120" SG_ 960 signal5736 960;
BA_ "signal131970" SG_ 960 signal5736 960;
BA_ "signal131977" SG_ 960 signal5736 960;
BA_ "GenSigTimeoutMsg_ecu12594" SG_ 960 signal5736 960;
BA_ "NMH-WakeupAllowed" SG_ 960 signal5736 0;
BA_ "NWM-WakeupAllowed" SG_ 960 signal5736 1;
BA_ "GenSigSendType" SG_ 960 signal5736 7;
BA_ "GenSigEnvVarType" SG_ 960 signal5736 0;
BA_ "GenSigAutoGenSnd" SG_ 960 signal5736 1;
BA_ "GenSigAutoGenDsp" SG_ 960 signal5736 1;
BA_ "GenSigTimeoutMsg_ecu12990" SG_ 960 signal5753 960;
BA_ "GenSigTimeoutMsg_ecu12594" SG_ 960 signal5753 960;
BA_ "NMH-WakeupAllowed" SG_ 960 signal5753 0;
BA_ "NWM-WakeupAllowed" SG_ 960 signal5753 0;
BA_ "GenSigSendType" SG_ 960 signal5753 7;
BA_ "GenSigEnvVarType" SG_ 960 signal5753 0;
BA_ "GenSigAutoGenSnd" SG_ 960 signal5753 1;
BA_ "GenSigAutoGenDsp" SG_ 960 signal5753 1;
BA_ "signal136198" SG_ 960 signal5765 960;
BA_ "signal133356" SG_ 960 signal5765 960;
BA_ "GenSigTimeoutMsg_ecu13120" SG_ 960 signal5765 960;
BA_ "GenSigTimeoutMsg_ecu12594" SG_ 960 signal5765 960;
BA_ "NMH-WakeupAllowed" SG_ 960 signal5765 0;
BA_ "NWM-WakeupAllowed" SG_ 960 signal5765 0;
BA_ "GenSigSendType" SG_ 960 signal5765 7;
BA_ "GenSigEnvVarType" SG_ 960 signal5765 0;
BA_ "GenSigAutoGenSnd" SG_ 960 signal5765 1;
BA_ "GenSigAutoGenDsp" SG_ 960 signal5765 1;
BA_ "signal136198" SG_ 959 signal5785 959;
BA_ "signal133356" SG_ 959 signal5785 959;
BA_ "GenSigTimeoutMsg_ecu13120" SG_ 959 signal5785 959;
BA_ "NMH-WakeupAllowed" SG_ 959 signal5785 0;
BA_ "NWM-WakeupAllowed" SG_ 959 signal5785 0;
BA_ "GenSigSendType" SG_ 959 signal5785 7;
BA_ "GenSigEnvVarType" SG_ 959 signal5785 0;
BA_ "GenSigAutoGenSnd" SG_ 959 signal5785 1;
BA_ "GenSigAutoGenDsp" SG_ 959 signal5785 1;
BA_ "signal136198" SG_ 959 signal5798 959;
BA_ "signal133356" SG_ 959 signal5798 959;
BA_ "GenSigTimeoutMsg_ecu13120" SG_ 959 signal5798 959;
BA_ "NMH-WakeupAllowed" SG_ 959 signal5798 0;
BA_ "NWM-WakeupAllowed" SG_ 959 signal5798 0;
BA_ "GenSigSendType" SG_ 959 signal5798 7;
BA_ "GenSigEnvVarType" SG_ 959 signal5798 0;
BA_ "GenSigAutoGenSnd" SG_ 959 signal5798 1;
BA_ "GenSigAutoGenDsp" SG_ 959 signal5798 1;
BA_ "NMH-WakeupAllowed" SG_ 959 signal5811 0;
BA_ "NWM-WakeupAllowed" SG_ 959 signal5811 0;
BA_ "GenSigSendType" SG_ 959 signal5811 7;
BA_ "GenSigEnvVarType" SG_ 959 signal5811 0;
BA_ "GenSigAutoGenSnd" SG_ 959 signal5811 1;
BA_ "GenSigAutoGenDsp" SG_ 959 signal5811 1;
BA_ "NMH-WakeupAllowed" SG_ 959 signal5821 0;
BA_ "NWM-WakeupAllowed" SG_ 959 signal5821 0;
BA_ "GenSigSendType" SG_ 959 signal5821 7;
BA_ "GenSigEnvVarType" SG_ 959 signal5821 0;
BA_ "GenSigAutoGenSnd" SG_ 959 signal5821 1;
BA_ "GenSigAutoGenDsp" SG_ 959 signal5821 1;
BA_ "signal136198" SG_ 959 signal5831 959;
BA_ "signal133356" SG_ 959 signal5831 959;
BA_ "GenSigTimeoutMsg_ecu13120" SG_ 959 signal5831 959;
BA_ "NMH-WakeupAllowed" SG_ 959 signal5831 0;
BA_ "NWM-WakeupAllowed" SG_ 959 signal5831 0;
BA_ "GenSigSendType" SG_ 959 signal5831 7;
BA_ "GenSigEnvVarType" SG_ 959 signal5831 0;
BA_ "GenSigAutoGenSnd" SG_ 959 signal5831 1;
BA_ "GenSigAutoGenDsp" SG_ 959 signal5831 1;
BA_ "signal136198" SG_ 959 signal5844 959;
BA_ "signal133356" SG_ 959 signal5844 959;
BA_ "GenSigTimeoutMsg_ecu13120" SG_ 959 signal5844 959;
BA_ "NMH-WakeupAllowed" SG_ 959 signal5844 0;
BA_ "NWM-WakeupAllowed" SG_ 959 signal5844 0;
BA_ "GenSigSendType" SG_ 959 signal5844 7;
BA_ "GenSigEnvVarType" SG_ 959 signal5844 0;
BA_ "GenSigAutoGenSnd" SG_ 959 signal5844 1;
BA_ "GenSigAutoGenDsp" SG_ 959 signal5844 1;
BA_ "NMH-WakeupAllowed" SG_ 959 signal5857 0;
BA_ "NWM-WakeupAllowed" SG_ 959 signal5857 0;
BA_ "GenSigSendType" SG_ 959 signal5857 7;
BA_ "GenSigEnvVarType" SG_ 959 signal5857 0;
BA_ "GenSigAutoGenSnd" SG_ 959 signal5857 1;
BA_ "GenSigAutoGenDsp" SG_ 959 signal5857 1;
BA_ "NMH-WakeupAllowed" SG_ 959 signal5867 0;
BA_ "NWM-WakeupAllowed" SG_ 959 signal5867 0;
BA_ "GenSigSendType" SG_ 959 signal5867 7;
BA_ "GenSigEnvVarType" SG_ 959 signal5867 0;
BA_ "GenSigAutoGenSnd" SG_ 959 signal5867 1;
BA_ "GenSigAutoGenDsp" SG_ 959 signal5867 1;
BA_ "NMH-WakeupAllowed" SG_ 959 signal5877 0;
BA_ "NWM-WakeupAllowed" SG_ 959 signal5877 0;
BA_ "GenSigSendType" SG_ 959 signal5877 7;
BA_ "GenSigEnvVarType" SG_ 959 signal5877 0;
BA_ "GenSigAutoGenSnd" SG_ 959 signal5877 1;
BA_ "GenSigAutoGenDsp" SG_ 959 signal5877 1;
BA_ "signal136198" SG_ 959 signal5887 959;
BA_ "signal133356" SG_ 959 signal5887 959;
BA_ "GenSigTimeoutMsg_ecu13120" SG_ 959 signal5887 959;
BA_ "NMH-WakeupAllowed" SG_ 959 signal5887 0;
BA_ "NWM-WakeupAllowed" SG_ 959 signal5887 0;
BA_ "GenSigSendType" SG_ 959 signal5887 7;
BA_ "GenSigEnvVarType" SG_ 959 signal5887 1;
BA_ "GenSigAutoGenSnd" SG_ 959 signal5887 1;
BA_ "GenSigAutoGenDsp" SG_ 959 signal5887 1;
BA_ "signal136198" SG_ 959 signal5900 959;
BA_ "signal133356" SG_ 959 signal5900 959;
BA_ "GenSigTimeoutMsg_ecu13120" SG_ 959 signal5900 959;
BA_ "NMH-WakeupAllowed" SG_ 959 signal5900 0;
BA_ "NWM-WakeupAllowed" SG_ 959 signal5900 0;
BA_ "GenSigSendType" SG_ 959 signal5900 7;
BA_ "GenSigEnvVarType" SG_ 959 signal5900 1;
BA_ "GenSigAutoGenSnd" SG_ 959 signal5900 1;
BA_ "GenSigAutoGenDsp" SG_ 959 signal5900 1;
BA_ "signal136198" SG_ 959 signal5913 959;
BA_ "signal133356" SG_ 959 signal5913 959;
BA_ "GenSigTimeoutMsg_ecu13120" SG_ 959 signal5913 959;
BA_ "NMH-WakeupAllowed" SG_ 959 signal5913 0;
BA_ "NWM-WakeupAllowed" SG_ 959 signal5913 0;
BA_ "GenSigSendType" SG_ 959 signal5913 7;
BA_ "GenSigEnvVarType" SG_ 959 signal5913 0;
BA_ "GenSigAutoGenSnd" SG_ 959 signal5913 1;
BA_ "GenSigAutoGenDsp" SG_ 959 signal5913 1;
BA_ "NMH-WakeupAllowed" SG_ 959 signal5926 0;
BA_ "NWM-WakeupAllowed" SG_ 959 signal5926 0;
BA_ "GenSigSendType" SG_ 959 signal5926 7;
BA_ "GenSigEnvVarType" SG_ 959 signal5926 0;
BA_ "GenSigAutoGenSnd" SG_ 959 signal5926 1;
BA_ "GenSigAutoGenDsp" SG_ 959 signal5926 1;
BA_ "signal136198" SG_ 959 signal5936 959;
BA_ "signal133356" SG_ 959 signal5936 959;
BA_ "GenSigTimeoutMsg_ecu13120" SG_ 959 signal5936 959;
BA_ "NMH-WakeupAllowed" SG_ 959 signal5936 0;
BA_ "NWM-WakeupAllowed" SG_ 959 signal5936 0;
BA_ "GenSigSendType" SG_ 959 signal5936 7;
BA_ "GenSigEnvVarType" SG_ 959 signal5936 0;
BA_ "GenSigAutoGenSnd" SG_ 959 signal5936 1;
BA_ "GenSigAutoGenDsp" SG_ 959 signal5936 1;
BA_ "GenSigTimeoutMsg_ecu13120" SG_ 959 signal5949 959;
BA_ "NMH-WakeupAllowed" SG_ 959 signal5949 0;
BA_ "NWM-WakeupAllowed" SG_ 959 signal5949 0;
BA_ "GenSigSendType" SG_ 959 signal5949 7;
BA_ "GenSigEnvVarType" SG_ 959 signal5949 0;
BA_ "GenSigAutoGenSnd" SG_ 959 signal5949 1;
BA_ "GenSigAutoGenDsp" SG_ 959 signal5949 1;
BA_ "GenSigTimeoutMsg_ecu12990" SG_ 1646 signal5966 1646;
BA_ "NMH-WakeupAllowed" SG_ 1646 signal5966 0;
BA_ "NWM-WakeupAllowed" SG_ 1646 signal5966 0;
BA_ "GenSigSendType" SG_ 1646 signal5966 7;
BA_ "GenSigEnvVarType" SG_ 1646 signal5966 0;
BA_ "GenSigAutoGenSnd" SG_ 1646 signal5966 1;
BA_ "GenSigAutoGenDsp" SG_ 1646 signal5966 1;
BA_ "GenSigTimeoutMsg_ecu12990" SG_ 1646 signal5977 1646;
BA_ "NMH-WakeupAllowed" SG_ 1646 signal5977 0;
BA_ "NWM-WakeupAllowed" SG_ 1646 signal5977 0;
BA_ "GenSigSendType" SG_ 1646 signal5977 7;
BA_ "GenSigEnvVarType" SG_ 1646 signal5977 0;
BA_ "GenSigAutoGenSnd" SG_ 1646 signal5977 1;
BA_ "GenSigAutoGenDsp" SG_ 1646 signal5977 1;
BA_ "GenSigTimeoutMsg_ecu12990" SG_ 1646 signal5988 1646;
BA_ "NMH-WakeupAllowed" SG_ 1646 signal5988 0;
BA_ "NWM-WakeupAllowed" SG_ 1646 signal5988 0;
BA_ "GenSigSendType" SG_ 1646 signal5988 7;
BA_ "GenSigEnvVarType" SG_ 1646 signal5988 0;
BA_ "GenSigAutoGenSnd" SG_ 1646 signal5988 1;
BA_ "GenSigAutoGenDsp" SG_ 1646 signal5988 1;
BA_ "NMH-WakeupAllowed" SG_ 1646 signal5999 0;
BA_ "NWM-WakeupAllowed" SG_ 1646 signal5999 0;
BA_ "GenSigSendType" SG_ 1646 signal5999 7;
BA_ "GenSigEnvVarType" SG_ 1646 signal5999 0;
BA_ "GenSigAutoGenSnd" SG_ 1646 signal5999 1;
BA_ "GenSigAutoGenDsp" SG_ 1646 signal5999 1;
BA_ "GenSigTimeoutMsg_ecu12990" SG_ 1646 signal6009 1646;
BA_ "NMH-WakeupAllowed" SG_ 1646 signal6009 0;
BA_ "NWM-WakeupAllowed" SG_ 1646 signal6009 0;
BA_ "GenSigSendType" SG_ 1646 signal6009 7;
BA_ "GenSigEnvVarType" SG_ 1646 signal6009 0;
BA_ "GenSigAutoGenSnd" SG_ 1646 signal6009 1;
BA_ "GenSigAutoGenDsp" SG_ 1646 signal6009 1;
BA_ "GenSigTimeoutMsg_ecu12990" SG_ 1646 signal6020 1646;
BA_ "NMH-WakeupAllowed" SG_ 1646 signal6020 0;
BA_ "NWM-WakeupAllowed" SG_ 1646 signal6020 0;
BA_ "GenSigSendType" SG_ 1646 signal6020 7;
BA_ "GenSigEnvVarType" SG_ 1646 signal6020 0;
BA_ "GenSigAutoGenSnd" SG_ 1646 signal6020 1;
BA_ "GenSigAutoGenDsp" SG_ 1646 signal6020 1;
BA_ "GenSigTimeoutMsg_ecu12990" SG_ 1646 signal6031 1646;
BA_ "NMH-WakeupAllowed" SG_ 1646 signal6031 0;
BA_ "NWM-WakeupAllowed" SG_ 1646 signal6031 0;
BA_ "GenSigSendType" SG_ 1646 signal6031 7;
BA_ "GenSigEnvVarType" SG_ 1646 signal6031 0;
BA_ "GenSigAutoGenSnd" SG_ 1646 signal6031 1;
BA_ "GenSigAutoGenDsp" SG_ 1646 signal6031 1;
BA_ "NMH-WakeupAllowed" SG_ 1646 signal6042 0;
BA_ "NWM-WakeupAllowed" SG_ 1646 signal6042 0;
BA_ "GenSigSendType" SG_ 1646 signal6042 7;
BA_ "GenSigEnvVarType" SG_ 1646 signal6042 0;
BA_ "GenSigAutoGenSnd" SG_ 1646 signal6042 1;
BA_ "GenSigAutoGenDsp" SG_ 1646 signal6042 1;
BA_ "NMH-WakeupAllowed" SG_ 1646 signal6052 0;
BA_ "NWM-WakeupAllowed" SG_ 1646 signal6052 0;
BA_ "GenSigSendType" SG_ 1646 signal6052 7;
BA_ "GenSigEVName" SG_ 1646 signal6052 "@signame";
BA_ "GenSigAutoGenSnd" SG_ 1646 signal6052 1;
BA_ "GenSigAutoGenDsp" SG_ 1646 signal6052 1;
BA_ "NMH-WakeupAllowed" SG_ 1646 signal6062 0;
BA_ "NWM-WakeupAllowed" SG_ 1646 signal6062 0;
BA_ "GenSigSendType" SG_ 1646 signal6062 7;
BA_ "GenSigEVName" SG_ 1646 signal6062 "@signame";
BA_ "GenSigAutoGenSnd" SG_ 1646 signal6062 1;
BA_ "GenSigAutoGenDsp" SG_ 1646 signal6062 1;
BA_ "NMH-WakeupAllowed" SG_ 1646 signal6072 0;
BA_ "NWM-WakeupAllowed" SG_ 1646 signal6072 0;
BA_ "GenSigStartValue" SG_ 1646 signal6072 254;
BA_ "GenSigSendType" SG_ 1646 signal6072 7;
BA_ "GenSigEnvVarType" SG_ 1646 signal6072 1;
BA_ "GenSigAutoGenSnd" SG_ 1646 signal6072 1;
BA_ "GenSigAutoGenDsp" SG_ 1646 signal6072 1;
BA_ "NMH-WakeupAllowed" SG_ 1646 signal6082 0;
BA_ "NWM-WakeupAllowed" SG_ 1646 signal6082 0;
BA_ "GenSigSendType" SG_ 1646 signal6082 7;
BA_ "GenSigEnvVarType" SG_ 1646 signal6082 0;
BA_ "GenSigAutoGenSnd" SG_ 1646 signal6082 1;
BA_ "GenSigAutoGenDsp" SG_ 1646 signal6082 1;
BA_ "NMH-WakeupAllowed" SG_ 1646 signal6092 0;
BA_ "NWM-WakeupAllowed" SG_ 1646 signal6092 0;
BA_ "GenSigStartValue" SG_ 1646 signal6092 254;
BA_ "GenSigSendType" SG_ 1646 signal6092 7;
BA_ "GenSigEnvVarType" SG_ 1646 signal6092 1;
BA_ "GenSigAutoGenSnd" SG_ 1646 signal6092 1;
BA_ "GenSigAutoGenDsp" SG_ 1646 signal6092 1;
BA_ "GenSigTimeoutMsg_ecu12990" SG_ 1649 signal6108 1649;
BA_ "NMH-WakeupAllowed" SG_ 1649 signal6108 0;
BA_ "NWM-WakeupAllowed" SG_ 1649 signal6108 0;
BA_ "GenSigSendType" SG_ 1649 signal6108 7;
BA_ "GenSigEVName" SG_ 1649 signal6108 "@signame";
BA_ "GenSigAutoGenSnd" SG_ 1649 signal6108 1;
BA_ "GenSigAutoGenDsp" SG_ 1649 signal6108 1;
BA_ "GenSigTimeoutMsg_ecu12990" SG_ 1649 signal6119 1649;
BA_ "NMH-WakeupAllowed" SG_ 1649 signal6119 0;
BA_ "NWM-WakeupAllowed" SG_ 1649 signal6119 0;
BA_ "GenSigSendType" SG_ 1649 signal6119 7;
BA_ "GenSigEVName" SG_ 1649 signal6119 "@signame";
BA_ "GenSigAutoGenSnd" SG_ 1649 signal6119 1;
BA_ "GenSigAutoGenDsp" SG_ 1649 signal6119 1;
BA_ "GenSigTimeoutMsg_ecu12990" SG_ 1649 signal6130 1649;
BA_ "NMH-WakeupAllowed" SG_ 1649 signal6130 0;
BA_ "NWM-WakeupAllowed" SG_ 1649 signal6130 0;
BA_ "GenSigSendType" SG_ 1649 signal6130 7;
BA_ "GenSigEVName" SG_ 1649 signal6130 "@signame";
BA_ "GenSigAutoGenSnd" SG_ 1649 signal6130 1;
BA_ "GenSigAutoGenDsp" SG_ 1649 signal6130 1;
BA_ "GenSigTimeoutMsg_ecu12990" SG_ 1649 signal6141 1649;
BA_ "NMH-WakeupAllowed" SG_ 1649 signal6141 0;
BA_ "NWM-WakeupAllowed" SG_ 1649 signal6141 0;
BA_ "GenSigSendType" SG_ 1649 signal6141 7;
BA_ "GenSigEVName" SG_ 1649 signal6141 "@signame";
BA_ "GenSigAutoGenSnd" SG_ 1649 signal6141 1;
BA_ "GenSigAutoGenDsp" SG_ 1649 signal6141 1;
BA_ "GenSigTimeoutMsg_ecu12990" SG_ 1649 signal6152 1649;
BA_ "NMH-WakeupAllowed" SG_ 1649 signal6152 0;
BA_ "NWM-WakeupAllowed" SG_ 1649 signal6152 0;
BA_ "GenSigSendType" SG_ 1649 signal6152 7;
BA_ "GenSigEVName" SG_ 1649 signal6152 "@signame";
BA_ "GenSigAutoGenSnd" SG_ 1649 signal6152 1;
BA_ "GenSigAutoGenDsp" SG_ 1649 signal6152 1;
BA_ "GenSigTimeoutMsg_ecu12990" SG_ 1649 signal6163 1649;
BA_ "NMH-WakeupAllowed" SG_ 1649 signal6163 0;
BA_ "NWM-WakeupAllowed" SG_ 1649 signal6163 0;
BA_ "GenSigSendType" SG_ 1649 signal6163 7;
BA_ "GenSigEVName" SG_ 1649 signal6163 "@signame";
BA_ "GenSigAutoGenSnd" SG_ 1649 signal6163 1;
BA_ "GenSigAutoGenDsp" SG_ 1649 signal6163 1;
BA_ "NMH-WakeupAllowed" SG_ 779 signal6180 0;
BA_ "NWM-WakeupAllowed" SG_ 779 signal6180 0;
BA_ "GenSigSendType" SG_ 779 signal6180 7;
BA_ "GenSigEnvVarType" SG_ 779 signal6180 0;
BA_ "GenSigAutoGenSnd" SG_ 779 signal6180 1;
BA_ "GenSigAutoGenDsp" SG_ 779 signal6180 1;
BA_ "NMH-WakeupAllowed" SG_ 779 signal6190 0;
BA_ "NWM-WakeupAllowed" SG_ 779 signal6190 0;
BA_ "GenSigSendType" SG_ 779 signal6190 7;
BA_ "GenSigEnvVarType" SG_ 779 signal6190 0;
BA_ "GenSigAutoGenSnd" SG_ 779 signal6190 1;
BA_ "GenSigAutoGenDsp" SG_ 779 signal6190 1;
BA_ "NMH-WakeupAllowed" SG_ 779 signal6200 0;
BA_ "NWM-WakeupAllowed" SG_ 779 signal6200 0;
BA_ "GenSigSendType" SG_ 779 signal6200 7;
BA_ "GenSigEnvVarType" SG_ 779 signal6200 0;
BA_ "GenSigAutoGenSnd" SG_ 779 signal6200 1;
BA_ "GenSigAutoGenDsp" SG_ 779 signal6200 1;
BA_ "NMH-WakeupAllowed" SG_ 779 signal6210 0;
BA_ "NWM-WakeupAllowed" SG_ 779 signal6210 0;
BA_ "GenSigSendType" SG_ 779 signal6210 7;
BA_ "GenSigEnvVarType" SG_ 779 signal6210 0;
BA_ "GenSigAutoGenSnd" SG_ 779 signal6210 1;
BA_ "GenSigAutoGenDsp" SG_ 779 signal6210 1;
BA_ "NMH-WakeupAllowed" SG_ 779 signal6220 0;
BA_ "NWM-WakeupAllowed" SG_ 779 signal6220 0;
BA_ "GenSigSendType" SG_ 779 signal6220 7;
BA_ "GenSigEnvVarType" SG_ 779 signal6220 0;
BA_ "GenSigAutoGenSnd" SG_ 779 signal6220 1;
BA_ "GenSigAutoGenDsp" SG_ 779 signal6220 1;
BA_ "NMH-WakeupAllowed" SG_ 779 signal6230 0;
BA_ "NWM-WakeupAllowed" SG_ 779 signal6230 0;
BA_ "GenSigSendType" SG_ 779 signal6230 7;
BA_ "GenSigEnvVarType" SG_ 779 signal6230 0;
BA_ "GenSigAutoGenSnd" SG_ 779 signal6230 1;
BA_ "GenSigAutoGenDsp" SG_ 779 signal6230 1;
BA_ "NMH-WakeupAllowed" SG_ 779 signal6240 0;
BA_ "NWM-WakeupAllowed" SG_ 779 signal6240 0;
BA_ "GenSigSendType" SG_ 779 signal6240 7;
BA_ "GenSigEnvVarType" SG_ 779 signal6240 0;
BA_ "GenSigAutoGenSnd" SG_ 779 signal6240 1;
BA_ "GenSigAutoGenDsp" SG_ 779 signal6240 1;
BA_ "GenSigTimeoutMsg_ecu12990" SG_ 779 signal6250 779;
BA_ "signal136198" SG_ 779 signal6250 779;
BA_ "GenSigTimeoutMsg_ecu13120" SG_ 779 signal6250 779;
BA_ "NMH-WakeupAllowed" SG_ 779 signal6250 0;
BA_ "NWM-WakeupAllowed" SG_ 779 signal6250 0;
BA_ "GenSigSendType" SG_ 779 signal6250 7;
BA_ "GenSigEnvVarType" SG_ 779 signal6250 0;
BA_ "GenSigAutoGenSnd" SG_ 779 signal6250 1;
BA_ "GenSigAutoGenDsp" SG_ 779 signal6250 1;
BA_ "signal136198" SG_ 779 signal6263 779;
BA_ "GenSigTimeoutMsg_ecu13120" SG_ 779 signal6263 779;
BA_ "NMH-WakeupAllowed" SG_ 779 signal6263 0;
BA_ "NWM-WakeupAllowed" SG_ 779 signal6263 0;
BA_ "GenSigSendType" SG_ 779 signal6263 7;
BA_ "GenSigEnvVarType" SG_ 779 signal6263 0;
BA_ "GenSigAutoGenSnd" SG_ 779 signal6263 1;
BA_ "GenSigAutoGenDsp" SG_ 779 signal6263 1;
BA_ "NMH-WakeupAllowed" SG_ 779 signal6275 0;
BA_ "NWM-WakeupAllowed" SG_ 779 signal6275 0;
BA_ "GenSigSendType" SG_ 779 signal6275 7;
BA_ "GenSigEnvVarType" SG_ 779 signal6275 0;
BA_ "GenSigAutoGenSnd" SG_ 779 signal6275 1;
BA_ "GenSigAutoGenDsp" SG_ 779 signal6275 1;
BA_ "NMH-WakeupAllowed" SG_ 779 signal6285 0;
BA_ "NWM-WakeupAllowed" SG_ 779 signal6285 0;
BA_ "GenSigSendType" SG_ 779 signal6285 7;
BA_ "GenSigEnvVarType" SG_ 779 signal6285 0;
BA_ "GenSigAutoGenSnd" SG_ 779 signal6285 1;
BA_ "GenSigAutoGenDsp" SG_ 779 signal6285 1;
BA_ "NMH-WakeupAllowed" SG_ 779 signal6295 0;
BA_ "NWM-WakeupAllowed" SG_ 779 signal6295 0;
BA_ "GenSigSendType" SG_ 779 signal6295 7;
BA_ "GenSigEnvVarType" SG_ 779 signal6295 0;
BA_ "GenSigAutoGenSnd" SG_ 779 signal6295 1;
BA_ "GenSigAutoGenDsp" SG_ 779 signal6295 1;
BA_ "NMH-WakeupAllowed" SG_ 779 signal6305 0;
BA_ "NWM-WakeupAllowed" SG_ 779 signal6305 0;
BA_ "GenSigSendType" SG_ 779 signal6305 7;
BA_ "GenSigEnvVarType" SG_ 779 signal6305 0;
BA_ "GenSigAutoGenSnd" SG_ 779 signal6305 1;
BA_ "GenSigAutoGenDsp" SG_ 779 signal6305 1;
BA_ "signal136198" SG_ 779 signal6315 779;
BA_ "GenSigTimeoutMsg_ecu13120" SG_ 779 signal6315 779;
BA_ "GenSigTimeoutMsg_ecu11765" SG_ 779 signal6315 779;
BA_ "signal131970" SG_ 779 signal6315 779;
BA_ "signal131977" SG_ 779 signal6315 779;
BA_ "NMH-WakeupAllowed" SG_ 779 signal6315 0;
BA_ "NWM-WakeupAllowed" SG_ 779 signal6315 0;
BA_ "GenSigSendType" SG_ 779 signal6315 7;
BA_ "GenSigEnvVarType" SG_ 779 signal6315 1;
BA_ "GenSigAutoGenSnd" SG_ 779 signal6315 1;
BA_ "GenSigAutoGenDsp" SG_ 779 signal6315 1;
BA_ "signal136198" SG_ 779 signal6330 779;
BA_ "GenSigTimeoutMsg_ecu13120" SG_ 779 signal6330 779;
BA_ "signal131970" SG_ 779 signal6330 779;
BA_ "signal131977" SG_ 779 signal6330 779;
BA_ "NMH-WakeupAllowed" SG_ 779 signal6330 0;
BA_ "NWM-WakeupAllowed" SG_ 779 signal6330 0;
BA_ "GenSigSendType" SG_ 779 signal6330 7;
BA_ "GenSigEnvVarType" SG_ 779 signal6330 0;
BA_ "GenSigAutoGenSnd" SG_ 779 signal6330 1;
BA_ "GenSigAutoGenDsp" SG_ 779 signal6330 1;
BA_ "NMH-WakeupAllowed" SG_ 779 signal6344 0;
BA_ "NWM-WakeupAllowed" SG_ 779 signal6344 0;
BA_ "GenSigSendType" SG_ 779 signal6344 7;
BA_ "GenSigEnvVarType" SG_ 779 signal6344 0;
BA_ "GenSigAutoGenSnd" SG_ 779 signal6344 1;
BA_ "GenSigAutoGenDsp" SG_ 779 signal6344 1;
BA_ "NMH-WakeupAllowed" SG_ 779 signal6354 0;
BA_ "NWM-WakeupAllowed" SG_ 779 signal6354 0;
BA_ "GenSigSendType" SG_ 779 signal6354 7;
BA_ "GenSigEnvVarType" SG_ 779 signal6354 0;
BA_ "GenSigAutoGenSnd" SG_ 779 signal6354 1;
BA_ "GenSigAutoGenDsp" SG_ 779 signal6354 1;
BA_ "NMH-WakeupAllowed" SG_ 779 signal6364 0;
BA_ "NWM-WakeupAllowed" SG_ 779 signal6364 0;
BA_ "GenSigSendType" SG_ 779 signal6364 7;
BA_ "GenSigEnvVarType" SG_ 779 signal6364 0;
BA_ "GenSigAutoGenSnd" SG_ 779 signal6364 1;
BA_ "GenSigAutoGenDsp" SG_ 779 signal6364 1;
BA_ "NMH-WakeupAllowed" SG_ 779 signal6374 0;
BA_ "NWM-WakeupAllowed" SG_ 779 signal6374 0;
BA_ "GenSigSendType" SG_ 779 signal6374 7;
BA_ "GenSigEnvVarType" SG_ 779 signal6374 0;
BA_ "GenSigAutoGenSnd" SG_ 779 signal6374 1;
BA_ "GenSigAutoGenDsp" SG_ 779 signal6374 1;
BA_ "NMH-WakeupAllowed" SG_ 1719 signal2014 0;
BA_ "NWM-WakeupAllowed" SG_ 1719 signal2014 0;
BA_ "GenSigStartValue" SG_ 1719 signal2014 1048574;
BA_ "GenSigSendType" SG_ 1719 signal2014 7;
BA_ "GenSigEnvVarType" SG_ 1719 signal2014 0;
BA_ "GenSigAutoGenSnd" SG_ 1719 signal2014 1;
BA_ "GenSigAutoGenDsp" SG_ 1719 signal2014 1;
BA_ "GenSigTimeoutMsg_ecu12990" SG_ 1719 signal6400 1719;
BA_ "signal136198" SG_ 1719 signal6400 1719;
BA_ "signal133356" SG_ 1719 signal6400 1719;
BA_ "GenSigTimeoutMsg_ecu13120" SG_ 1719 signal6400 1719;
BA_ "GenSigTimeoutMsg_ecu11765" SG_ 1719 signal6400 1719;
BA_ "signal131970" SG_ 1719 signal6400 1719;
BA_ "signal131977" SG_ 1719 signal6400 1719;
BA_ "GenSigTimeoutMsg_ecu12594" SG_ 1719 signal6400 1719;
BA_ "NMH-WakeupAllowed" SG_ 1719 signal6400 0;
BA_ "NWM-WakeupAllowed" SG_ 1719 signal6400 0;
BA_ "GenSigSendType" SG_ 1719 signal6400 7;
BA_ "GenSigEnvVarType" SG_ 1719 signal6400 0;
BA_ "GenSigAutoGenSnd" SG_ 1719 signal6400 1;
BA_ "GenSigAutoGenDsp" SG_ 1719 signal6400 1;
BA_ "GenSigTimeoutMsg_ecu12990" SG_ 1719 signal6418 1719;
BA_ "signal136198" SG_ 1719 signal6418 1719;
BA_ "signal133356" SG_ 1719 signal6418 1719;
BA_ "GenSigTimeoutMsg_ecu13120" SG_ 1719 signal6418 1719;
BA_ "GenSigTimeoutMsg_ecu11765" SG_ 1719 signal6418 1719;
BA_ "signal131970" SG_ 1719 signal6418 1719;
BA_ "signal131977" SG_ 1719 signal6418 1719;
BA_ "GenSigTimeoutMsg_ecu12594" SG_ 1719 signal6418 1719;
BA_ "NMH-WakeupAllowed" SG_ 1719 signal6418 0;
BA_ "NWM-WakeupAllowed" SG_ 1719 signal6418 0;
BA_ "GenSigSendType" SG_ 1719 signal6418 7;
BA_ "GenSigEnvVarType" SG_ 1719 signal6418 0;
BA_ "GenSigAutoGenSnd" SG_ 1719 signal6418 1;
BA_ "GenSigAutoGenDsp" SG_ 1719 signal6418 1;
BA_ "signal136198" SG_ 1719 signal6436 1719;
BA_ "signal133356" SG_ 1719 signal6436 1719;
BA_ "GenSigTimeoutMsg_ecu13120" SG_ 1719 signal6436 1719;
BA_ "NMH-WakeupAllowed" SG_ 1719 signal6436 0;
BA_ "NWM-WakeupAllowed" SG_ 1719 signal6436 0;
BA_ "GenSigSendType" SG_ 1719 signal6436 7;
BA_ "GenSigEnvVarType" SG_ 1719 signal6436 0;
BA_ "GenSigAutoGenSnd" SG_ 1719 signal6436 1;
BA_ "GenSigAutoGenDsp" SG_ 1719 signal6436 1;
BA_ "signal136198" SG_ 1719 signal6449 1719;
BA_ "signal133356" SG_ 1719 signal6449 1719;
BA_ "GenSigTimeoutMsg_ecu13120" SG_ 1719 signal6449 1719;
BA_ "NMH-WakeupAllowed" SG_ 1719 signal6449 0;
BA_ "NWM-WakeupAllowed" SG_ 1719 signal6449 0;
BA_ "GenSigSendType" SG_ 1719 signal6449 7;
BA_ "GenSigEnvVarType" SG_ 1719 signal6449 0;
BA_ "GenSigAutoGenSnd" SG_ 1719 signal6449 1;
BA_ "GenSigAutoGenDsp" SG_ 1719 signal6449 1;
BA_ "GenSigTimeoutMsg_ecu12990" SG_ 1719 signal6462 1719;
BA_ "signal136198" SG_ 1719 signal6462 1719;
BA_ "signal133356" SG_ 1719 signal6462 1719;
BA_ "GenSigTimeoutMsg_ecu13120" SG_ 1719 signal6462 1719;
BA_ "GenSigTimeoutMsg_ecu11765" SG_ 1719 signal6462 1719;
BA_ "signal131970" SG_ 1719 signal6462 1719;
BA_ "signal131977" SG_ 1719 signal6462 1719;
BA_ "GenSigTimeoutMsg_ecu12594" SG_ 1719 signal6462 1719;
BA_ "NMH-WakeupAllowed" SG_ 1719 signal6462 0;
BA_ "NWM-WakeupAllowed" SG_ 1719 signal6462 0;
BA_ "GenSigStartValue" SG_ 1719 signal6462 1;
BA_ "GenSigSendType" SG_ 1719 signal6462 7;
BA_ "GenSigEnvVarType" SG_ 1719 signal6462 0;
BA_ "GenSigAutoGenSnd" SG_ 1719 signal6462 1;
BA_ "GenSigAutoGenDsp" SG_ 1719 signal6462 1;
BA_ "GenSigTimeoutMsg_ecu12990" SG_ 1719 signal6480 1719;
BA_ "signal136198" SG_ 1719 signal6480 1719;
BA_ "signal133356" SG_ 1719 signal6480 1719;
BA_ "GenSigTimeoutMsg_ecu13120" SG_ 1719 signal6480 1719;
BA_ "GenSigTimeoutMsg_ecu11765" SG_ 1719 signal6480 1719;
BA_ "signal131970" SG_ 1719 signal6480 1719;
BA_ "signal131977" SG_ 1719 signal6480 1719;
BA_ "GenSigTimeoutMsg_ecu12594" SG_ 1719 signal6480 1719;
BA_ "NMH-WakeupAllowed" SG_ 1719 signal6480 0;
BA_ "NWM-WakeupAllowed" SG_ 1719 signal6480 0;
BA_ "GenSigStartValue" SG_ 1719 signal6480 254;
BA_ "GenSigSendType" SG_ 1719 signal6480 7;
BA_ "GenSigEnvVarType" SG_ 1719 signal6480 1;
BA_ "GenSigAutoGenSnd" SG_ 1719 signal6480 1;
BA_ "GenSigAutoGenDsp" SG_ 1719 signal6480 1;
BA_ "GenSigTimeoutMsg_ecu11765" SG_ 1720 signal6504 1720;
BA_ "signal131970" SG_ 1720 signal6504 1720;
BA_ "signal131977" SG_ 1720 signal6504 1720;
BA_ "NMH-WakeupAllowed" SG_ 1720 signal6504 0;
BA_ "NWM-WakeupAllowed" SG_ 1720 signal6504 0;
BA_ "GenSigSendType" SG_ 1720 signal6504 7;
BA_ "GenSigEnvVarType" SG_ 1720 signal6504 0;
BA_ "GenSigAutoGenSnd" SG_ 1720 signal6504 1;
BA_ "GenSigAutoGenDsp" SG_ 1720 signal6504 1;
BA_ "GenSigTimeoutMsg_ecu13186" SG_ 517 signal6518_Data 517;
BA_ "NMH-WakeupAllowed" SG_ 517 signal6518_Data 0;
BA_ "NWM-WakeupAllowed" SG_ 517 signal6518_Data 0;
BA_ "GenSigSendType" SG_ 517 signal6518_Data 7;
BA_ "GenSigEnvVarType" SG_ 517 signal6518_Data 0;
BA_ "GenSigAutoGenSnd" SG_ 517 signal6518_Data 0;
BA_ "GenSigAutoGenDsp" SG_ 517 signal6518_Data 0;
BA_ "signal142834" SG_ 640 signal6535_Data 640;
BA_ "NMH-WakeupAllowed" SG_ 640 signal6535_Data 0;
BA_ "NWM-WakeupAllowed" SG_ 640 signal6535_Data 0;
BA_ "GenSigSendType" SG_ 640 signal6535_Data 7;
BA_ "GenSigEnvVarType" SG_ 640 signal6535_Data 0;
BA_ "GenSigAutoGenSnd" SG_ 640 signal6535_Data 0;
BA_ "GenSigAutoGenDsp" SG_ 640 signal6535_Data 0;
BA_ "signal136198" SG_ 1137 signal6552_BZ 1137;
BA_ "GenSigTimeoutMsg_ecu13120" SG_ 1137 signal6552_BZ 1137;
BA_ "NMH-WakeupAllowed" SG_ 1137 signal6552_BZ 0;
BA_ "NWM-WakeupAllowed" SG_ 1137 signal6552_BZ 0;
BA_ "GenSigSendType" SG_ 1137 signal6552_BZ 7;
BA_ "GenSigEnvVarType" SG_ 1137 signal6552_BZ 0;
BA_ "GenSigAutoGenSnd" SG_ 1137 signal6552_BZ 1;
BA_ "GenSigAutoGenDsp" SG_ 1137 signal6552_BZ 1;
BA_ "signal136198" SG_ 1137 signal6569 1137;
BA_ "GenSigTimeoutMsg_ecu13120" SG_ 1137 signal6569 1137;
BA_ "NMH-WakeupAllowed" SG_ 1137 signal6569 0;
BA_ "NWM-WakeupAllowed" SG_ 1137 signal6569 0;
BA_ "GenSigSendType" SG_ 1137 signal6569 7;
BA_ "GenSigEnvVarType" SG_ 1137 signal6569 0;
BA_ "GenSigAutoGenSnd" SG_ 1137 signal6569 1;
BA_ "GenSigAutoGenDsp" SG_ 1137 signal6569 1;
BA_ "NMH-WakeupAllowed" SG_ 1137 signal6581 0;
BA_ "NWM-WakeupAllowed" SG_ 1137 signal6581 0;
BA_ "GenSigSendType" SG_ 1137 signal6581 7;
BA_ "GenSigEnvVarType" SG_ 1137 signal6581 0;
BA_ "GenSigAutoGenSnd" SG_ 1137 signal6581 1;
BA_ "GenSigAutoGenDsp" SG_ 1137 signal6581 1;
BA_ "NMH-WakeupAllowed" SG_ 1137 signal6591 0;
BA_ "NWM-WakeupAllowed" SG_ 1137 signal6591 0;
BA_ "GenSigSendType" SG_ 1137 signal6591 7;
BA_ "GenSigEnvVarType" SG_ 1137 signal6591 0;
BA_ "GenSigAutoGenSnd" SG_ 1137 signal6591 1;
BA_ "GenSigAutoGenDsp" SG_ 1137 signal6591 1;
BA_ "NMH-WakeupAllowed" SG_ 1137 signal6601 0;
BA_ "NWM-WakeupAllowed" SG_ 1137 signal6601 0;
BA_ "GenSigSendType" SG_ 1137 signal6601 7;
BA_ "GenSigEnvVarType" SG_ 1137 signal6601 0;
BA_ "GenSigAutoGenSnd" SG_ 1137 signal6601 1;
BA_ "GenSigAutoGenDsp" SG_ 1137 signal6601 1;
BA_ "NMH-WakeupAllowed" SG_ 1137 signal6611 0;
BA_ "NWM-WakeupAllowed" SG_ 1137 signal6611 0;
BA_ "GenSigSendType" SG_ 1137 signal6611 7;
BA_ "GenSigEnvVarType" SG_ 1137 signal6611 0;
BA_ "GenSigAutoGenSnd" SG_ 1137 signal6611 1;
BA_ "GenSigAutoGenDsp" SG_ 1137 signal6611 1;
BA_ "NMH-WakeupAllowed" SG_ 1137 signal6621 0;
BA_ "NWM-WakeupAllowed" SG_ 1137 signal6621 0;
BA_ "GenSigSendType" SG_ 1137 signal6621 7;
BA_ "GenSigEnvVarType" SG_ 1137 signal6621 0;
BA_ "GenSigAutoGenSnd" SG_ 1137 signal6621 1;
BA_ "GenSigAutoGenDsp" SG_ 1137 signal6621 1;
BA_ "NMH-WakeupAllowed" SG_ 1137 signal6631 0;
BA_ "NWM-WakeupAllowed" SG_ 1137 signal6631 0;
BA_ "GenSigSendType" SG_ 1137 signal6631 7;
BA_ "GenSigEnvVarType" SG_ 1137 signal6631 0;
BA_ "GenSigAutoGenSnd" SG_ 1137 signal6631 1;
BA_ "GenSigAutoGenDsp" SG_ 1137 signal6631 1;
BA_ "NMH-WakeupAllowed" SG_ 1137 signal6641 0;
BA_ "NWM-WakeupAllowed" SG_ 1137 signal6641 0;
BA_ "GenSigSendType" SG_ 1137 signal6641 7;
BA_ "GenSigEnvVarType" SG_ 1137 signal6641 0;
BA_ "GenSigAutoGenSnd" SG_ 1137 signal6641 1;
BA_ "GenSigAutoGenDsp" SG_ 1137 signal6641 1;
BA_ "NMH-WakeupAllowed" SG_ 1137 signal6651 0;
BA_ "NWM-WakeupAllowed" SG_ 1137 signal6651 0;
BA_ "GenSigSendType" SG_ 1137 signal6651 7;
BA_ "GenSigEnvVarType" SG_ 1137 signal6651 0;
BA_ "GenSigAutoGenSnd" SG_ 1137 signal6651 1;
BA_ "GenSigAutoGenDsp" SG_ 1137 signal6651 1;
BA_ "NMH-WakeupAllowed" SG_ 1137 signal6661 0;
BA_ "NWM-WakeupAllowed" SG_ 1137 signal6661 0;
BA_ "GenSigSendType" SG_ 1137 signal6661 7;
BA_ "GenSigEnvVarType" SG_ 1137 signal6661 0;
BA_ "GenSigAutoGenSnd" SG_ 1137 signal6661 1;
BA_ "GenSigAutoGenDsp" SG_ 1137 signal6661 1;
BA_ "NMH-WakeupAllowed" SG_ 1137 signal6671 0;
BA_ "NWM-WakeupAllowed" SG_ 1137 signal6671 0;
BA_ "GenSigSendType" SG_ 1137 signal6671 7;
BA_ "GenSigEnvVarType" SG_ 1137 signal6671 0;
BA_ "GenSigAutoGenSnd" SG_ 1137 signal6671 1;
BA_ "GenSigAutoGenDsp" SG_ 1137 signal6671 1;
BA_ "NMH-WakeupAllowed" SG_ 1137 signal6681 0;
BA_ "NWM-WakeupAllowed" SG_ 1137 signal6681 0;
BA_ "GenSigSendType" SG_ 1137 signal6681 7;
BA_ "GenSigEnvVarType" SG_ 1137 signal6681 0;
BA_ "GenSigAutoGenSnd" SG_ 1137 signal6681 1;
BA_ "GenSigAutoGenDsp" SG_ 1137 signal6681 1;
BA_ "NMH-WakeupAllowed" SG_ 1137 signal6691 0;
BA_ "NWM-WakeupAllowed" SG_ 1137 signal6691 0;
BA_ "GenSigSendType" SG_ 1137 signal6691 7;
BA_ "GenSigEnvVarType" SG_ 1137 signal6691 0;
BA_ "GenSigAutoGenSnd" SG_ 1137 signal6691 1;
BA_ "GenSigAutoGenDsp" SG_ 1137 signal6691 1;
BA_ "NMH-WakeupAllowed" SG_ 1137 signal6701 0;
BA_ "NWM-WakeupAllowed" SG_ 1137 signal6701 0;
BA_ "GenSigSendType" SG_ 1137 signal6701 7;
BA_ "GenSigEnvVarType" SG_ 1137 signal6701 0;
BA_ "GenSigAutoGenSnd" SG_ 1137 signal6701 1;
BA_ "GenSigAutoGenDsp" SG_ 1137 signal6701 1;
BA_ "NMH-WakeupAllowed" SG_ 1137 signal6711 0;
BA_ "NWM-WakeupAllowed" SG_ 1137 signal6711 0;
BA_ "GenSigSendType" SG_ 1137 signal6711 7;
BA_ "GenSigEnvVarType" SG_ 1137 signal6711 0;
BA_ "GenSigAutoGenSnd" SG_ 1137 signal6711 1;
BA_ "GenSigAutoGenDsp" SG_ 1137 signal6711 1;
BA_ "NMH-WakeupAllowed" SG_ 1137 signal6721 0;
BA_ "NWM-WakeupAllowed" SG_ 1137 signal6721 0;
BA_ "GenSigSendType" SG_ 1137 signal6721 7;
BA_ "GenSigEnvVarType" SG_ 1137 signal6721 0;
BA_ "GenSigAutoGenSnd" SG_ 1137 signal6721 1;
BA_ "GenSigAutoGenDsp" SG_ 1137 signal6721 1;
BA_ "NMH-WakeupAllowed" SG_ 1137 signal6731 0;
BA_ "NWM-WakeupAllowed" SG_ 1137 signal6731 0;
BA_ "GenSigSendType" SG_ 1137 signal6731 7;
BA_ "GenSigEnvVarType" SG_ 1137 signal6731 0;
BA_ "GenSigAutoGenSnd" SG_ 1137 signal6731 1;
BA_ "GenSigAutoGenDsp" SG_ 1137 signal6731 1;
BA_ "NMH-WakeupAllowed" SG_ 1137 signal6741 0;
BA_ "NWM-WakeupAllowed" SG_ 1137 signal6741 0;
BA_ "GenSigSendType" SG_ 1137 signal6741 7;
BA_ "GenSigEnvVarType" SG_ 1137 signal6741 0;
BA_ "GenSigAutoGenSnd" SG_ 1137 signal6741 1;
BA_ "GenSigAutoGenDsp" SG_ 1137 signal6741 1;
BA_ "NMH-WakeupAllowed" SG_ 1137 signal6751 0;
BA_ "NWM-WakeupAllowed" SG_ 1137 signal6751 0;
BA_ "GenSigSendType" SG_ 1137 signal6751 7;
BA_ "GenSigEnvVarType" SG_ 1137 signal6751 0;
BA_ "GenSigAutoGenSnd" SG_ 1137 signal6751 1;
BA_ "GenSigAutoGenDsp" SG_ 1137 signal6751 1;
BA_ "NMH-WakeupAllowed" SG_ 1137 signal6761 0;
BA_ "NWM-WakeupAllowed" SG_ 1137 signal6761 0;
BA_ "GenSigSendType" SG_ 1137 signal6761 7;
BA_ "GenSigEnvVarType" SG_ 1137 signal6761 0;
BA_ "GenSigAutoGenSnd" SG_ 1137 signal6761 1;
BA_ "GenSigAutoGenDsp" SG_ 1137 signal6761 1;
BA_ "NMH-WakeupAllowed" SG_ 1137 signal6771 0;
BA_ "NWM-WakeupAllowed" SG_ 1137 signal6771 0;
BA_ "GenSigSendType" SG_ 1137 signal6771 7;
BA_ "GenSigEnvVarType" SG_ 1137 signal6771 0;
BA_ "GenSigAutoGenSnd" SG_ 1137 signal6771 1;
BA_ "GenSigAutoGenDsp" SG_ 1137 signal6771 1;
BA_ "NMH-WakeupAllowed" SG_ 1137 signal6781 0;
BA_ "NWM-WakeupAllowed" SG_ 1137 signal6781 0;
BA_ "GenSigSendType" SG_ 1137 signal6781 7;
BA_ "GenSigEnvVarType" SG_ 1137 signal6781 0;
BA_ "GenSigAutoGenSnd" SG_ 1137 signal6781 1;
BA_ "GenSigAutoGenDsp" SG_ 1137 signal6781 1;
BA_ "NMH-WakeupAllowed" SG_ 1137 signal6791 0;
BA_ "NWM-WakeupAllowed" SG_ 1137 signal6791 0;
BA_ "GenSigSendType" SG_ 1137 signal6791 7;
BA_ "GenSigEnvVarType" SG_ 1137 signal6791 0;
BA_ "GenSigAutoGenSnd" SG_ 1137 signal6791 1;
BA_ "GenSigAutoGenDsp" SG_ 1137 signal6791 1;
BA_ "NMH-WakeupAllowed" SG_ 1137 signal6801 0;
BA_ "NWM-WakeupAllowed" SG_ 1137 signal6801 0;
BA_ "GenSigSendType" SG_ 1137 signal6801 7;
BA_ "GenSigEnvVarType" SG_ 1137 signal6801 0;
BA_ "GenSigAutoGenSnd" SG_ 1137 signal6801 1;
BA_ "GenSigAutoGenDsp" SG_ 1137 signal6801 1;
BA_ "NMH-WakeupAllowed" SG_ 1137 signal6811 0;
BA_ "NWM-WakeupAllowed" SG_ 1137 signal6811 0;
BA_ "GenSigSendType" SG_ 1137 signal6811 7;
BA_ "GenSigEnvVarType" SG_ 1137 signal6811 0;
BA_ "GenSigAutoGenSnd" SG_ 1137 signal6811 1;
BA_ "GenSigAutoGenDsp" SG_ 1137 signal6811 1;
BA_ "NMH-WakeupAllowed" SG_ 1137 signal6821 0;
BA_ "NWM-WakeupAllowed" SG_ 1137 signal6821 0;
BA_ "GenSigSendType" SG_ 1137 signal6821 7;
BA_ "GenSigEnvVarType" SG_ 1137 signal6821 0;
BA_ "GenSigAutoGenSnd" SG_ 1137 signal6821 1;
BA_ "GenSigAutoGenDsp" SG_ 1137 signal6821 1;
BA_ "NMH-WakeupAllowed" SG_ 1137 signal6831 0;
BA_ "NWM-WakeupAllowed" SG_ 1137 signal6831 0;
BA_ "GenSigSendType" SG_ 1137 signal6831 7;
BA_ "GenSigEnvVarType" SG_ 1137 signal6831 0;
BA_ "GenSigAutoGenSnd" SG_ 1137 signal6831 1;
BA_ "GenSigAutoGenDsp" SG_ 1137 signal6831 1;
BA_ "NMH-WakeupAllowed" SG_ 1137 signal6841 0;
BA_ "NWM-WakeupAllowed" SG_ 1137 signal6841 0;
BA_ "GenSigSendType" SG_ 1137 signal6841 7;
BA_ "GenSigEnvVarType" SG_ 1137 signal6841 0;
BA_ "GenSigAutoGenSnd" SG_ 1137 signal6841 1;
BA_ "GenSigAutoGenDsp" SG_ 1137 signal6841 1;
BA_ "NMH-WakeupAllowed" SG_ 1137 signal6851 0;
BA_ "NWM-WakeupAllowed" SG_ 1137 signal6851 0;
BA_ "GenSigSendType" SG_ 1137 signal6851 7;
BA_ "GenSigEnvVarType" SG_ 1137 signal6851 0;
BA_ "GenSigAutoGenSnd" SG_ 1137 signal6851 1;
BA_ "GenSigAutoGenDsp" SG_ 1137 signal6851 1;
BA_ "signal136198" SG_ 1137 signal6861 1137;
BA_ "GenSigTimeoutMsg_ecu13120" SG_ 1137 signal6861 1137;
BA_ "NMH-WakeupAllowed" SG_ 1137 signal6861 0;
BA_ "NWM-WakeupAllowed" SG_ 1137 signal6861 0;
BA_ "GenSigSendType" SG_ 1137 signal6861 7;
BA_ "GenSigEnvVarType" SG_ 1137 signal6861 0;
BA_ "GenSigAutoGenSnd" SG_ 1137 signal6861 1;
BA_ "GenSigAutoGenDsp" SG_ 1137 signal6861 1;
BA_ "NMH-WakeupAllowed" SG_ 1137 signal6873 0;
BA_ "NWM-WakeupAllowed" SG_ 1137 signal6873 0;
BA_ "GenSigSendType" SG_ 1137 signal6873 7;
BA_ "GenSigEnvVarType" SG_ 1137 signal6873 0;
BA_ "GenSigAutoGenSnd" SG_ 1137 signal6873 1;
BA_ "GenSigAutoGenDsp" SG_ 1137 signal6873 1;
BA_ "NMH-WakeupAllowed" SG_ 1137 signal6883 0;
BA_ "NWM-WakeupAllowed" SG_ 1137 signal6883 0;
BA_ "GenSigSendType" SG_ 1137 signal6883 7;
BA_ "GenSigEnvVarType" SG_ 1137 signal6883 0;
BA_ "GenSigAutoGenSnd" SG_ 1137 signal6883 1;
BA_ "GenSigAutoGenDsp" SG_ 1137 signal6883 1;
BA_ "signal136198" SG_ 1137 signal6893 1137;
BA_ "GenSigTimeoutMsg_ecu13120" SG_ 1137 signal6893 1137;
BA_ "NMH-WakeupAllowed" SG_ 1137 signal6893 0;
BA_ "NWM-WakeupAllowed" SG_ 1137 signal6893 0;
BA_ "GenSigSendType" SG_ 1137 signal6893 7;
BA_ "GenSigEnvVarType" SG_ 1137 signal6893 0;
BA_ "GenSigAutoGenSnd" SG_ 1137 signal6893 1;
BA_ "GenSigAutoGenDsp" SG_ 1137 signal6893 1;
BA_ "signal136198" SG_ 1137 signal6905 1137;
BA_ "GenSigTimeoutMsg_ecu13120" SG_ 1137 signal6905 1137;
BA_ "NMH-WakeupAllowed" SG_ 1137 signal6905 0;
BA_ "NWM-WakeupAllowed" SG_ 1137 signal6905 0;
BA_ "GenSigSendType" SG_ 1137 signal6905 7;
BA_ "GenSigEnvVarType" SG_ 1137 signal6905 0;
BA_ "GenSigAutoGenSnd" SG_ 1137 signal6905 1;
BA_ "GenSigAutoGenDsp" SG_ 1137 signal6905 1;
BA_ "signal136198" SG_ 267 signal6918_CHK 267;
BA_ "signal133356" SG_ 267 signal6918_CHK 267;
BA_ "GenSigTimeoutMsg_ecu13120" SG_ 267 signal6918_CHK 267;
BA_ "GenSigTimeoutMsg_ecu11765" SG_ 267 signal6918_CHK 267;
BA_ "signal131970" SG_ 267 signal6918_CHK 267;
BA_ "signal131977" SG_ 267 signal6918_CHK 267;
BA_ "GenSigTimeoutMsg_ecu13186" SG_ 267 signal6918_CHK 267;
BA_ "NMH-WakeupAllowed" SG_ 267 signal6918_CHK 0;
BA_ "NWM-WakeupAllowed" SG_ 267 signal6918_CHK 0;
BA_ "GenSigSendType" SG_ 267 signal6918_CHK 7;
BA_ "GenSigEnvVarType" SG_ 267 signal6918_CHK 0;
BA_ "GenSigAutoGenSnd" SG_ 267 signal6918_CHK 1;
BA_ "GenSigAutoGenDsp" SG_ 267 signal6918_CHK 1;
BA_ "signal136198" SG_ 267 signal6918_BZ 267;
BA_ "signal133356" SG_ 267 signal6918_BZ 267;
BA_ "GenSigTimeoutMsg_ecu13120" SG_ 267 signal6918_BZ 267;
BA_ "GenSigTimeoutMsg_ecu11765" SG_ 267 signal6918_BZ 267;
BA_ "signal131970" SG_ 267 signal6918_BZ 267;
BA_ "signal131977" SG_ 267 signal6918_BZ 267;
BA_ "GenSigTimeoutMsg_ecu13186" SG_ 267 signal6918_BZ 267;
BA_ "NMH-WakeupAllowed" SG_ 267 signal6918_BZ 0;
BA_ "NWM-WakeupAllowed" SG_ 267 signal6918_BZ 0;
BA_ "GenSigSendType" SG_ 267 signal6918_BZ 7;
BA_ "GenSigEnvVarType" SG_ 267 signal6918_BZ 0;
BA_ "GenSigAutoGenSnd" SG_ 267 signal6918_BZ 1;
BA_ "GenSigAutoGenDsp" SG_ 267 signal6918_BZ 1;
BA_ "signal136198" SG_ 267 signal6957 267;
BA_ "signal133356" SG_ 267 signal6957 267;
BA_ "GenSigTimeoutMsg_ecu13120" SG_ 267 signal6957 267;
BA_ "GenSigTimeoutMsg_ecu13186" SG_ 267 signal6957 267;
BA_ "NMH-WakeupAllowed" SG_ 267 signal6957 0;
BA_ "NWM-WakeupAllowed" SG_ 267 signal6957 0;
BA_ "GenSigSendType" SG_ 267 signal6957 7;
BA_ "GenSigEnvVarType" SG_ 267 signal6957 0;
BA_ "GenSigAutoGenSnd" SG_ 267 signal6957 1;
BA_ "GenSigAutoGenDsp" SG_ 267 signal6957 1;
BA_ "signal136198" SG_ 267 signal6971 267;
BA_ "signal133356" SG_ 267 signal6971 267;
BA_ "GenSigTimeoutMsg_ecu13120" SG_ 267 signal6971 267;
BA_ "GenSigTimeoutMsg_ecu13186" SG_ 267 signal6971 267;
BA_ "NMH-WakeupAllowed" SG_ 267 signal6971 0;
BA_ "NWM-WakeupAllowed" SG_ 267 signal6971 0;
BA_ "GenSigSendType" SG_ 267 signal6971 7;
BA_ "GenSigEnvVarType" SG_ 267 signal6971 0;
BA_ "GenSigAutoGenSnd" SG_ 267 signal6971 1;
BA_ "GenSigAutoGenDsp" SG_ 267 signal6971 1;
BA_ "signal136198" SG_ 267 signal6985 267;
BA_ "signal133356" SG_ 267 signal6985 267;
BA_ "GenSigTimeoutMsg_ecu13120" SG_ 267 signal6985 267;
BA_ "GenSigTimeoutMsg_ecu13186" SG_ 267 signal6985 267;
BA_ "NMH-WakeupAllowed" SG_ 267 signal6985 0;
BA_ "NWM-WakeupAllowed" SG_ 267 signal6985 0;
BA_ "GenSigSendType" SG_ 267 signal6985 7;
BA_ "GenSigEnvVarType" SG_ 267 signal6985 0;
BA_ "GenSigAutoGenSnd" SG_ 267 signal6985 1;
BA_ "GenSigAutoGenDsp" SG_ 267 signal6985 1;
BA_ "signal136198" SG_ 267 signal6999 267;
BA_ "signal133356" SG_ 267 signal6999 267;
BA_ "GenSigTimeoutMsg_ecu13120" SG_ 267 signal6999 267;
BA_ "GenSigTimeoutMsg_ecu13186" SG_ 267 signal6999 267;
BA_ "NMH-WakeupAllowed" SG_ 267 signal6999 0;
BA_ "NWM-WakeupAllowed" SG_ 267 signal6999 0;
BA_ "GenSigSendType" SG_ 267 signal6999 7;
BA_ "GenSigEnvVarType" SG_ 267 signal6999 0;
BA_ "GenSigAutoGenSnd" SG_ 267 signal6999 1;
BA_ "GenSigAutoGenDsp" SG_ 267 signal6999 1;
BA_ "signal136198" SG_ 267 signal7013 267;
BA_ "signal133356" SG_ 267 signal7013 267;
BA_ "GenSigTimeoutMsg_ecu13120" SG_ 267 signal7013 267;
BA_ "GenSigTimeoutMsg_ecu13186" SG_ 267 signal7013 267;
BA_ "NMH-WakeupAllowed" SG_ 267 signal7013 0;
BA_ "NWM-WakeupAllowed" SG_ 267 signal7013 0;
BA_ "GenSigSendType" SG_ 267 signal7013 7;
BA_ "GenSigEnvVarType" SG_ 267 signal7013 0;
BA_ "GenSigAutoGenSnd" SG_ 267 signal7013 1;
BA_ "GenSigAutoGenDsp" SG_ 267 signal7013 1;
BA_ "signal136198" SG_ 267 signal7027 267;
BA_ "signal133356" SG_ 267 signal7027 267;
BA_ "GenSigTimeoutMsg_ecu13120" SG_ 267 signal7027 267;
BA_ "GenSigTimeoutMsg_ecu13186" SG_ 267 signal7027 267;
BA_ "NMH-WakeupAllowed" SG_ 267 signal7027 0;
BA_ "NWM-WakeupAllowed" SG_ 267 signal7027 0;
BA_ "GenSigSendType" SG_ 267 signal7027 7;
BA_ "GenSigEnvVarType" SG_ 267 signal7027 0;
BA_ "GenSigAutoGenSnd" SG_ 267 signal7027 1;
BA_ "GenSigAutoGenDsp" SG_ 267 signal7027 1;
BA_ "signal136198" SG_ 267 signal7041 267;
BA_ "signal133356" SG_ 267 signal7041 267;
BA_ "GenSigTimeoutMsg_ecu13120" SG_ 267 signal7041 267;
BA_ "GenSigTimeoutMsg_ecu13186" SG_ 267 signal7041 267;
BA_ "NMH-WakeupAllowed" SG_ 267 signal7041 0;
BA_ "NWM-WakeupAllowed" SG_ 267 signal7041 0;
BA_ "GenSigSendType" SG_ 267 signal7041 7;
BA_ "GenSigEnvVarType" SG_ 267 signal7041 0;
BA_ "GenSigAutoGenSnd" SG_ 267 signal7041 1;
BA_ "GenSigAutoGenDsp" SG_ 267 signal7041 1;
BA_ "signal136198" SG_ 267 signal7055 267;
BA_ "signal133356" SG_ 267 signal7055 267;
BA_ "GenSigTimeoutMsg_ecu13120" SG_ 267 signal7055 267;
BA_ "GenSigTimeoutMsg_ecu13186" SG_ 267 signal7055 267;
BA_ "NMH-WakeupAllowed" SG_ 267 signal7055 0;
BA_ "NWM-WakeupAllowed" SG_ 267 signal7055 0;
BA_ "GenSigSendType" SG_ 267 signal7055 7;
BA_ "GenSigEnvVarType" SG_ 267 signal7055 0;
BA_ "GenSigAutoGenSnd" SG_ 267 signal7055 1;
BA_ "GenSigAutoGenDsp" SG_ 267 signal7055 1;
BA_ "GenSigTimeoutMsg_ecu13186" SG_ 267 signal7069 267;
BA_ "NMH-WakeupAllowed" SG_ 267 signal7069 0;
BA_ "NWM-WakeupAllowed" SG_ 267 signal7069 0;
BA_ "GenSigSendType" SG_ 267 signal7069 7;
BA_ "GenSigEnvVarType" SG_ 267 signal7069 0;
BA_ "GenSigAutoGenSnd" SG_ 267 signal7069 1;
BA_ "GenSigAutoGenDsp" SG_ 267 signal7069 1;
BA_ "GenSigTimeoutMsg_ecu11765" SG_ 267 signal7080 267;
BA_ "signal131970" SG_ 267 signal7080 267;
BA_ "signal131977" SG_ 267 signal7080 267;
BA_ "GenSigTimeoutMsg_ecu13186" SG_ 267 signal7080 267;
BA_ "NMH-WakeupAllowed" SG_ 267 signal7080 0;
BA_ "NWM-WakeupAllowed" SG_ 267 signal7080 0;
BA_ "GenSigSendType" SG_ 267 signal7080 7;
BA_ "GenSigEnvVarType" SG_ 267 signal7080 0;
BA_ "GenSigAutoGenSnd" SG_ 267 signal7080 1;
BA_ "GenSigAutoGenDsp" SG_ 267 signal7080 1;
BA_ "GenSigTimeoutMsg_ecu11765" SG_ 267 signal7094 267;
BA_ "signal131970" SG_ 267 signal7094 267;
BA_ "signal131977" SG_ 267 signal7094 267;
BA_ "GenSigTimeoutMsg_ecu13186" SG_ 267 signal7094 267;
BA_ "NMH-WakeupAllowed" SG_ 267 signal7094 0;
BA_ "NWM-WakeupAllowed" SG_ 267 signal7094 0;
BA_ "GenSigSendType" SG_ 267 signal7094 7;
BA_ "GenSigEnvVarType" SG_ 267 signal7094 0;
BA_ "GenSigAutoGenSnd" SG_ 267 signal7094 1;
BA_ "GenSigAutoGenDsp" SG_ 267 signal7094 1;
BA_ "signal131970" SG_ 267 signal7108 267;
BA_ "signal131977" SG_ 267 signal7108 267;
BA_ "GenSigTimeoutMsg_ecu13186" SG_ 267 signal7108 267;
BA_ "NMH-WakeupAllowed" SG_ 267 signal7108 0;
BA_ "NWM-WakeupAllowed" SG_ 267 signal7108 0;
BA_ "GenSigSendType" SG_ 267 signal7108 7;
BA_ "GenSigEnvVarType" SG_ 267 signal7108 0;
BA_ "GenSigAutoGenSnd" SG_ 267 signal7108 1;
BA_ "GenSigAutoGenDsp" SG_ 267 signal7108 1;
BA_ "signal136198" SG_ 267 signal7121 267;
BA_ "signal133356" SG_ 267 signal7121 267;
BA_ "GenSigTimeoutMsg_ecu13120" SG_ 267 signal7121 267;
BA_ "GenSigTimeoutMsg_ecu13186" SG_ 267 signal7121 267;
BA_ "NMH-WakeupAllowed" SG_ 267 signal7121 0;
BA_ "NWM-WakeupAllowed" SG_ 267 signal7121 0;
BA_ "GenSigSendType" SG_ 267 signal7121 7;
BA_ "GenSigEnvVarType" SG_ 267 signal7121 0;
BA_ "GenSigAutoGenSnd" SG_ 267 signal7121 1;
BA_ "GenSigAutoGenDsp" SG_ 267 signal7121 1;
BA_ "signal136198" SG_ 267 signal7135 267;
BA_ "signal133356" SG_ 267 signal7135 267;
BA_ "GenSigTimeoutMsg_ecu13120" SG_ 267 signal7135 267;
BA_ "GenSigTimeoutMsg_ecu13186" SG_ 267 signal7135 267;
BA_ "NMH-WakeupAllowed" SG_ 267 signal7135 0;
BA_ "NWM-WakeupAllowed" SG_ 267 signal7135 0;
BA_ "GenSigSendType" SG_ 267 signal7135 7;
BA_ "GenSigEnvVarType" SG_ 267 signal7135 0;
BA_ "GenSigAutoGenSnd" SG_ 267 signal7135 1;
BA_ "GenSigAutoGenDsp" SG_ 267 signal7135 1;
BA_ "signal142820" SG_ 134 signal7150_CHK 134;
BA_ "GenSigTimeoutMsg_ecu11949" SG_ 134 signal7150_CHK 134;
BA_ "signal136198" SG_ 134 signal7150_CHK 134;
BA_ "signal133356" SG_ 134 signal7150_CHK 134;
BA_ "GenSigTimeoutMsg_ecu13120" SG_ 134 signal7150_CHK 134;
BA_ "GenSigTimeoutMsg_ecu11765" SG_ 134 signal7150_CHK 134;
BA_ "signal131970" SG_ 134 signal7150_CHK 134;
BA_ "signal131977" SG_ 134 signal7150_CHK 134;
BA_ "GenSigTimeoutMsg_ecu13186" SG_ 134 signal7150_CHK 134;
BA_ "GenSigTimeoutMsg_ecu9211" SG_ 134 signal7150_CHK 134;
BA_ "NMH-WakeupAllowed" SG_ 134 signal7150_CHK 0;
BA_ "NWM-WakeupAllowed" SG_ 134 signal7150_CHK 0;
BA_ "GenSigSendType" SG_ 134 signal7150_CHK 7;
BA_ "GenSigEnvVarType" SG_ 134 signal7150_CHK 0;
BA_ "GenSigAutoGenSnd" SG_ 134 signal7150_CHK 1;
BA_ "GenSigAutoGenDsp" SG_ 134 signal7150_CHK 1;
BA_ "signal142820" SG_ 134 signal7150_BZ 134;
BA_ "GenSigTimeoutMsg_ecu11949" SG_ 134 signal7150_BZ 134;
BA_ "signal136198" SG_ 134 signal7150_BZ 134;
BA_ "signal133356" SG_ 134 signal7150_BZ 134;
BA_ "GenSigTimeoutMsg_ecu13120" SG_ 134 signal7150_BZ 134;
BA_ "GenSigTimeoutMsg_ecu11765" SG_ 134 signal7150_BZ 134;
BA_ "signal131970" SG_ 134 signal7150_BZ 134;
BA_ "signal131977" SG_ 134 signal7150_BZ 134;
BA_ "GenSigTimeoutMsg_ecu13186" SG_ 134 signal7150_BZ 134;
BA_ "GenSigTimeoutMsg_ecu9211" SG_ 134 signal7150_BZ 134;
BA_ "NMH-WakeupAllowed" SG_ 134 signal7150_BZ 0;
BA_ "NWM-WakeupAllowed" SG_ 134 signal7150_BZ 0;
BA_ "GenSigSendType" SG_ 134 signal7150_BZ 7;
BA_ "GenSigEnvVarType" SG_ 134 signal7150_BZ 0;
BA_ "GenSigAutoGenSnd" SG_ 134 signal7150_BZ 1;
BA_ "GenSigAutoGenDsp" SG_ 134 signal7150_BZ 1;
BA_ "signal142820" SG_ 134 signal7195 134;
BA_ "GenSigTimeoutMsg_ecu11949" SG_ 134 signal7195 134;
BA_ "signal136198" SG_ 134 signal7195 134;
BA_ "signal133356" SG_ 134 signal7195 134;
BA_ "GenSigTimeoutMsg_ecu13120" SG_ 134 signal7195 134;
BA_ "signal131970" SG_ 134 signal7195 134;
BA_ "signal131977" SG_ 134 signal7195 134;
BA_ "GenSigTimeoutMsg_ecu13186" SG_ 134 signal7195 134;
BA_ "GenSigTimeoutMsg_ecu9211" SG_ 134 signal7195 134;
BA_ "NMH-WakeupAllowed" SG_ 134 signal7195 0;
BA_ "NWM-WakeupAllowed" SG_ 134 signal7195 0;
BA_ "GenSigSendType" SG_ 134 signal7195 7;
BA_ "GenSigEnvVarType" SG_ 134 signal7195 0;
BA_ "GenSigAutoGenSnd" SG_ 134 signal7195 1;
BA_ "GenSigAutoGenDsp" SG_ 134 signal7195 1;
BA_ "signal142820" SG_ 134 signal7214 134;
BA_ "GenSigTimeoutMsg_ecu11949" SG_ 134 signal7214 134;
BA_ "GenSigTimeoutMsg_ecu13186" SG_ 134 signal7214 134;
BA_ "GenSigTimeoutMsg_ecu9211" SG_ 134 signal7214 134;
BA_ "NMH-WakeupAllowed" SG_ 134 signal7214 0;
BA_ "NWM-WakeupAllowed" SG_ 134 signal7214 0;
BA_ "GenSigSendType" SG_ 134 signal7214 7;
BA_ "GenSigEnvVarType" SG_ 134 signal7214 0;
BA_ "GenSigAutoGenSnd" SG_ 134 signal7214 1;
BA_ "GenSigAutoGenDsp" SG_ 134 signal7214 1;
BA_ "signal142820" SG_ 134 signal7228 134;
BA_ "GenSigTimeoutMsg_ecu11949" SG_ 134 signal7228 134;
BA_ "signal136198" SG_ 134 signal7228 134;
BA_ "signal133356" SG_ 134 signal7228 134;
BA_ "GenSigTimeoutMsg_ecu13120" SG_ 134 signal7228 134;
BA_ "signal131970" SG_ 134 signal7228 134;
BA_ "signal131977" SG_ 134 signal7228 134;
BA_ "GenSigTimeoutMsg_ecu13186" SG_ 134 signal7228 134;
BA_ "GenSigTimeoutMsg_ecu9211" SG_ 134 signal7228 134;
BA_ "NMH-WakeupAllowed" SG_ 134 signal7228 0;
BA_ "NWM-WakeupAllowed" SG_ 134 signal7228 0;
BA_ "GenSigStartValue" SG_ 134 signal7228 1;
BA_ "GenSigSendType" SG_ 134 signal7228 7;
BA_ "GenSigEnvVarType" SG_ 134 signal7228 0;
BA_ "GenSigAutoGenSnd" SG_ 134 signal7228 1;
BA_ "GenSigAutoGenDsp" SG_ 134 signal7228 1;
BA_ "signal142820" SG_ 134 signal7247 134;
BA_ "GenSigTimeoutMsg_ecu11949" SG_ 134 signal7247 134;
BA_ "signal136198" SG_ 134 signal7247 134;
BA_ "signal133356" SG_ 134 signal7247 134;
BA_ "GenSigTimeoutMsg_ecu13120" SG_ 134 signal7247 134;
BA_ "GenSigTimeoutMsg_ecu11765" SG_ 134 signal7247 134;
BA_ "signal131970" SG_ 134 signal7247 134;
BA_ "signal131977" SG_ 134 signal7247 134;
BA_ "GenSigTimeoutMsg_ecu13186" SG_ 134 signal7247 134;
BA_ "GenSigTimeoutMsg_ecu9211" SG_ 134 signal7247 134;
BA_ "NMH-WakeupAllowed" SG_ 134 signal7247 0;
BA_ "NWM-WakeupAllowed" SG_ 134 signal7247 0;
BA_ "GenSigStartValue" SG_ 134 signal7247 8190;
BA_ "GenSigSendType" SG_ 134 signal7247 7;
BA_ "GenSigEnvVarType" SG_ 134 signal7247 1;
BA_ "GenSigAutoGenSnd" SG_ 134 signal7247 1;
BA_ "GenSigAutoGenDsp" SG_ 134 signal7247 1;
BA_ "signal142820" SG_ 134 signal7267 134;
BA_ "GenSigTimeoutMsg_ecu11949" SG_ 134 signal7267 134;
BA_ "signal136198" SG_ 134 signal7267 134;
BA_ "signal133356" SG_ 134 signal7267 134;
BA_ "GenSigTimeoutMsg_ecu13120" SG_ 134 signal7267 134;
BA_ "signal131970" SG_ 134 signal7267 134;
BA_ "signal131977" SG_ 134 signal7267 134;
BA_ "GenSigTimeoutMsg_ecu13186" SG_ 134 signal7267 134;
BA_ "GenSigTimeoutMsg_ecu9211" SG_ 134 signal7267 134;
BA_ "NMH-WakeupAllowed" SG_ 134 signal7267 0;
BA_ "NWM-WakeupAllowed" SG_ 134 signal7267 0;
BA_ "GenSigSendType" SG_ 134 signal7267 7;
BA_ "GenSigEnvVarType" SG_ 134 signal7267 0;
BA_ "GenSigAutoGenSnd" SG_ 134 signal7267 1;
BA_ "GenSigAutoGenDsp" SG_ 134 signal7267 1;
BA_ "GenSigTimeoutMsg_ecu11949" SG_ 134 signal7286 134;
BA_ "GenSigTimeoutMsg_ecu13186" SG_ 134 signal7286 134;
BA_ "GenSigTimeoutMsg_ecu9211" SG_ 134 signal7286 134;
BA_ "NMH-WakeupAllowed" SG_ 134 signal7286 0;
BA_ "NWM-WakeupAllowed" SG_ 134 signal7286 0;
BA_ "GenSigSendType" SG_ 134 signal7286 7;
BA_ "GenSigEnvVarType" SG_ 134 signal7286 0;
BA_ "GenSigAutoGenSnd" SG_ 134 signal7286 1;
BA_ "GenSigAutoGenDsp" SG_ 134 signal7286 1;
BA_ "GenSigTimeoutMsg_ecu11949" SG_ 134 signal7299 134;
BA_ "GenSigTimeoutMsg_ecu13186" SG_ 134 signal7299 134;
BA_ "GenSigTimeoutMsg_ecu9211" SG_ 134 signal7299 134;
BA_ "NMH-WakeupAllowed" SG_ 134 signal7299 0;
BA_ "NWM-WakeupAllowed" SG_ 134 signal7299 0;
BA_ "GenSigStartValue" SG_ 134 signal7299 510;
BA_ "GenSigSendType" SG_ 134 signal7299 7;
BA_ "GenSigEnvVarType" SG_ 134 signal7299 0;
BA_ "GenSigAutoGenSnd" SG_ 134 signal7299 1;
BA_ "GenSigAutoGenDsp" SG_ 134 signal7299 1;
BA_ "signal142820" SG_ 134 signal7312 134;
BA_ "GenSigTimeoutMsg_ecu11949" SG_ 134 signal7312 134;
BA_ "GenSigTimeoutMsg_ecu13186" SG_ 134 signal7312 134;
BA_ "GenSigTimeoutMsg_ecu9211" SG_ 134 signal7312 134;
BA_ "NMH-WakeupAllowed" SG_ 134 signal7312 0;
BA_ "NWM-WakeupAllowed" SG_ 134 signal7312 0;
BA_ "GenSigSendType" SG_ 134 signal7312 7;
BA_ "GenSigEnvVarType" SG_ 134 signal7312 0;
BA_ "GenSigAutoGenSnd" SG_ 134 signal7312 1;
BA_ "GenSigAutoGenDsp" SG_ 134 signal7312 1;
BA_ "signal142820" SG_ 134 signal7150_CRC 134;
BA_ "GenSigTimeoutMsg_ecu11949" SG_ 134 signal7150_CRC 134;
BA_ "GenSigTimeoutMsg_ecu13186" SG_ 134 signal7150_CRC 134;
BA_ "GenSigTimeoutMsg_ecu9211" SG_ 134 signal7150_CRC 134;
BA_ "NMH-WakeupAllowed" SG_ 134 signal7150_CRC 0;
BA_ "NWM-WakeupAllowed" SG_ 134 signal7150_CRC 0;
BA_ "GenSigSendType" SG_ 134 signal7150_CRC 7;
BA_ "GenSigEnvVarType" SG_ 134 signal7150_CRC 0;
BA_ "GenSigAutoGenSnd" SG_ 134 signal7150_CRC 1;
BA_ "GenSigAutoGenDsp" SG_ 134 signal7150_CRC 1;
BA_ "GenSigTimeoutMsg_ecu11765" SG_ 128 signal7341_CHK 128;
BA_ "signal131970" SG_ 128 signal7341_CHK 128;
BA_ "signal131977" SG_ 128 signal7341_CHK 128;
BA_ "GenSigTimeoutMsg_ecu13186" SG_ 128 signal7341_CHK 128;
BA_ "GenSigTimeoutMsg_ecu12594" SG_ 128 signal7341_CHK 128;
BA_ "NMH-WakeupAllowed" SG_ 128 signal7341_CHK 0;
BA_ "NWM-WakeupAllowed" SG_ 128 signal7341_CHK 0;
BA_ "GenSigSendType" SG_ 128 signal7341_CHK 7;
BA_ "GenSigEnvVarType" SG_ 128 signal7341_CHK 0;
BA_ "GenSigAutoGenSnd" SG_ 128 signal7341_CHK 1;
BA_ "GenSigAutoGenDsp" SG_ 128 signal7341_CHK 1;
BA_ "GenSigTimeoutMsg_ecu11765" SG_ 128 signal7341_BZ 128;
BA_ "signal131970" SG_ 128 signal7341_BZ 128;
BA_ "signal131977" SG_ 128 signal7341_BZ 128;
BA_ "GenSigTimeoutMsg_ecu13186" SG_ 128 signal7341_BZ 128;
BA_ "GenSigTimeoutMsg_ecu12594" SG_ 128 signal7341_BZ 128;
BA_ "NMH-WakeupAllowed" SG_ 128 signal7341_BZ 0;
BA_ "NWM-WakeupAllowed" SG_ 128 signal7341_BZ 0;
BA_ "GenSigSendType" SG_ 128 signal7341_BZ 7;
BA_ "GenSigEnvVarType" SG_ 128 signal7341_BZ 0;
BA_ "GenSigAutoGenSnd" SG_ 128 signal7341_BZ 1;
BA_ "GenSigAutoGenDsp" SG_ 128 signal7341_BZ 1;
BA_ "GenSigTimeoutMsg_ecu11765" SG_ 128 signal7376 128;
BA_ "signal131970" SG_ 128 signal7376 128;
BA_ "signal131977" SG_ 128 signal7376 128;
BA_ "GenSigTimeoutMsg_ecu13186" SG_ 128 signal7376 128;
BA_ "GenSigTimeoutMsg_ecu12594" SG_ 128 signal7376 128;
BA_ "NMH-WakeupAllowed" SG_ 128 signal7376 0;
BA_ "NWM-WakeupAllowed" SG_ 128 signal7376 0;
BA_ "GenSigStartValue" SG_ 128 signal7376 1022;
BA_ "GenSigSendType" SG_ 128 signal7376 7;
BA_ "GenSigEnvVarType" SG_ 128 signal7376 0;
BA_ "GenSigAutoGenSnd" SG_ 128 signal7376 1;
BA_ "GenSigAutoGenDsp" SG_ 128 signal7376 1;
BA_ "GenSigTimeoutMsg_ecu11765" SG_ 128 signal7391 128;
BA_ "signal131970" SG_ 128 signal7391 128;
BA_ "signal131977" SG_ 128 signal7391 128;
BA_ "GenSigTimeoutMsg_ecu13186" SG_ 128 signal7391 128;
BA_ "GenSigTimeoutMsg_ecu12594" SG_ 128 signal7391 128;
BA_ "NMH-WakeupAllowed" SG_ 128 signal7391 0;
BA_ "NWM-WakeupAllowed" SG_ 128 signal7391 0;
BA_ "GenSigStartValue" SG_ 128 signal7391 1022;
BA_ "GenSigSendType" SG_ 128 signal7391 7;
BA_ "GenSigEnvVarType" SG_ 128 signal7391 0;
BA_ "GenSigAutoGenSnd" SG_ 128 signal7391 1;
BA_ "GenSigAutoGenDsp" SG_ 128 signal7391 1;
BA_ "GenSigTimeoutMsg_ecu11765" SG_ 128 signal7406 128;
BA_ "signal131970" SG_ 128 signal7406 128;
BA_ "signal131977" SG_ 128 signal7406 128;
BA_ "GenSigTimeoutMsg_ecu13186" SG_ 128 signal7406 128;
BA_ "GenSigTimeoutMsg_ecu12594" SG_ 128 signal7406 128;
BA_ "NMH-WakeupAllowed" SG_ 128 signal7406 0;
BA_ "NWM-WakeupAllowed" SG_ 128 signal7406 0;
BA_ "GenSigStartValue" SG_ 128 signal7406 1022;
BA_ "GenSigSendType" SG_ 128 signal7406 7;
BA_ "GenSigEnvVarType" SG_ 128 signal7406 0;
BA_ "GenSigAutoGenSnd" SG_ 128 signal7406 1;
BA_ "GenSigAutoGenDsp" SG_ 128 signal7406 1;
BA_ "GenSigTimeoutMsg_ecu11765" SG_ 128 signal7421 128;
BA_ "signal131970" SG_ 128 signal7421 128;
BA_ "signal131977" SG_ 128 signal7421 128;
BA_ "GenSigTimeoutMsg_ecu13186" SG_ 128 signal7421 128;
BA_ "NMH-WakeupAllowed" SG_ 128 signal7421 0;
BA_ "NWM-WakeupAllowed" SG_ 128 signal7421 0;
BA_ "GenSigStartValue" SG_ 128 signal7421 1022;
BA_ "GenSigSendType" SG_ 128 signal7421 7;
BA_ "GenSigEnvVarType" SG_ 128 signal7421 0;
BA_ "GenSigAutoGenSnd" SG_ 128 signal7421 1;
BA_ "GenSigAutoGenDsp" SG_ 128 signal7421 1;
BA_ "GenSigTimeoutMsg_ecu11765" SG_ 128 signal7435 128;
BA_ "signal131970" SG_ 128 signal7435 128;
BA_ "signal131977" SG_ 128 signal7435 128;
BA_ "GenSigTimeoutMsg_ecu13186" SG_ 128 signal7435 128;
BA_ "GenSigTimeoutMsg_ecu12594" SG_ 128 signal7435 128;
BA_ "NMH-WakeupAllowed" SG_ 128 signal7435 0;
BA_ "NWM-WakeupAllowed" SG_ 128 signal7435 0;
BA_ "GenSigStartValue" SG_ 128 signal7435 1022;
BA_ "GenSigSendType" SG_ 128 signal7435 7;
BA_ "GenSigEnvVarType" SG_ 128 signal7435 0;
BA_ "GenSigAutoGenSnd" SG_ 128 signal7435 1;
BA_ "GenSigAutoGenDsp" SG_ 128 signal7435 1;
BA_ "GenSigTimeoutMsg_ecu11765" SG_ 128 signal7450 128;
BA_ "signal131970" SG_ 128 signal7450 128;
BA_ "signal131977" SG_ 128 signal7450 128;
BA_ "GenSigTimeoutMsg_ecu13186" SG_ 128 signal7450 128;
BA_ "NMH-WakeupAllowed" SG_ 128 signal7450 0;
BA_ "NWM-WakeupAllowed" SG_ 128 signal7450 0;
BA_ "GenSigSendType" SG_ 128 signal7450 7;
BA_ "GenSigEnvVarType" SG_ 128 signal7450 0;
BA_ "GenSigAutoGenSnd" SG_ 128 signal7450 1;
BA_ "GenSigAutoGenDsp" SG_ 128 signal7450 1;
BA_ "GenSigTimeoutMsg_ecu13186" SG_ 128 signal7464 128;
BA_ "NMH-WakeupAllowed" SG_ 128 signal7464 0;
BA_ "NWM-WakeupAllowed" SG_ 128 signal7464 0;
BA_ "GenSigSendType" SG_ 128 signal7464 7;
BA_ "GenSigEnvVarType" SG_ 128 signal7464 0;
BA_ "GenSigAutoGenSnd" SG_ 128 signal7464 1;
BA_ "GenSigAutoGenDsp" SG_ 128 signal7464 1;
BA_ "GenSigTimeoutMsg_ecu11765" SG_ 129 signal7481 129;
BA_ "signal131970" SG_ 129 signal7481 129;
BA_ "signal131977" SG_ 129 signal7481 129;
BA_ "GenSigTimeoutMsg_ecu13186" SG_ 129 signal7481 129;
BA_ "NMH-WakeupAllowed" SG_ 129 signal7481 0;
BA_ "NWM-WakeupAllowed" SG_ 129 signal7481 0;
BA_ "GenSigSendType" SG_ 129 signal7481 7;
BA_ "GenSigEnvVarType" SG_ 129 signal7481 0;
BA_ "GenSigAutoGenSnd" SG_ 129 signal7481 1;
BA_ "GenSigAutoGenDsp" SG_ 129 signal7481 1;
BA_ "GenSigTimeoutMsg_ecu11765" SG_ 129 signal7476_BZ 129;
BA_ "signal131970" SG_ 129 signal7476_BZ 129;
BA_ "signal131977" SG_ 129 signal7476_BZ 129;
BA_ "GenSigTimeoutMsg_ecu13186" SG_ 129 signal7476_BZ 129;
BA_ "NMH-WakeupAllowed" SG_ 129 signal7476_BZ 0;
BA_ "NWM-WakeupAllowed" SG_ 129 signal7476_BZ 0;
BA_ "GenSigSendType" SG_ 129 signal7476_BZ 7;
BA_ "GenSigEnvVarType" SG_ 129 signal7476_BZ 0;
BA_ "GenSigAutoGenSnd" SG_ 129 signal7476_BZ 1;
BA_ "GenSigAutoGenDsp" SG_ 129 signal7476_BZ 1;
BA_ "GenSigTimeoutMsg_ecu13186" SG_ 129 signal7509 129;
BA_ "NMH-WakeupAllowed" SG_ 129 signal7509 0;
BA_ "NWM-WakeupAllowed" SG_ 129 signal7509 0;
BA_ "GenSigStartValue" SG_ 129 signal7509 1022;
BA_ "GenSigSendType" SG_ 129 signal7509 7;
BA_ "GenSigEnvVarType" SG_ 129 signal7509 0;
BA_ "GenSigAutoGenSnd" SG_ 129 signal7509 1;
BA_ "GenSigAutoGenDsp" SG_ 129 signal7509 1;
BA_ "GenSigTimeoutMsg_ecu11765" SG_ 129 signal7520 129;
BA_ "signal131970" SG_ 129 signal7520 129;
BA_ "signal131977" SG_ 129 signal7520 129;
BA_ "GenSigTimeoutMsg_ecu13186" SG_ 129 signal7520 129;
BA_ "NMH-WakeupAllowed" SG_ 129 signal7520 0;
BA_ "NWM-WakeupAllowed" SG_ 129 signal7520 0;
BA_ "GenSigStartValue" SG_ 129 signal7520 1022;
BA_ "GenSigSendType" SG_ 129 signal7520 7;
BA_ "GenSigEnvVarType" SG_ 129 signal7520 0;
BA_ "GenSigAutoGenSnd" SG_ 129 signal7520 1;
BA_ "GenSigAutoGenDsp" SG_ 129 signal7520 1;
BA_ "GenSigTimeoutMsg_ecu11765" SG_ 129 signal7534 129;
BA_ "signal131970" SG_ 129 signal7534 129;
BA_ "signal131977" SG_ 129 signal7534 129;
BA_ "GenSigTimeoutMsg_ecu13186" SG_ 129 signal7534 129;
BA_ "NMH-WakeupAllowed" SG_ 129 signal7534 0;
BA_ "NWM-WakeupAllowed" SG_ 129 signal7534 0;
BA_ "GenSigStartValue" SG_ 129 signal7534 1022;
BA_ "GenSigSendType" SG_ 129 signal7534 7;
BA_ "GenSigEnvVarType" SG_ 129 signal7534 0;
BA_ "GenSigAutoGenSnd" SG_ 129 signal7534 1;
BA_ "GenSigAutoGenDsp" SG_ 129 signal7534 1;
BA_ "GenSigTimeoutMsg_ecu11765" SG_ 129 signal7548 129;
BA_ "signal131970" SG_ 129 signal7548 129;
BA_ "signal131977" SG_ 129 signal7548 129;
BA_ "GenSigTimeoutMsg_ecu13186" SG_ 129 signal7548 129;
BA_ "NMH-WakeupAllowed" SG_ 129 signal7548 0;
BA_ "NWM-WakeupAllowed" SG_ 129 signal7548 0;
BA_ "GenSigSendType" SG_ 129 signal7548 7;
BA_ "GenSigEnvVarType" SG_ 129 signal7548 1;
BA_ "GenSigAutoGenSnd" SG_ 129 signal7548 1;
BA_ "GenSigAutoGenDsp" SG_ 129 signal7548 1;
BA_ "signal142820" SG_ 261 signal7563_CHK 261;
BA_ "GenSigTimeoutMsg_ecu11765" SG_ 261 signal7563_CHK 261;
BA_ "signal131970" SG_ 261 signal7563_CHK 261;
BA_ "signal131977" SG_ 261 signal7563_CHK 261;
BA_ "GenSigTimeoutMsg_ecu13186" SG_ 261 signal7563_CHK 261;
BA_ "GenSigTimeoutMsg_ecu12594" SG_ 261 signal7563_CHK 261;
BA_ "NMH-WakeupAllowed" SG_ 261 signal7563_CHK 0;
BA_ "NWM-WakeupAllowed" SG_ 261 signal7563_CHK 0;
BA_ "GenSigSendType" SG_ 261 signal7563_CHK 7;
BA_ "GenSigEnvVarType" SG_ 261 signal7563_CHK 0;
BA_ "GenSigAutoGenSnd" SG_ 261 signal7563_CHK 1;
BA_ "GenSigAutoGenDsp" SG_ 261 signal7563_CHK 1;
BA_ "signal142820" SG_ 261 signal7563_BZ 261;
BA_ "GenSigTimeoutMsg_ecu11765" SG_ 261 signal7563_BZ 261;
BA_ "signal131970" SG_ 261 signal7563_BZ 261;
BA_ "signal131977" SG_ 261 signal7563_BZ 261;
BA_ "GenSigTimeoutMsg_ecu13186" SG_ 261 signal7563_BZ 261;
BA_ "GenSigTimeoutMsg_ecu12594" SG_ 261 signal7563_BZ 261;
BA_ "NMH-WakeupAllowed" SG_ 261 signal7563_BZ 0;
BA_ "NWM-WakeupAllowed" SG_ 261 signal7563_BZ 0;
BA_ "GenSigSendType" SG_ 261 signal7563_BZ 7;
BA_ "GenSigEnvVarType" SG_ 261 signal7563_BZ 0;
BA_ "GenSigAutoGenSnd" SG_ 261 signal7563_BZ 1;
BA_ "GenSigAutoGenDsp" SG_ 261 signal7563_BZ 1;
BA_ "GenSigTimeoutMsg_ecu13186" SG_ 261 signal7600 261;
BA_ "GenSigTimeoutMsg_ecu12594" SG_ 261 signal7600 261;
BA_ "NMH-WakeupAllowed" SG_ 261 signal7600 0;
BA_ "NWM-WakeupAllowed" SG_ 261 signal7600 0;
BA_ "GenSigStartValue" SG_ 261 signal7600 1;
BA_ "GenSigSendType" SG_ 261 signal7600 7;
BA_ "GenSigEnvVarType" SG_ 261 signal7600 0;
BA_ "GenSigAutoGenSnd" SG_ 261 signal7600 1;
BA_ "GenSigAutoGenDsp" SG_ 261 signal7600 1;
BA_ "GenSigTimeoutMsg_ecu11765" SG_ 261 signal7612 261;
BA_ "signal131970" SG_ 261 signal7612 261;
BA_ "signal131977" SG_ 261 signal7612 261;
BA_ "GenSigTimeoutMsg_ecu13186" SG_ 261 signal7612 261;
BA_ "GenSigTimeoutMsg_ecu12594" SG_ 261 signal7612 261;
BA_ "NMH-WakeupAllowed" SG_ 261 signal7612 0;
BA_ "NWM-WakeupAllowed" SG_ 261 signal7612 0;
BA_ "GenSigStartValue" SG_ 261 signal7612 1;
BA_ "GenSigSendType" SG_ 261 signal7612 7;
BA_ "GenSigEnvVarType" SG_ 261 signal7612 0;
BA_ "GenSigAutoGenSnd" SG_ 261 signal7612 1;
BA_ "GenSigAutoGenDsp" SG_ 261 signal7612 1;
BA_ "GenSigTimeoutMsg_ecu11765" SG_ 261 signal7627 261;
BA_ "signal131970" SG_ 261 signal7627 261;
BA_ "signal131977" SG_ 261 signal7627 261;
BA_ "GenSigTimeoutMsg_ecu13186" SG_ 261 signal7627 261;
BA_ "NMH-WakeupAllowed" SG_ 261 signal7627 0;
BA_ "NWM-WakeupAllowed" SG_ 261 signal7627 0;
BA_ "GenSigStartValue" SG_ 261 signal7627 1;
BA_ "GenSigSendType" SG_ 261 signal7627 7;
BA_ "GenSigEnvVarType" SG_ 261 signal7627 0;
BA_ "GenSigAutoGenSnd" SG_ 261 signal7627 1;
BA_ "GenSigAutoGenDsp" SG_ 261 signal7627 1;
BA_ "GenSigTimeoutMsg_ecu12990" SG_ 261 signal7641 261;
BA_ "GenSigTimeoutMsg_ecu13186" SG_ 261 signal7641 261;
BA_ "NMH-WakeupAllowed" SG_ 261 signal7641 0;
BA_ "NWM-WakeupAllowed" SG_ 261 signal7641 0;
BA_ "GenSigStartValue" SG_ 261 signal7641 1;
BA_ "GenSigSendType" SG_ 261 signal7641 7;
BA_ "GenSigEnvVarType" SG_ 261 signal7641 0;
BA_ "GenSigAutoGenSnd" SG_ 261 signal7641 1;
BA_ "GenSigAutoGenDsp" SG_ 261 signal7641 1;
BA_ "GenSigTimeoutMsg_ecu12990" SG_ 261 signal7653 261;
BA_ "signal142820" SG_ 261 signal7653 261;
BA_ "GenSigTimeoutMsg_ecu13186" SG_ 261 signal7653 261;
BA_ "GenSigTimeoutMsg_ecu12594" SG_ 261 signal7653 261;
BA_ "NMH-WakeupAllowed" SG_ 261 signal7653 0;
BA_ "NWM-WakeupAllowed" SG_ 261 signal7653 0;
BA_ "GenSigSendType" SG_ 261 signal7653 7;
BA_ "GenSigEnvVarType" SG_ 261 signal7653 1;
BA_ "GenSigAutoGenSnd" SG_ 261 signal7653 1;
BA_ "GenSigAutoGenDsp" SG_ 261 signal7653 1;
BA_ "GenSigTimeoutMsg_ecu13186" SG_ 261 signal7667 261;
BA_ "NMH-WakeupAllowed" SG_ 261 signal7667 0;
BA_ "NWM-WakeupAllowed" SG_ 261 signal7667 0;
BA_ "GenSigSendType" SG_ 261 signal7667 7;
BA_ "GenSigEnvVarType" SG_ 261 signal7667 0;
BA_ "GenSigAutoGenSnd" SG_ 261 signal7667 1;
BA_ "GenSigAutoGenDsp" SG_ 261 signal7667 1;
BA_ "GenSigTimeoutMsg_ecu13186" SG_ 261 signal7678 261;
BA_ "GenSigTimeoutMsg_ecu12594" SG_ 261 signal7678 261;
BA_ "NMH-WakeupAllowed" SG_ 261 signal7678 0;
BA_ "NWM-WakeupAllowed" SG_ 261 signal7678 0;
BA_ "GenSigSendType" SG_ 261 signal7678 7;
BA_ "GenSigEnvVarType" SG_ 261 signal7678 0;
BA_ "GenSigAutoGenSnd" SG_ 261 signal7678 1;
BA_ "GenSigAutoGenDsp" SG_ 261 signal7678 1;
BA_ "GenSigTimeoutMsg_ecu11765" SG_ 261 signal7690 261;
BA_ "signal131970" SG_ 261 signal7690 261;
BA_ "signal131977" SG_ 261 signal7690 261;
BA_ "GenSigTimeoutMsg_ecu13186" SG_ 261 signal7690 261;
BA_ "GenSigTimeoutMsg_ecu12594" SG_ 261 signal7690 261;
BA_ "NMH-WakeupAllowed" SG_ 261 signal7690 0;
BA_ "NWM-WakeupAllowed" SG_ 261 signal7690 0;
BA_ "GenSigSendType" SG_ 261 signal7690 7;
BA_ "GenSigEnvVarType" SG_ 261 signal7690 0;
BA_ "GenSigAutoGenSnd" SG_ 261 signal7690 1;
BA_ "GenSigAutoGenDsp" SG_ 261 signal7690 1;
BA_ "GenSigTimeoutMsg_ecu11765" SG_ 261 signal7705 261;
BA_ "signal131970" SG_ 261 signal7705 261;
BA_ "signal131977" SG_ 261 signal7705 261;
BA_ "GenSigTimeoutMsg_ecu13186" SG_ 261 signal7705 261;
BA_ "NMH-WakeupAllowed" SG_ 261 signal7705 0;
BA_ "NWM-WakeupAllowed" SG_ 261 signal7705 0;
BA_ "GenSigSendType" SG_ 261 signal7705 7;
BA_ "GenSigEnvVarType" SG_ 261 signal7705 0;
BA_ "GenSigAutoGenSnd" SG_ 261 signal7705 1;
BA_ "GenSigAutoGenDsp" SG_ 261 signal7705 1;
BA_ "GenSigTimeoutMsg_ecu11765" SG_ 261 signal7719 261;
BA_ "signal131970" SG_ 261 signal7719 261;
BA_ "signal131977" SG_ 261 signal7719 261;
BA_ "GenSigTimeoutMsg_ecu13186" SG_ 261 signal7719 261;
BA_ "NMH-WakeupAllowed" SG_ 261 signal7719 0;
BA_ "NWM-WakeupAllowed" SG_ 261 signal7719 0;
BA_ "GenSigSendType" SG_ 261 signal7719 7;
BA_ "GenSigEnvVarType" SG_ 261 signal7719 0;
BA_ "GenSigAutoGenSnd" SG_ 261 signal7719 1;
BA_ "GenSigAutoGenDsp" SG_ 261 signal7719 1;
BA_ "GenSigTimeoutMsg_ecu13186" SG_ 261 signal7733 261;
BA_ "GenSigTimeoutMsg_ecu12594" SG_ 261 signal7733 261;
BA_ "NMH-WakeupAllowed" SG_ 261 signal7733 0;
BA_ "NWM-WakeupAllowed" SG_ 261 signal7733 0;
BA_ "GenSigSendType" SG_ 261 signal7733 7;
BA_ "GenSigEnvVarType" SG_ 261 signal7733 0;
BA_ "GenSigAutoGenSnd" SG_ 261 signal7733 1;
BA_ "GenSigAutoGenDsp" SG_ 261 signal7733 1;
BA_ "GenSigTimeoutMsg_ecu13186" SG_ 261 signal7745 261;
BA_ "NMH-WakeupAllowed" SG_ 261 signal7745 0;
BA_ "NWM-WakeupAllowed" SG_ 261 signal7745 0;
BA_ "GenSigSendType" SG_ 261 signal7745 7;
BA_ "GenSigEnvVarType" SG_ 261 signal7745 0;
BA_ "GenSigAutoGenSnd" SG_ 261 signal7745 1;
BA_ "GenSigAutoGenDsp" SG_ 261 signal7745 1;
BA_ "signal142820" SG_ 261 signal7756 261;
BA_ "GenSigTimeoutMsg_ecu13186" SG_ 261 signal7756 261;
BA_ "GenSigTimeoutMsg_ecu12594" SG_ 261 signal7756 261;
BA_ "NMH-WakeupAllowed" SG_ 261 signal7756 0;
BA_ "NWM-WakeupAllowed" SG_ 261 signal7756 0;
BA_ "GenSigSendType" SG_ 261 signal7756 7;
BA_ "GenSigEnvVarType" SG_ 261 signal7756 0;
BA_ "GenSigAutoGenSnd" SG_ 261 signal7756 1;
BA_ "GenSigAutoGenDsp" SG_ 261 signal7756 1;
BA_ "GenSigTimeoutMsg_ecu11765" SG_ 261 signal7769 261;
BA_ "signal131970" SG_ 261 signal7769 261;
BA_ "signal131977" SG_ 261 signal7769 261;
BA_ "GenSigTimeoutMsg_ecu13186" SG_ 261 signal7769 261;
BA_ "NMH-WakeupAllowed" SG_ 261 signal7769 0;
BA_ "NWM-WakeupAllowed" SG_ 261 signal7769 0;
BA_ "GenSigSendType" SG_ 261 signal7769 7;
BA_ "GenSigEnvVarType" SG_ 261 signal7769 0;
BA_ "GenSigAutoGenSnd" SG_ 261 signal7769 1;
BA_ "GenSigAutoGenDsp" SG_ 261 signal7769 1;
BA_ "GenSigTimeoutMsg_ecu13186" SG_ 261 signal7783 261;
BA_ "GenSigTimeoutMsg_ecu12594" SG_ 261 signal7783 261;
BA_ "NMH-WakeupAllowed" SG_ 261 signal7783 0;
BA_ "NWM-WakeupAllowed" SG_ 261 signal7783 0;
BA_ "GenSigSendType" SG_ 261 signal7783 7;
BA_ "GenSigEnvVarType" SG_ 261 signal7783 1;
BA_ "GenSigAutoGenSnd" SG_ 261 signal7783 1;
BA_ "GenSigAutoGenDsp" SG_ 261 signal7783 1;
BA_ "GenSigTimeoutMsg_ecu11765" SG_ 261 signal7795 261;
BA_ "signal131970" SG_ 261 signal7795 261;
BA_ "signal131977" SG_ 261 signal7795 261;
BA_ "GenSigTimeoutMsg_ecu13186" SG_ 261 signal7795 261;
BA_ "NMH-WakeupAllowed" SG_ 261 signal7795 0;
BA_ "NWM-WakeupAllowed" SG_ 261 signal7795 0;
BA_ "GenSigSendType" SG_ 261 signal7795 7;
BA_ "GenSigEnvVarType" SG_ 261 signal7795 0;
BA_ "GenSigAutoGenSnd" SG_ 261 signal7795 1;
BA_ "GenSigAutoGenDsp" SG_ 261 signal7795 1;
BA_ "GenSigTimeoutMsg_ecu11765" SG_ 261 signal7809 261;
BA_ "signal131970" SG_ 261 signal7809 261;
BA_ "signal131977" SG_ 261 signal7809 261;
BA_ "GenSigTimeoutMsg_ecu13186" SG_ 261 signal7809 261;
BA_ "NMH-WakeupAllowed" SG_ 261 signal7809 0;
BA_ "NWM-WakeupAllowed" SG_ 261 signal7809 0;
BA_ "GenSigStartValue" SG_ 261 signal7809 1;
BA_ "GenSigSendType" SG_ 261 signal7809 7;
BA_ "GenSigEnvVarType" SG_ 261 signal7809 0;
BA_ "GenSigAutoGenSnd" SG_ 261 signal7809 1;
BA_ "GenSigAutoGenDsp" SG_ 261 signal7809 1;
BA_ "GenSigTimeoutMsg_ecu11765" SG_ 261 signal7823 261;
BA_ "signal131970" SG_ 261 signal7823 261;
BA_ "signal131977" SG_ 261 signal7823 261;
BA_ "GenSigTimeoutMsg_ecu13186" SG_ 261 signal7823 261;
BA_ "NMH-WakeupAllowed" SG_ 261 signal7823 0;
BA_ "NWM-WakeupAllowed" SG_ 261 signal7823 0;
BA_ "GenSigSendType" SG_ 261 signal7823 7;
BA_ "GenSigEnvVarType" SG_ 261 signal7823 1;
BA_ "GenSigAutoGenSnd" SG_ 261 signal7823 1;
BA_ "GenSigAutoGenDsp" SG_ 261 signal7823 1;
BA_ "GenSigTimeoutMsg_ecu13186" SG_ 263 signal7843 263;
BA_ "NMH-WakeupAllowed" SG_ 263 signal7843 0;
BA_ "NWM-WakeupAllowed" SG_ 263 signal7843 0;
BA_ "GenSigSendType" SG_ 263 signal7843 7;
BA_ "GenSigEnvVarType" SG_ 263 signal7843 0;
BA_ "GenSigAutoGenSnd" SG_ 263 signal7843 1;
BA_ "GenSigAutoGenDsp" SG_ 263 signal7843 1;
BA_ "GenSigTimeoutMsg_ecu13186" SG_ 263 signal7854 263;
BA_ "NMH-WakeupAllowed" SG_ 263 signal7854 0;
BA_ "NWM-WakeupAllowed" SG_ 263 signal7854 0;
BA_ "GenSigSendType" SG_ 263 signal7854 7;
BA_ "GenSigEnvVarType" SG_ 263 signal7854 1;
BA_ "GenSigAutoGenSnd" SG_ 263 signal7854 1;
BA_ "GenSigAutoGenDsp" SG_ 263 signal7854 1;
BA_ "GenSigTimeoutMsg_ecu13186" SG_ 263 signal7865 263;
BA_ "NMH-WakeupAllowed" SG_ 263 signal7865 0;
BA_ "NWM-WakeupAllowed" SG_ 263 signal7865 0;
BA_ "GenSigSendType" SG_ 263 signal7865 7;
BA_ "GenSigEnvVarType" SG_ 263 signal7865 0;
BA_ "GenSigAutoGenSnd" SG_ 263 signal7865 1;
BA_ "GenSigAutoGenDsp" SG_ 263 signal7865 1;
BA_ "GenSigTimeoutMsg_ecu13186" SG_ 263 signal7876 263;
BA_ "NMH-WakeupAllowed" SG_ 263 signal7876 0;
BA_ "NWM-WakeupAllowed" SG_ 263 signal7876 0;
BA_ "GenSigSendType" SG_ 263 signal7876 7;
BA_ "GenSigEnvVarType" SG_ 263 signal7876 0;
BA_ "GenSigAutoGenSnd" SG_ 263 signal7876 1;
BA_ "GenSigAutoGenDsp" SG_ 263 signal7876 1;
BA_ "GenSigTimeoutMsg_ecu11765" SG_ 782 signal7888_CHK 782;
BA_ "signal131970" SG_ 782 signal7888_CHK 782;
BA_ "signal131977" SG_ 782 signal7888_CHK 782;
BA_ "NMH-WakeupAllowed" SG_ 782 signal7888_CHK 0;
BA_ "NWM-WakeupAllowed" SG_ 782 signal7888_CHK 0;
BA_ "GenSigSendType" SG_ 782 signal7888_CHK 7;
BA_ "GenSigEnvVarType" SG_ 782 signal7888_CHK 0;
BA_ "GenSigAutoGenSnd" SG_ 782 signal7888_CHK 1;
BA_ "GenSigAutoGenDsp" SG_ 782 signal7888_CHK 1;
BA_ "GenSigTimeoutMsg_ecu11765" SG_ 782 signal7888_BZ 782;
BA_ "signal131970" SG_ 782 signal7888_BZ 782;
BA_ "signal131977" SG_ 782 signal7888_BZ 782;
BA_ "NMH-WakeupAllowed" SG_ 782 signal7888_BZ 0;
BA_ "NWM-WakeupAllowed" SG_ 782 signal7888_BZ 0;
BA_ "GenSigSendType" SG_ 782 signal7888_BZ 7;
BA_ "GenSigEnvVarType" SG_ 782 signal7888_BZ 0;
BA_ "GenSigAutoGenSnd" SG_ 782 signal7888_BZ 1;
BA_ "GenSigAutoGenDsp" SG_ 782 signal7888_BZ 1;
BA_ "GenSigTimeoutMsg_ecu13186" SG_ 782 signal7919 782;
BA_ "NMH-WakeupAllowed" SG_ 782 signal7919 0;
BA_ "NWM-WakeupAllowed" SG_ 782 signal7919 0;
BA_ "GenSigSendType" SG_ 782 signal7919 7;
BA_ "GenSigEnvVarType" SG_ 782 signal7919 0;
BA_ "GenSigAutoGenSnd" SG_ 782 signal7919 1;
BA_ "GenSigAutoGenDsp" SG_ 782 signal7919 1;
BA_ "signal131970" SG_ 782 signal7930 782;
BA_ "signal131977" SG_ 782 signal7930 782;
BA_ "NMH-WakeupAllowed" SG_ 782 signal7930 0;
BA_ "NWM-WakeupAllowed" SG_ 782 signal7930 0;
BA_ "GenSigSendType" SG_ 782 signal7930 7;
BA_ "GenSigEnvVarType" SG_ 782 signal7930 0;
BA_ "GenSigAutoGenSnd" SG_ 782 signal7930 1;
BA_ "GenSigAutoGenDsp" SG_ 782 signal7930 1;
BA_ "signal131970" SG_ 782 signal7942 782;
BA_ "signal131977" SG_ 782 signal7942 782;
BA_ "NMH-WakeupAllowed" SG_ 782 signal7942 0;
BA_ "NWM-WakeupAllowed" SG_ 782 signal7942 0;
BA_ "GenSigSendType" SG_ 782 signal7942 7;
BA_ "GenSigEnvVarType" SG_ 782 signal7942 0;
BA_ "GenSigAutoGenSnd" SG_ 782 signal7942 1;
BA_ "GenSigAutoGenDsp" SG_ 782 signal7942 1;
BA_ "signal131970" SG_ 782 signal7954 782;
BA_ "signal131977" SG_ 782 signal7954 782;
BA_ "NMH-WakeupAllowed" SG_ 782 signal7954 0;
BA_ "NWM-WakeupAllowed" SG_ 782 signal7954 0;
BA_ "GenSigSendType" SG_ 782 signal7954 7;
BA_ "GenSigEnvVarType" SG_ 782 signal7954 0;
BA_ "GenSigAutoGenSnd" SG_ 782 signal7954 1;
BA_ "GenSigAutoGenDsp" SG_ 782 signal7954 1;
BA_ "GenSigTimeoutMsg_ecu11765" SG_ 782 signal7966 782;
BA_ "signal131970" SG_ 782 signal7966 782;
BA_ "signal131977" SG_ 782 signal7966 782;
BA_ "NMH-WakeupAllowed" SG_ 782 signal7966 0;
BA_ "NWM-WakeupAllowed" SG_ 782 signal7966 0;
BA_ "GenSigSendType" SG_ 782 signal7966 7;
BA_ "GenSigEnvVarType" SG_ 782 signal7966 0;
BA_ "GenSigAutoGenSnd" SG_ 782 signal7966 1;
BA_ "GenSigAutoGenDsp" SG_ 782 signal7966 1;
BA_ "GenSigTimeoutMsg_ecu13186" SG_ 782 signal7979 782;
BA_ "NMH-WakeupAllowed" SG_ 782 signal7979 0;
BA_ "NWM-WakeupAllowed" SG_ 782 signal7979 0;
BA_ "GenSigSendType" SG_ 782 signal7979 7;
BA_ "GenSigEnvVarType" SG_ 782 signal7979 0;
BA_ "GenSigAutoGenSnd" SG_ 782 signal7979 1;
BA_ "GenSigAutoGenDsp" SG_ 782 signal7979 1;
BA_ "GenSigTimeoutMsg_ecu13186" SG_ 782 signal7990 782;
BA_ "NMH-WakeupAllowed" SG_ 782 signal7990 0;
BA_ "NWM-WakeupAllowed" SG_ 782 signal7990 0;
BA_ "GenSigSendType" SG_ 782 signal7990 7;
BA_ "GenSigEnvVarType" SG_ 782 signal7990 0;
BA_ "GenSigAutoGenSnd" SG_ 782 signal7990 1;
BA_ "GenSigAutoGenDsp" SG_ 782 signal7990 1;
BA_ "GenSigTimeoutMsg_ecu11765" SG_ 782 signal8001 782;
BA_ "signal131970" SG_ 782 signal8001 782;
BA_ "signal131977" SG_ 782 signal8001 782;
BA_ "NMH-WakeupAllowed" SG_ 782 signal8001 0;
BA_ "NWM-WakeupAllowed" SG_ 782 signal8001 0;
BA_ "GenSigSendType" SG_ 782 signal8001 7;
BA_ "GenSigEnvVarType" SG_ 782 signal8001 0;
BA_ "GenSigAutoGenSnd" SG_ 782 signal8001 1;
BA_ "GenSigAutoGenDsp" SG_ 782 signal8001 1;
BA_ "GenSigTimeoutMsg_ecu11765" SG_ 782 signal8014 782;
BA_ "signal131970" SG_ 782 signal8014 782;
BA_ "signal131977" SG_ 782 signal8014 782;
BA_ "NMH-WakeupAllowed" SG_ 782 signal8014 0;
BA_ "NWM-WakeupAllowed" SG_ 782 signal8014 0;
BA_ "GenSigSendType" SG_ 782 signal8014 7;
BA_ "GenSigEnvVarType" SG_ 782 signal8014 0;
BA_ "GenSigAutoGenSnd" SG_ 782 signal8014 1;
BA_ "GenSigAutoGenDsp" SG_ 782 signal8014 1;
BA_ "signal131970" SG_ 782 signal8027 782;
BA_ "signal131977" SG_ 782 signal8027 782;
BA_ "NMH-WakeupAllowed" SG_ 782 signal8027 0;
BA_ "NWM-WakeupAllowed" SG_ 782 signal8027 0;
BA_ "GenSigSendType" SG_ 782 signal8027 7;
BA_ "GenSigEnvVarType" SG_ 782 signal8027 0;
BA_ "GenSigAutoGenSnd" SG_ 782 signal8027 1;
BA_ "GenSigAutoGenDsp" SG_ 782 signal8027 1;
BA_ "NMH-WakeupAllowed" SG_ 782 signal8039 0;
BA_ "NWM-WakeupAllowed" SG_ 782 signal8039 0;
BA_ "GenSigSendType" SG_ 782 signal8039 7;
BA_ "GenSigEnvVarType" SG_ 782 signal8039 0;
BA_ "GenSigAutoGenSnd" SG_ 782 signal8039 1;
BA_ "GenSigAutoGenDsp" SG_ 782 signal8039 1;
BA_ "NMH-WakeupAllowed" SG_ 782 signal8049 0;
BA_ "NWM-WakeupAllowed" SG_ 782 signal8049 0;
BA_ "GenSigSendType" SG_ 782 signal8049 7;
BA_ "GenSigEnvVarType" SG_ 782 signal8049 0;
BA_ "GenSigAutoGenSnd" SG_ 782 signal8049 1;
BA_ "GenSigAutoGenDsp" SG_ 782 signal8049 1;
BA_ "GenSigTimeoutMsg_ecu13186" SG_ 782 signal8059 782;
BA_ "NMH-WakeupAllowed" SG_ 782 signal8059 0;
BA_ "NWM-WakeupAllowed" SG_ 782 signal8059 0;
BA_ "GenSigSendType" SG_ 782 signal8059 7;
BA_ "GenSigEnvVarType" SG_ 782 signal8059 0;
BA_ "GenSigAutoGenSnd" SG_ 782 signal8059 1;
BA_ "GenSigAutoGenDsp" SG_ 782 signal8059 1;
BA_ "GenSigTimeoutMsg_ecu13186" SG_ 782 signal8070 782;
BA_ "NMH-WakeupAllowed" SG_ 782 signal8070 0;
BA_ "NWM-WakeupAllowed" SG_ 782 signal8070 0;
BA_ "GenSigSendType" SG_ 782 signal8070 7;
BA_ "GenSigEnvVarType" SG_ 782 signal8070 0;
BA_ "GenSigAutoGenSnd" SG_ 782 signal8070 1;
BA_ "GenSigAutoGenDsp" SG_ 782 signal8070 1;
BA_ "GenSigTimeoutMsg_ecu13186" SG_ 782 signal8081 782;
BA_ "NMH-WakeupAllowed" SG_ 782 signal8081 0;
BA_ "NWM-WakeupAllowed" SG_ 782 signal8081 0;
BA_ "GenSigStartValue" SG_ 782 signal8081 1;
BA_ "GenSigSendType" SG_ 782 signal8081 7;
BA_ "GenSigEnvVarType" SG_ 782 signal8081 0;
BA_ "GenSigAutoGenSnd" SG_ 782 signal8081 1;
BA_ "GenSigAutoGenDsp" SG_ 782 signal8081 1;
BA_ "GenSigTimeoutMsg_ecu13186" SG_ 782 signal8092 782;
BA_ "NMH-WakeupAllowed" SG_ 782 signal8092 0;
BA_ "NWM-WakeupAllowed" SG_ 782 signal8092 0;
BA_ "GenSigSendType" SG_ 782 signal8092 7;
BA_ "GenSigEnvVarType" SG_ 782 signal8092 0;
BA_ "GenSigAutoGenSnd" SG_ 782 signal8092 1;
BA_ "GenSigAutoGenDsp" SG_ 782 signal8092 1;
BA_ "GenSigTimeoutMsg_ecu13186" SG_ 782 signal8103 782;
BA_ "NMH-WakeupAllowed" SG_ 782 signal8103 0;
BA_ "NWM-WakeupAllowed" SG_ 782 signal8103 0;
BA_ "GenSigSendType" SG_ 782 signal8103 7;
BA_ "GenSigEnvVarType" SG_ 782 signal8103 0;
BA_ "GenSigAutoGenSnd" SG_ 782 signal8103 1;
BA_ "GenSigAutoGenDsp" SG_ 782 signal8103 1;
BA_ "GenSigTimeoutMsg_ecu13186" SG_ 782 signal8114 782;
BA_ "NMH-WakeupAllowed" SG_ 782 signal8114 0;
BA_ "NWM-WakeupAllowed" SG_ 782 signal8114 0;
BA_ "GenSigSendType" SG_ 782 signal8114 7;
BA_ "GenSigEnvVarType" SG_ 782 signal8114 0;
BA_ "GenSigAutoGenSnd" SG_ 782 signal8114 1;
BA_ "GenSigAutoGenDsp" SG_ 782 signal8114 1;
BA_ "GenSigTimeoutMsg_ecu13186" SG_ 782 signal4168 782;
BA_ "NMH-WakeupAllowed" SG_ 782 signal4168 0;
BA_ "NWM-WakeupAllowed" SG_ 782 signal4168 0;
BA_ "GenSigSendType" SG_ 782 signal4168 7;
BA_ "GenSigEnvVarType" SG_ 782 signal4168 0;
BA_ "GenSigAutoGenSnd" SG_ 782 signal4168 1;
BA_ "GenSigAutoGenDsp" SG_ 782 signal4168 1;
BA_ "GenSigTimeoutMsg_ecu11765" SG_ 782 signal8136 782;
BA_ "signal131970" SG_ 782 signal8136 782;
BA_ "signal131977" SG_ 782 signal8136 782;
BA_ "NMH-WakeupAllowed" SG_ 782 signal8136 0;
BA_ "NWM-WakeupAllowed" SG_ 782 signal8136 0;
BA_ "GenSigSendType" SG_ 782 signal8136 7;
BA_ "GenSigEnvVarType" SG_ 782 signal8136 0;
BA_ "GenSigAutoGenSnd" SG_ 782 signal8136 1;
BA_ "GenSigAutoGenDsp" SG_ 782 signal8136 1;
BA_ "GenSigTimeoutMsg_ecu11765" SG_ 782 signal8149 782;
BA_ "signal131970" SG_ 782 signal8149 782;
BA_ "signal131977" SG_ 782 signal8149 782;
BA_ "NMH-WakeupAllowed" SG_ 782 signal8149 0;
BA_ "NWM-WakeupAllowed" SG_ 782 signal8149 0;
BA_ "GenSigSendType" SG_ 782 signal8149 7;
BA_ "GenSigEnvVarType" SG_ 782 signal8149 1;
BA_ "GenSigAutoGenSnd" SG_ 782 signal8149 1;
BA_ "GenSigAutoGenDsp" SG_ 782 signal8149 1;
BA_ "GenSigTimeoutMsg_ecu13186" SG_ 1088 signal8168 1088;
BA_ "NMH-WakeupAllowed" SG_ 1088 signal8168 0;
BA_ "NWM-WakeupAllowed" SG_ 1088 signal8168 0;
BA_ "GenSigSendType" SG_ 1088 signal8168 7;
BA_ "GenSigEnvVarType" SG_ 1088 signal8168 0;
BA_ "GenSigAutoGenSnd" SG_ 1088 signal8168 1;
BA_ "GenSigAutoGenDsp" SG_ 1088 signal8168 1;
BA_ "GenSigTimeoutMsg_ecu13186" SG_ 1088 signal8179 1088;
BA_ "NMH-WakeupAllowed" SG_ 1088 signal8179 0;
BA_ "NWM-WakeupAllowed" SG_ 1088 signal8179 0;
BA_ "GenSigSendType" SG_ 1088 signal8179 7;
BA_ "GenSigEnvVarType" SG_ 1088 signal8179 0;
BA_ "GenSigAutoGenSnd" SG_ 1088 signal8179 1;
BA_ "GenSigAutoGenDsp" SG_ 1088 signal8179 1;
BA_ "GenSigTimeoutMsg_ecu13186" SG_ 1088 signal8190 1088;
BA_ "NMH-WakeupAllowed" SG_ 1088 signal8190 0;
BA_ "NWM-WakeupAllowed" SG_ 1088 signal8190 0;
BA_ "GenSigSendType" SG_ 1088 signal8190 7;
BA_ "GenSigEnvVarType" SG_ 1088 signal8190 0;
BA_ "GenSigAutoGenSnd" SG_ 1088 signal8190 1;
BA_ "GenSigAutoGenDsp" SG_ 1088 signal8190 1;
BA_ "GenSigTimeoutMsg_ecu13186" SG_ 1088 signal8201 1088;
BA_ "NMH-WakeupAllowed" SG_ 1088 signal8201 0;
BA_ "NWM-WakeupAllowed" SG_ 1088 signal8201 0;
BA_ "GenSigSendType" SG_ 1088 signal8201 7;
BA_ "GenSigEnvVarType" SG_ 1088 signal8201 0;
BA_ "GenSigAutoGenSnd" SG_ 1088 signal8201 1;
BA_ "GenSigAutoGenDsp" SG_ 1088 signal8201 1;
BA_ "GenSigTimeoutMsg_ecu13186" SG_ 1088 signal8212 1088;
BA_ "NMH-WakeupAllowed" SG_ 1088 signal8212 0;
BA_ "NWM-WakeupAllowed" SG_ 1088 signal8212 0;
BA_ "GenSigSendType" SG_ 1088 signal8212 7;
BA_ "GenSigEnvVarType" SG_ 1088 signal8212 1;
BA_ "GenSigAutoGenSnd" SG_ 1088 signal8212 1;
BA_ "GenSigAutoGenDsp" SG_ 1088 signal8212 1;
BA_ "GenSigTimeoutMsg_ecu13186" SG_ 1088 signal8223 1088;
BA_ "NMH-WakeupAllowed" SG_ 1088 signal8223 0;
BA_ "NWM-WakeupAllowed" SG_ 1088 signal8223 0;
BA_ "GenSigSendType" SG_ 1088 signal8223 7;
BA_ "GenSigEnvVarType" SG_ 1088 signal8223 0;
BA_ "GenSigAutoGenSnd" SG_ 1088 signal8223 1;
BA_ "GenSigAutoGenDsp" SG_ 1088 signal8223 1;
BA_ "GenSigTimeoutMsg_ecu13186" SG_ 1088 signal8234 1088;
BA_ "NMH-WakeupAllowed" SG_ 1088 signal8234 0;
BA_ "NWM-WakeupAllowed" SG_ 1088 signal8234 0;
BA_ "GenSigSendType" SG_ 1088 signal8234 7;
BA_ "GenSigEnvVarType" SG_ 1088 signal8234 0;
BA_ "GenSigAutoGenSnd" SG_ 1088 signal8234 1;
BA_ "GenSigAutoGenDsp" SG_ 1088 signal8234 1;
BA_ "GenSigTimeoutMsg_ecu13186" SG_ 1088 signal8245 1088;
BA_ "NMH-WakeupAllowed" SG_ 1088 signal8245 0;
BA_ "NWM-WakeupAllowed" SG_ 1088 signal8245 0;
BA_ "GenSigSendType" SG_ 1088 signal8245 7;
BA_ "GenSigEnvVarType" SG_ 1088 signal8245 0;
BA_ "GenSigAutoGenSnd" SG_ 1088 signal8245 1;
BA_ "GenSigAutoGenDsp" SG_ 1088 signal8245 1;
BA_ "GenSigTimeoutMsg_ecu13186" SG_ 1088 signal8256 1088;
BA_ "NMH-WakeupAllowed" SG_ 1088 signal8256 0;
BA_ "NWM-WakeupAllowed" SG_ 1088 signal8256 0;
BA_ "GenSigSendType" SG_ 1088 signal8256 7;
BA_ "GenSigEnvVarType" SG_ 1088 signal8256 0;
BA_ "GenSigAutoGenSnd" SG_ 1088 signal8256 1;
BA_ "GenSigAutoGenDsp" SG_ 1088 signal8256 1;
BA_ "GenSigTimeoutMsg_ecu13186" SG_ 1088 signal8267 1088;
BA_ "NMH-WakeupAllowed" SG_ 1088 signal8267 0;
BA_ "NWM-WakeupAllowed" SG_ 1088 signal8267 0;
BA_ "GenSigSendType" SG_ 1088 signal8267 7;
BA_ "GenSigEnvVarType" SG_ 1088 signal8267 0;
BA_ "GenSigAutoGenSnd" SG_ 1088 signal8267 1;
BA_ "GenSigAutoGenDsp" SG_ 1088 signal8267 1;
BA_ "GenSigTimeoutMsg_ecu13186" SG_ 1088 signal8278 1088;
BA_ "NMH-WakeupAllowed" SG_ 1088 signal8278 0;
BA_ "NWM-WakeupAllowed" SG_ 1088 signal8278 0;
BA_ "GenSigSendType" SG_ 1088 signal8278 7;
BA_ "GenSigEnvVarType" SG_ 1088 signal8278 0;
BA_ "GenSigAutoGenSnd" SG_ 1088 signal8278 1;
BA_ "GenSigAutoGenDsp" SG_ 1088 signal8278 1;
BA_ "GenSigTimeoutMsg_ecu13186" SG_ 1088 signal8289 1088;
BA_ "NMH-WakeupAllowed" SG_ 1088 signal8289 0;
BA_ "NWM-WakeupAllowed" SG_ 1088 signal8289 0;
BA_ "GenSigSendType" SG_ 1088 signal8289 7;
BA_ "GenSigEnvVarType" SG_ 1088 signal8289 0;
BA_ "GenSigAutoGenSnd" SG_ 1088 signal8289 1;
BA_ "GenSigAutoGenDsp" SG_ 1088 signal8289 1;
BA_ "GenSigTimeoutMsg_ecu13186" SG_ 1088 signal8300 1088;
BA_ "NMH-WakeupAllowed" SG_ 1088 signal8300 0;
BA_ "NWM-WakeupAllowed" SG_ 1088 signal8300 0;
BA_ "GenSigSendType" SG_ 1088 signal8300 7;
BA_ "GenSigEnvVarType" SG_ 1088 signal8300 0;
BA_ "GenSigAutoGenSnd" SG_ 1088 signal8300 1;
BA_ "GenSigAutoGenDsp" SG_ 1088 signal8300 1;
BA_ "GenSigTimeoutMsg_ecu13186" SG_ 1088 signal8311 1088;
BA_ "NMH-WakeupAllowed" SG_ 1088 signal8311 0;
BA_ "NWM-WakeupAllowed" SG_ 1088 signal8311 0;
BA_ "GenSigSendType" SG_ 1088 signal8311 7;
BA_ "GenSigEnvVarType" SG_ 1088 signal8311 0;
BA_ "GenSigAutoGenSnd" SG_ 1088 signal8311 1;
BA_ "GenSigAutoGenDsp" SG_ 1088 signal8311 1;
BA_ "GenSigTimeoutMsg_ecu13186" SG_ 1088 signal8322 1088;
BA_ "NMH-WakeupAllowed" SG_ 1088 signal8322 0;
BA_ "NWM-WakeupAllowed" SG_ 1088 signal8322 0;
BA_ "GenSigSendType" SG_ 1088 signal8322 7;
BA_ "GenSigEnvVarType" SG_ 1088 signal8322 0;
BA_ "GenSigAutoGenSnd" SG_ 1088 signal8322 1;
BA_ "GenSigAutoGenDsp" SG_ 1088 signal8322 1;
BA_ "GenSigTimeoutMsg_ecu13186" SG_ 1088 signal8333 1088;
BA_ "NMH-WakeupAllowed" SG_ 1088 signal8333 0;
BA_ "NWM-WakeupAllowed" SG_ 1088 signal8333 0;
BA_ "GenSigSendType" SG_ 1088 signal8333 7;
BA_ "GenSigEnvVarType" SG_ 1088 signal8333 0;
BA_ "GenSigAutoGenSnd" SG_ 1088 signal8333 1;
BA_ "GenSigAutoGenDsp" SG_ 1088 signal8333 1;
BA_ "GenSigTimeoutMsg_ecu13186" SG_ 1088 signal8344 1088;
BA_ "NMH-WakeupAllowed" SG_ 1088 signal8344 0;
BA_ "NWM-WakeupAllowed" SG_ 1088 signal8344 0;
BA_ "GenSigSendType" SG_ 1088 signal8344 7;
BA_ "GenSigEnvVarType" SG_ 1088 signal8344 0;
BA_ "GenSigAutoGenSnd" SG_ 1088 signal8344 1;
BA_ "GenSigAutoGenDsp" SG_ 1088 signal8344 1;
BA_ "GenSigTimeoutMsg_ecu13186" SG_ 1088 signal8355 1088;
BA_ "NMH-WakeupAllowed" SG_ 1088 signal8355 0;
BA_ "NWM-WakeupAllowed" SG_ 1088 signal8355 0;
BA_ "GenSigSendType" SG_ 1088 signal8355 7;
BA_ "GenSigEnvVarType" SG_ 1088 signal8355 0;
BA_ "GenSigAutoGenSnd" SG_ 1088 signal8355 1;
BA_ "GenSigAutoGenDsp" SG_ 1088 signal8355 1;
BA_ "GenSigTimeoutMsg_ecu13186" SG_ 1088 signal8366 1088;
BA_ "NMH-WakeupAllowed" SG_ 1088 signal8366 0;
BA_ "NWM-WakeupAllowed" SG_ 1088 signal8366 0;
BA_ "GenSigSendType" SG_ 1088 signal8366 7;
BA_ "GenSigEnvVarType" SG_ 1088 signal8366 0;
BA_ "GenSigAutoGenSnd" SG_ 1088 signal8366 1;
BA_ "GenSigAutoGenDsp" SG_ 1088 signal8366 1;
BA_ "GenSigTimeoutMsg_ecu13186" SG_ 1088 signal8377 1088;
BA_ "NMH-WakeupAllowed" SG_ 1088 signal8377 0;
BA_ "NWM-WakeupAllowed" SG_ 1088 signal8377 0;
BA_ "GenSigSendType" SG_ 1088 signal8377 7;
BA_ "GenSigEnvVarType" SG_ 1088 signal8377 0;
BA_ "GenSigAutoGenSnd" SG_ 1088 signal8377 1;
BA_ "GenSigAutoGenDsp" SG_ 1088 signal8377 1;
BA_ "GenSigTimeoutMsg_ecu13186" SG_ 1088 signal8388 1088;
BA_ "NMH-WakeupAllowed" SG_ 1088 signal8388 0;
BA_ "NWM-WakeupAllowed" SG_ 1088 signal8388 0;
BA_ "GenSigSendType" SG_ 1088 signal8388 7;
BA_ "GenSigEnvVarType" SG_ 1088 signal8388 0;
BA_ "GenSigAutoGenSnd" SG_ 1088 signal8388 1;
BA_ "GenSigAutoGenDsp" SG_ 1088 signal8388 1;
BA_ "GenSigTimeoutMsg_ecu13186" SG_ 1088 signal8399 1088;
BA_ "NMH-WakeupAllowed" SG_ 1088 signal8399 0;
BA_ "NWM-WakeupAllowed" SG_ 1088 signal8399 0;
BA_ "GenSigSendType" SG_ 1088 signal8399 7;
BA_ "GenSigEnvVarType" SG_ 1088 signal8399 0;
BA_ "GenSigAutoGenSnd" SG_ 1088 signal8399 1;
BA_ "GenSigAutoGenDsp" SG_ 1088 signal8399 1;
BA_ "GenSigTimeoutMsg_ecu13186" SG_ 1088 signal8410 1088;
BA_ "NMH-WakeupAllowed" SG_ 1088 signal8410 0;
BA_ "NWM-WakeupAllowed" SG_ 1088 signal8410 0;
BA_ "GenSigSendType" SG_ 1088 signal8410 7;
BA_ "GenSigEnvVarType" SG_ 1088 signal8410 0;
BA_ "GenSigAutoGenSnd" SG_ 1088 signal8410 1;
BA_ "GenSigAutoGenDsp" SG_ 1088 signal8410 1;
BA_ "GenSigTimeoutMsg_ecu13186" SG_ 1088 signal8421 1088;
BA_ "NMH-WakeupAllowed" SG_ 1088 signal8421 0;
BA_ "NWM-WakeupAllowed" SG_ 1088 signal8421 0;
BA_ "GenSigSendType" SG_ 1088 signal8421 7;
BA_ "GenSigEnvVarType" SG_ 1088 signal8421 0;
BA_ "GenSigAutoGenSnd" SG_ 1088 signal8421 1;
BA_ "GenSigAutoGenDsp" SG_ 1088 signal8421 1;
BA_ "GenSigTimeoutMsg_ecu13186" SG_ 1088 signal8432 1088;
BA_ "NMH-WakeupAllowed" SG_ 1088 signal8432 0;
BA_ "NWM-WakeupAllowed" SG_ 1088 signal8432 0;
BA_ "GenSigSendType" SG_ 1088 signal8432 7;
BA_ "GenSigEnvVarType" SG_ 1088 signal8432 0;
BA_ "GenSigAutoGenSnd" SG_ 1088 signal8432 1;
BA_ "GenSigAutoGenDsp" SG_ 1088 signal8432 1;
BA_ "GenSigTimeoutMsg_ecu13186" SG_ 1088 signal8443 1088;
BA_ "NMH-WakeupAllowed" SG_ 1088 signal8443 0;
BA_ "NWM-WakeupAllowed" SG_ 1088 signal8443 0;
BA_ "GenSigSendType" SG_ 1088 signal8443 7;
BA_ "GenSigEnvVarType" SG_ 1088 signal8443 0;
BA_ "GenSigAutoGenSnd" SG_ 1088 signal8443 1;
BA_ "GenSigAutoGenDsp" SG_ 1088 signal8443 1;
BA_ "GenSigTimeoutMsg_ecu13186" SG_ 1088 signal8454 1088;
BA_ "NMH-WakeupAllowed" SG_ 1088 signal8454 0;
BA_ "NWM-WakeupAllowed" SG_ 1088 signal8454 0;
BA_ "GenSigSendType" SG_ 1088 signal8454 7;
BA_ "GenSigEnvVarType" SG_ 1088 signal8454 0;
BA_ "GenSigAutoGenSnd" SG_ 1088 signal8454 1;
BA_ "GenSigAutoGenDsp" SG_ 1088 signal8454 1;
BA_ "GenSigTimeoutMsg_ecu11765" SG_ 1600 signal8471 1600;
BA_ "signal131970" SG_ 1600 signal8471 1600;
BA_ "signal131977" SG_ 1600 signal8471 1600;
BA_ "GenSigTimeoutMsg_ecu13186" SG_ 1600 signal8471 1600;
BA_ "NMH-WakeupAllowed" SG_ 1600 signal8471 0;
BA_ "NWM-WakeupAllowed" SG_ 1600 signal8471 0;
BA_ "GenSigStartValue" SG_ 1600 signal8471 1;
BA_ "GenSigSendType" SG_ 1600 signal8471 7;
BA_ "GenSigEnvVarType" SG_ 1600 signal8471 0;
BA_ "GenSigAutoGenSnd" SG_ 1600 signal8471 1;
BA_ "GenSigAutoGenDsp" SG_ 1600 signal8471 1;
BA_ "GenSigTimeoutMsg_ecu13186" SG_ 1600 signal8485 1600;
BA_ "NMH-WakeupAllowed" SG_ 1600 signal8485 0;
BA_ "NWM-WakeupAllowed" SG_ 1600 signal8485 0;
BA_ "GenSigStartValue" SG_ 1600 signal8485 1;
BA_ "GenSigSendType" SG_ 1600 signal8485 7;
BA_ "GenSigEnvVarType" SG_ 1600 signal8485 0;
BA_ "GenSigAutoGenSnd" SG_ 1600 signal8485 1;
BA_ "GenSigAutoGenDsp" SG_ 1600 signal8485 1;
BA_ "GenSigTimeoutMsg_ecu12990" SG_ 1600 signal8496 1600;
BA_ "GenSigTimeoutMsg_ecu11765" SG_ 1600 signal8496 1600;
BA_ "signal131970" SG_ 1600 signal8496 1600;
BA_ "signal131977" SG_ 1600 signal8496 1600;
BA_ "GenSigTimeoutMsg_ecu13186" SG_ 1600 signal8496 1600;
BA_ "NMH-WakeupAllowed" SG_ 1600 signal8496 0;
BA_ "NWM-WakeupAllowed" SG_ 1600 signal8496 0;
BA_ "GenSigStartValue" SG_ 1600 signal8496 1;
BA_ "GenSigSendType" SG_ 1600 signal8496 7;
BA_ "GenSigEnvVarType" SG_ 1600 signal8496 0;
BA_ "GenSigAutoGenSnd" SG_ 1600 signal8496 1;
BA_ "GenSigAutoGenDsp" SG_ 1600 signal8496 1;
BA_ "GenSigTimeoutMsg_ecu11765" SG_ 1600 signal8511 1600;
BA_ "signal131970" SG_ 1600 signal8511 1600;
BA_ "signal131977" SG_ 1600 signal8511 1600;
BA_ "GenSigTimeoutMsg_ecu13186" SG_ 1600 signal8511 1600;
BA_ "NMH-WakeupAllowed" SG_ 1600 signal8511 0;
BA_ "NWM-WakeupAllowed" SG_ 1600 signal8511 0;
BA_ "GenSigStartValue" SG_ 1600 signal8511 254;
BA_ "GenSigSendType" SG_ 1600 signal8511 7;
BA_ "GenSigEnvVarType" SG_ 1600 signal8511 1;
BA_ "GenSigAutoGenSnd" SG_ 1600 signal8511 1;
BA_ "GenSigAutoGenDsp" SG_ 1600 signal8511 1;
BA_ "GenSigTimeoutMsg_ecu13186" SG_ 1600 signal8525 1600;
BA_ "NMH-WakeupAllowed" SG_ 1600 signal8525 0;
BA_ "NWM-WakeupAllowed" SG_ 1600 signal8525 0;
BA_ "GenSigStartValue" SG_ 1600 signal8525 254;
BA_ "GenSigSendType" SG_ 1600 signal8525 7;
BA_ "GenSigEnvVarType" SG_ 1600 signal8525 0;
BA_ "GenSigAutoGenSnd" SG_ 1600 signal8525 1;
BA_ "GenSigAutoGenDsp" SG_ 1600 signal8525 1;
BA_ "GenSigTimeoutMsg_ecu12990" SG_ 1600 signal8536 1600;
BA_ "GenSigTimeoutMsg_ecu11765" SG_ 1600 signal8536 1600;
BA_ "signal131970" SG_ 1600 signal8536 1600;
BA_ "signal131977" SG_ 1600 signal8536 1600;
BA_ "GenSigTimeoutMsg_ecu13186" SG_ 1600 signal8536 1600;
BA_ "NMH-WakeupAllowed" SG_ 1600 signal8536 0;
BA_ "NWM-WakeupAllowed" SG_ 1600 signal8536 0;
BA_ "GenSigStartValue" SG_ 1600 signal8536 254;
BA_ "GenSigSendType" SG_ 1600 signal8536 7;
BA_ "GenSigEnvVarType" SG_ 1600 signal8536 1;
BA_ "GenSigAutoGenSnd" SG_ 1600 signal8536 1;
BA_ "GenSigAutoGenDsp" SG_ 1600 signal8536 1;
BA_ "GenSigTimeoutMsg_ecu11765" SG_ 1600 signal8551 1600;
BA_ "signal131970" SG_ 1600 signal8551 1600;
BA_ "signal131977" SG_ 1600 signal8551 1600;
BA_ "GenSigTimeoutMsg_ecu13186" SG_ 1600 signal8551 1600;
BA_ "NMH-WakeupAllowed" SG_ 1600 signal8551 0;
BA_ "NWM-WakeupAllowed" SG_ 1600 signal8551 0;
BA_ "GenSigSendType" SG_ 1600 signal8551 7;
BA_ "GenSigEnvVarType" SG_ 1600 signal8551 1;
BA_ "GenSigAutoGenSnd" SG_ 1600 signal8551 1;
BA_ "GenSigAutoGenDsp" SG_ 1600 signal8551 1;
BA_ "GenSigTimeoutMsg_ecu13186" SG_ 1600 signal8565 1600;
BA_ "NMH-WakeupAllowed" SG_ 1600 signal8565 0;
BA_ "NWM-WakeupAllowed" SG_ 1600 signal8565 0;
BA_ "GenSigSendType" SG_ 1600 signal8565 7;
BA_ "GenSigEnvVarType" SG_ 1600 signal8565 0;
BA_ "GenSigAutoGenSnd" SG_ 1600 signal8565 1;
BA_ "GenSigAutoGenDsp" SG_ 1600 signal8565 1;
BA_ "GenSigTimeoutMsg_ecu13186" SG_ 1600 signal8576 1600;
BA_ "NMH-WakeupAllowed" SG_ 1600 signal8576 0;
BA_ "NWM-WakeupAllowed" SG_ 1600 signal8576 0;
BA_ "GenSigSendType" SG_ 1600 signal8576 7;
BA_ "GenSigEnvVarType" SG_ 1600 signal8576 0;
BA_ "GenSigAutoGenSnd" SG_ 1600 signal8576 1;
BA_ "GenSigAutoGenDsp" SG_ 1600 signal8576 1;
BA_ "GenSigTimeoutMsg_ecu11765" SG_ 1600 signal8587 1600;
BA_ "signal131970" SG_ 1600 signal8587 1600;
BA_ "signal131977" SG_ 1600 signal8587 1600;
BA_ "GenSigTimeoutMsg_ecu13186" SG_ 1600 signal8587 1600;
BA_ "NMH-WakeupAllowed" SG_ 1600 signal8587 0;
BA_ "NWM-WakeupAllowed" SG_ 1600 signal8587 0;
BA_ "GenSigSendType" SG_ 1600 signal8587 7;
BA_ "GenSigEnvVarType" SG_ 1600 signal8587 1;
BA_ "GenSigAutoGenSnd" SG_ 1600 signal8587 1;
BA_ "GenSigAutoGenDsp" SG_ 1600 signal8587 1;
